[part 1 of 2: packages /AUTOSAR_Dcm/SwComponentTypes to /AUTOSAR_Dcm/PortInterfaces]
AUTOSAR XML (schema 4-2-2)
package /AUTOSAR_Dcm/SwComponentTypes
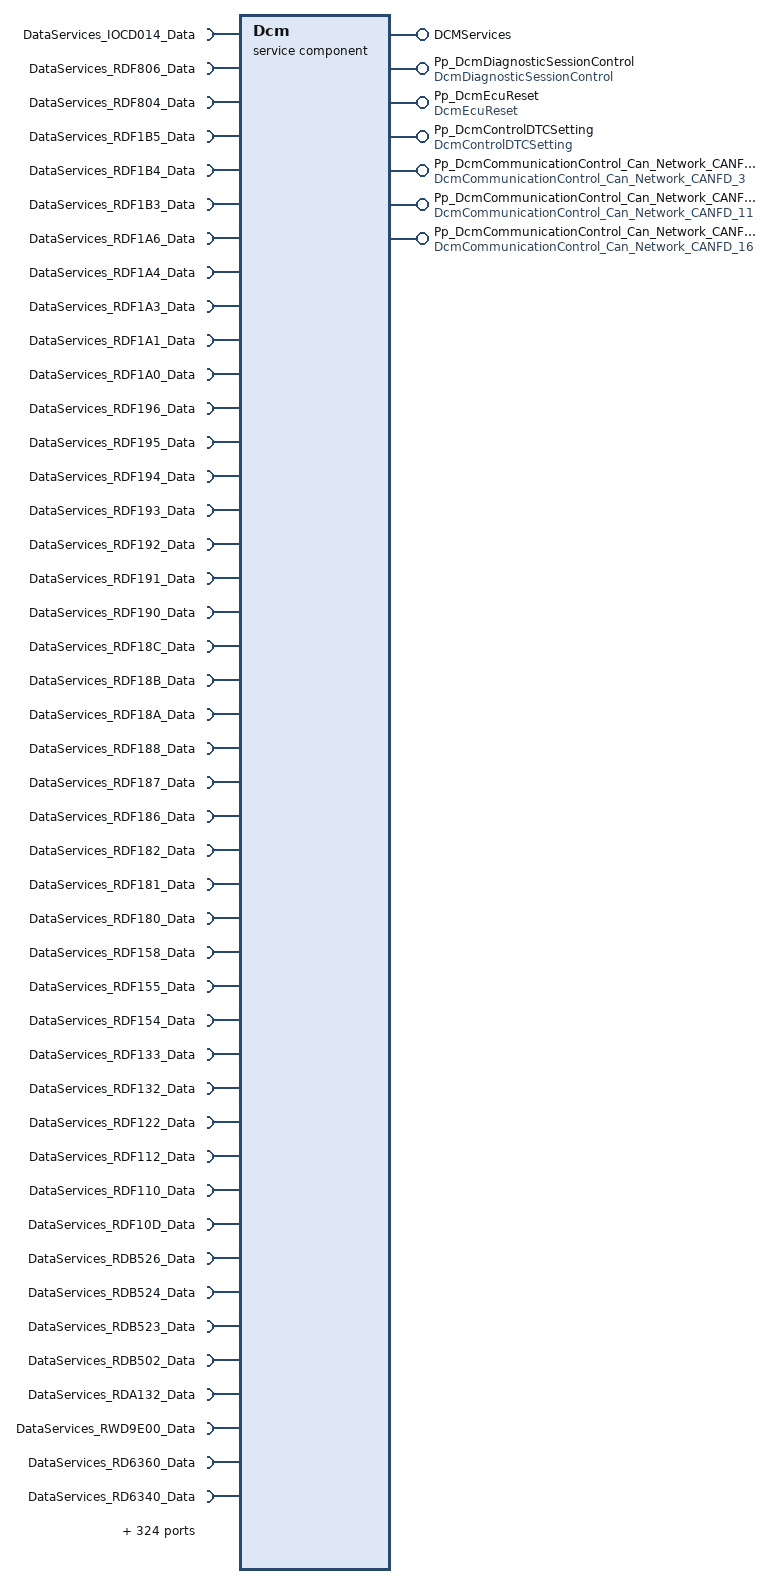
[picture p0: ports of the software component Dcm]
  service sw component type Dcm
    7 x provide port:
      DCMServices: provided-interface=DCMServices
        provided-com-specs:
          operation=GetActiveProtocol, queue-length=1
          operation=SetActiveDiagnostic, queue-length=1
          operation=GetSesCtrlType, queue-length=1
          operation=GetSecurityLevel, queue-length=1
          operation=ResetToDefaultSession, queue-length=1
      Pp_DcmDiagnosticSessionControl: mode-switch-sender-com-spec{mode-group=MDGP_DcmDiagnosticSessionControl, queue-length=1}, provided-interface=DcmDiagnosticSessionControl
      Pp_DcmEcuReset: mode-switch-sender-com-spec{mode-group=MDGP_DcmEcuReset, queue-length=1}, provided-interface=DcmEcuReset
      Pp_DcmControlDTCSetting: mode-switch-sender-com-spec{mode-group=MDGP_DcmControlDTCSetting, queue-length=1}, provided-interface=DcmControlDTCSetting
      Pp_DcmCommunicationControl_Can_Network_CANFD_3: mode-switch-sender-com-spec{mode-group=MDGP_DcmCommunicationControl_Can_Network_CANFD_3, queue-length=1}, provided-interface=DcmCommunicationControl_Can_Network_CANFD_3
      Pp_DcmCommunicationControl_Can_Network_CANFD_11: mode-switch-sender-com-spec{mode-group=MDGP_DcmCommunicationControl_Can_Network_CANFD_11, queue-length=1}, provided-interface=DcmCommunicationControl_Can_Network_CANFD_11
      Pp_DcmCommunicationControl_Can_Network_CANFD_16: mode-switch-sender-com-spec{mode-group=MDGP_DcmCommunicationControl_Can_Network_CANFD_16, queue-length=1}, provided-interface=DcmCommunicationControl_Can_Network_CANFD_16
    371 x require port:
      DataServices_IOCD014_Data: required-interface=DataServices_IOCD014_Data
      DataServices_RDF806_Data: required-interface=DataServices_RDF806_Data
      DataServices_RDF804_Data: required-interface=DataServices_RDF804_Data
      DataServices_RDF1B5_Data: required-interface=DataServices_RDF1B5_Data
      DataServices_RDF1B4_Data: required-interface=DataServices_RDF1B4_Data
      DataServices_RDF1B3_Data: required-interface=DataServices_RDF1B3_Data
      DataServices_RDF1A6_Data: required-interface=DataServices_RDF1A6_Data
      DataServices_RDF1A4_Data: required-interface=DataServices_RDF1A4_Data
      DataServices_RDF1A3_Data: required-interface=DataServices_RDF1A3_Data
      DataServices_RDF1A1_Data: required-interface=DataServices_RDF1A1_Data
      DataServices_RDF1A0_Data: required-interface=DataServices_RDF1A0_Data
      DataServices_RDF196_Data: required-interface=DataServices_RDF196_Data
      DataServices_RDF195_Data: required-interface=DataServices_RDF195_Data
      DataServices_RDF194_Data: required-interface=DataServices_RDF194_Data
      DataServices_RDF193_Data: required-interface=DataServices_RDF193_Data
      DataServices_RDF192_Data: required-interface=DataServices_RDF192_Data
      DataServices_RDF191_Data: required-interface=DataServices_RDF191_Data
      DataServices_RDF190_Data: required-interface=DataServices_RDF190_Data
      DataServices_RDF18C_Data: required-interface=DataServices_RDF18C_Data
      DataServices_RDF18B_Data: required-interface=DataServices_RDF18B_Data
      DataServices_RDF18A_Data: required-interface=DataServices_RDF18A_Data
      DataServices_RDF188_Data: required-interface=DataServices_RDF188_Data
      DataServices_RDF187_Data: required-interface=DataServices_RDF187_Data
      DataServices_RDF186_Data: required-interface=DataServices_RDF186_Data
      DataServices_RDF182_Data: required-interface=DataServices_RDF182_Data
      DataServices_RDF181_Data: required-interface=DataServices_RDF181_Data
      DataServices_RDF180_Data: required-interface=DataServices_RDF180_Data
      DataServices_RDF158_Data: required-interface=DataServices_RDF158_Data
      DataServices_RDF155_Data: required-interface=DataServices_RDF155_Data
      DataServices_RDF154_Data: required-interface=DataServices_RDF154_Data
      DataServices_RDF133_Data: required-interface=DataServices_RDF133_Data
      DataServices_RDF132_Data: required-interface=DataServices_RDF132_Data
      DataServices_RDF122_Data: required-interface=DataServices_RDF122_Data
      DataServices_RDF112_Data: required-interface=DataServices_RDF112_Data
      DataServices_RDF110_Data: required-interface=DataServices_RDF110_Data
      DataServices_RDF10D_Data: required-interface=DataServices_RDF10D_Data
      DataServices_RDB526_Data: required-interface=DataServices_RDB526_Data
      DataServices_RDB524_Data: required-interface=DataServices_RDB524_Data
      DataServices_RDB523_Data: required-interface=DataServices_RDB523_Data
      DataServices_RDB502_Data: required-interface=DataServices_RDB502_Data
      DataServices_RDA132_Data: required-interface=DataServices_RDA132_Data
      DataServices_RWD9E00_Data: required-interface=DataServices_RWD9E00_Data
      DataServices_RD6360_Data: required-interface=DataServices_RD6360_Data
      DataServices_RD6340_Data: required-interface=DataServices_RD6340_Data
      DataServices_RD6330_Data: required-interface=DataServices_RD6330_Data
      DataServices_RD6320_Data: required-interface=DataServices_RD6320_Data
      DataServices_RD4056_Data: required-interface=DataServices_RD4056_Data
      DataServices_RD4055_Data: required-interface=DataServices_RD4055_Data
      DataServices_RD4051_Data: required-interface=DataServices_RD4051_Data
      DataServices_RD4050_Data: required-interface=DataServices_RD4050_Data
      DataServices_RD4040_Data: required-interface=DataServices_RD4040_Data
      DataServices_RD403D_Data: required-interface=DataServices_RD403D_Data
      DataServices_RD4039_Data: required-interface=DataServices_RD4039_Data
      DataServices_RD4037_Data: required-interface=DataServices_RD4037_Data
      DataServices_RD4036_Data: required-interface=DataServices_RD4036_Data
      DataServices_RD4022_Data: required-interface=DataServices_RD4022_Data
      DataServices_RDB616_Data: required-interface=DataServices_RDB616_Data
      DataServices_RDB614_Data: required-interface=DataServices_RDB614_Data
      DataServices_RD401C_Data: required-interface=DataServices_RD401C_Data
      DataServices_RD4016_Data: required-interface=DataServices_RD4016_Data
      DataServices_RD4015_Data: required-interface=DataServices_RD4015_Data
      DataServices_RD4014_Data: required-interface=DataServices_RD4014_Data
      DataServices_RD4013_Data: required-interface=DataServices_RD4013_Data
      DataServices_RD4012_Data: required-interface=DataServices_RD4012_Data
      DataServices_RD4011_Data: required-interface=DataServices_RD4011_Data
      DataServices_RD4010_Data: required-interface=DataServices_RD4010_Data
      DataServices_RD400E_Data: required-interface=DataServices_RD400E_Data
      DataServices_RD4004_Data: required-interface=DataServices_RD4004_Data
      DataServices_RD4002_Data: required-interface=DataServices_RD4002_Data
      DataServices_RD4001_Data: required-interface=DataServices_RD4001_Data
      DataServices_RD4000_Data: required-interface=DataServices_RD4000_Data
      DataServices_RWD3202_Data: required-interface=DataServices_RWD3202_Data
      DataServices_RD3201_Data: required-interface=DataServices_RD3201_Data
      DataServices_RD3200_Data: required-interface=DataServices_RD3200_Data
      DataServices_RD3035_Data: required-interface=DataServices_RD3035_Data
      DataServices_RWD3029_Data: required-interface=DataServices_RWD3029_Data
      DataServices_RD3028_Data: required-interface=DataServices_RD3028_Data
      DataServices_RD3027_Data: required-interface=DataServices_RD3027_Data
      DataServices_RWD3025_Data: required-interface=DataServices_RWD3025_Data
      DataServices_RD3006_Data: required-interface=DataServices_RD3006_Data
      DataServices_RD3005_Data: required-interface=DataServices_RD3005_Data
      DataServices_RD3004_Data: required-interface=DataServices_RD3004_Data
      DataServices_RD3002_Data: required-interface=DataServices_RD3002_Data
      DataServices_RWD2945_Data: required-interface=DataServices_RWD2945_Data
      DataServices_RD2948_Data: required-interface=DataServices_RD2948_Data
      DataServices_RD2947_Data: required-interface=DataServices_RD2947_Data
      DataServices_RD293A_Data: required-interface=DataServices_RD293A_Data
      DataServices_RD2802_Data: required-interface=DataServices_RD2802_Data
      DataServices_RD2505_Data: required-interface=DataServices_RD2505_Data
      DataServices_RD2500_Data: required-interface=DataServices_RD2500_Data
      DataServices_RDB000_Data: required-interface=DataServices_RDB000_Data
      DataServices_RD2026_Data: required-interface=DataServices_RD2026_Data
      DataServices_RD201B_Data: required-interface=DataServices_RD201B_Data
      DataServices_RD201A_Data: required-interface=DataServices_RD201A_Data
      DataServices_RD2010_Data: required-interface=DataServices_RD2010_Data
      DataServices_RD200C_Data: required-interface=DataServices_RD200C_Data
      DataServices_RD200B_Data: required-interface=DataServices_RD200B_Data
      DataServices_RD200A_Data: required-interface=DataServices_RD200A_Data
      DataServices_RD2008_Data: required-interface=DataServices_RD2008_Data
      DataServices_RD2003_Data: required-interface=DataServices_RD2003_Data
      DataServices_RD2002_Data: required-interface=DataServices_RD2002_Data
      DataServices_RD2001_Data: required-interface=DataServices_RD2001_Data
      DataServices_RD1921_Data: required-interface=DataServices_RD1921_Data
      DataServices_RD100C_Data: required-interface=DataServices_RD100C_Data
      DataServices_RD1009_Data: required-interface=DataServices_RD1009_Data
      DataServices_RD1008_Data: required-interface=DataServices_RD1008_Data
      DataServices_RD1006_Data: required-interface=DataServices_RD1006_Data
      DataServices_RD1004_Data: required-interface=DataServices_RD1004_Data
      DataServices_RD1002_Data: required-interface=DataServices_RD1002_Data
      DataServices_RD1000_Data: required-interface=DataServices_RD1000_Data
      DataServices_RD0804_Data: required-interface=DataServices_RD0804_Data
      DataServices_RD0803_Data: required-interface=DataServices_RD0803_Data
      DataServices_RD0802_Data: required-interface=DataServices_RD0802_Data
      DataServices_RD0703_Data: required-interface=DataServices_RD0703_Data
      DataServices_RD0702_Data: required-interface=DataServices_RD0702_Data
      DataServices_RD0701_Data: required-interface=DataServices_RD0701_Data
      DataServices_RD0700_Data: required-interface=DataServices_RD0700_Data
      DataServices_RD0507_Data: required-interface=DataServices_RD0507_Data
      DataServices_RD0307_Data: required-interface=DataServices_RD0307_Data
      DataServices_RD0306_Data: required-interface=DataServices_RD0306_Data
      DataServices_RD0301_Data: required-interface=DataServices_RD0301_Data
      DataServices_RWD0107_Data: required-interface=DataServices_RWD0107_Data
      DataServices_RD0103_Data: required-interface=DataServices_RD0103_Data
      DataServices_RDB650_Data: required-interface=DataServices_RDB650_Data
      DataServices_RDB651_Data: required-interface=DataServices_RDB651_Data
      DataServices_RWDB652_Data: required-interface=DataServices_RWDB652_Data
      DataServices_RDB776_Data: required-interface=DataServices_RDB776_Data
      DataServices_RDF1B0_Data: required-interface=DataServices_RDF1B0_Data
      DataServices_RDB64A_Data: required-interface=DataServices_RDB64A_Data
      DataServices_RDB649_Data: required-interface=DataServices_RDB649_Data
      DataServices_RDB645_Data: required-interface=DataServices_RDB645_Data
      DataServices_RDB646_Data: required-interface=DataServices_RDB646_Data
      DataServices_RDB64D_Data: required-interface=DataServices_RDB64D_Data
      DataServices_RDB79F_Data: required-interface=DataServices_RDB79F_Data
      DataServices_RDB79E_Data: required-interface=DataServices_RDB79E_Data
      DataServices_RDB78E_Data: required-interface=DataServices_RDB78E_Data
      DataServices_RDB78D_Data: required-interface=DataServices_RDB78D_Data
      DataServices_RDB655_Data: required-interface=DataServices_RDB655_Data
      DataServices_RDB653_Data: required-interface=DataServices_RDB653_Data
      DataServices_RDB654_Data: required-interface=DataServices_RDB654_Data
      DataServices_RD191D_Data: required-interface=DataServices_RD191D_Data
      DataServices_RDB775_Data: required-interface=DataServices_RDB775_Data
      DataServices_RWDB61B_Data: required-interface=DataServices_RWDB61B_Data
      DataServices_RDB700_Data: required-interface=DataServices_RDB700_Data
      DataServices_RWDB701_Data: required-interface=DataServices_RWDB701_Data
      DataServices_RDF1B7_Data: required-interface=DataServices_RDF1B7_Data
      DataServices_RDB528_Data: required-interface=DataServices_RDB528_Data
      DataServices_IOCD018_Data: required-interface=DataServices_IOCD018_Data
      DataServices_RD2037_Data: required-interface=DataServices_RD2037_Data
      DataServices_RD2036_Data: required-interface=DataServices_RD2036_Data
      DataServices_RD2035_Data: required-interface=DataServices_RD2035_Data
      DataServices_RD2034_Data: required-interface=DataServices_RD2034_Data
      DataServices_RD2032_Data: required-interface=DataServices_RD2032_Data
      DataServices_RDF1BC_Data: required-interface=DataServices_RDF1BC_Data
      DataServices_RDF1BB_Data: required-interface=DataServices_RDF1BB_Data
      DataServices_RDF1BA_Data: required-interface=DataServices_RDF1BA_Data
      DataServices_RDF1B9_Data: required-interface=DataServices_RDF1B9_Data
      DataServices_RWDB78C_Data: required-interface=DataServices_RWDB78C_Data
      DataServices_RWD9EEB_Data: required-interface=DataServices_RWD9EEB_Data
      DataServices_RWD9EEC_Data: required-interface=DataServices_RWD9EEC_Data
      DataServices_RD2024_Data: required-interface=DataServices_RD2024_Data
      DataServices_RDF111_Data: required-interface=DataServices_RDF111_Data
      DataServices_RD292E_Data: required-interface=DataServices_RD292E_Data
      DataServices_RD2801_Data: required-interface=DataServices_RD2801_Data
      DataServices_RDB62B_Data: required-interface=DataServices_RDB62B_Data
      DataServices_RDB629_Data: required-interface=DataServices_RDB629_Data
      DataServices_RDB62A_Data: required-interface=DataServices_RDB62A_Data
      DataServices_RDB628_Data: required-interface=DataServices_RDB628_Data
      DataServices_RDB626_Data: required-interface=DataServices_RDB626_Data
      DataServices_RDB627_Data: required-interface=DataServices_RDB627_Data
      DataServices_RDB64B_Data: required-interface=DataServices_RDB64B_Data
      DataServices_RD2954_Data: required-interface=DataServices_RD2954_Data
      DataServices_RD201E_Data: required-interface=DataServices_RD201E_Data
      DataServices_RD3036_Data: required-interface=DataServices_RD3036_Data
      DataServices_RD100A_Data: required-interface=DataServices_RD100A_Data
      DataServices_RDB78B_Data: required-interface=DataServices_RDB78B_Data
      DataServices_RD9EED_Data: required-interface=DataServices_RD9EED_Data
      DataServices_RWD9E3B_Data: required-interface=DataServices_RWD9E3B_Data
      DataServices_RWD9E15_Data: required-interface=DataServices_RWD9E15_Data
      DataServices_RWD2800_Data: required-interface=DataServices_RWD2800_Data
      DataServices_RWD9E22_Data: required-interface=DataServices_RWD9E22_Data
      DataServices_RWD9E23_Data: required-interface=DataServices_RWD9E23_Data
      DataServices_RWD9E20_Data: required-interface=DataServices_RWD9E20_Data
      DataServices_RWD9E21_Data: required-interface=DataServices_RWD9E21_Data
      DataServices_RWDB607_Data: required-interface=DataServices_RWDB607_Data
      DataServices_RDB613_Data: required-interface=DataServices_RDB613_Data
      DataServices_RD400C_Data: required-interface=DataServices_RD400C_Data
      DataServices_RD400A_Data: required-interface=DataServices_RD400A_Data
      DataServices_RDB522_Data: required-interface=DataServices_RDB522_Data
      DataServices_RDB612_Data: required-interface=DataServices_RDB612_Data
      DataServices_RDB778_Data: required-interface=DataServices_RDB778_Data
      DataServices_RDB798_Data: required-interface=DataServices_RDB798_Data
      DataServices_RDB777_Data: required-interface=DataServices_RDB777_Data
      DataServices_RD295C_Data: required-interface=DataServices_RD295C_Data
      DataServices_RD295B_Data: required-interface=DataServices_RD295B_Data
      DataServices_RDF1C2_Data: required-interface=DataServices_RDF1C2_Data
      DataServices_RD2958_Data: required-interface=DataServices_RD2958_Data
      DataServices_RD2957_Data: required-interface=DataServices_RD2957_Data
      DataServices_RD295A_Data: required-interface=DataServices_RD295A_Data
      DataServices_RD2959_Data: required-interface=DataServices_RD2959_Data
      DataServices_RD4021_Data: required-interface=DataServices_RD4021_Data
      DataServices_RDF1B8_Data: required-interface=DataServices_RDF1B8_Data
      DataServices_RDB79A_Data: required-interface=DataServices_RDB79A_Data
      DataServices_RDB79B_Data: required-interface=DataServices_RDB79B_Data
      DataServices_RDB647_Data: required-interface=DataServices_RDB647_Data
      DataServices_RDB648_Data: required-interface=DataServices_RDB648_Data
      DataServices_RDB64E_Data: required-interface=DataServices_RDB64E_Data
      DataServices_RDF1A9_Data: required-interface=DataServices_RDF1A9_Data
      DataServices_RDF1A7_Data: required-interface=DataServices_RDF1A7_Data
      DataServices_RDF1A8_Data: required-interface=DataServices_RDF1A8_Data
      DataServices_RD2943_Data: required-interface=DataServices_RD2943_Data
      DataServices_RDB521_Data: required-interface=DataServices_RDB521_Data
      DataServices_RDB789_Data: required-interface=DataServices_RDB789_Data
      DataServices_RDB642_Data: required-interface=DataServices_RDB642_Data
      DataServices_RDB771_Data: required-interface=DataServices_RDB771_Data
      DataServices_RDF1AA_Data: required-interface=DataServices_RDF1AA_Data
      DataServices_RDB786_Data: required-interface=DataServices_RDB786_Data
      DataServices_RDB785_Data: required-interface=DataServices_RDB785_Data
      DataServices_RDB784_Data: required-interface=DataServices_RDB784_Data
      DataServices_RDB782_Data: required-interface=DataServices_RDB782_Data
      DataServices_RDB781_Data: required-interface=DataServices_RDB781_Data
      DataServices_RDB780_Data: required-interface=DataServices_RDB780_Data
      DataServices_RD401F_Data: required-interface=DataServices_RD401F_Data
      DataServices_RDB520_Data: required-interface=DataServices_RDB520_Data
      DataServices_RD4003_Data: required-interface=DataServices_RD4003_Data
      DataServices_RWD3833_Data: required-interface=DataServices_RWD3833_Data
      DataServices_RD2009_Data: required-interface=DataServices_RD2009_Data
      DataServices_RDF1BD_Data: required-interface=DataServices_RDF1BD_Data
      DataServices_RDF10B_Data: required-interface=DataServices_RDF10B_Data
      DataServices_RDF1B6_Data: required-interface=DataServices_RDF1B6_Data
      DataServices_RWD2969_Data: required-interface=DataServices_RWD2969_Data
      DataServices_RDB79D_Data: required-interface=DataServices_RDB79D_Data
      DataServices_RDB79C_Data: required-interface=DataServices_RDB79C_Data
      DataServices_RDB64C_Data: required-interface=DataServices_RDB64C_Data
      DataServices_RD100B_Data: required-interface=DataServices_RD100B_Data
      DataServices_RDB783_Data: required-interface=DataServices_RDB783_Data
      DataServices_RD295E_Data: required-interface=DataServices_RD295E_Data
      DataServices_RD295F_Data: required-interface=DataServices_RD295F_Data
      DataServices_RDB799_Data: required-interface=DataServices_RDB799_Data
      DataServices_RWDB604_Data: required-interface=DataServices_RWDB604_Data
      DataServices_RDB605_Data: required-interface=DataServices_RDB605_Data
      DataServices_RD2965_Data: required-interface=DataServices_RD2965_Data
      DataServices_RD2967_Data: required-interface=DataServices_RD2967_Data
      DataServices_RD1927_Data: required-interface=DataServices_RD1927_Data
      DataServices_RD295D_Data: required-interface=DataServices_RD295D_Data
      DataServices_RDB7BA_Data: required-interface=DataServices_RDB7BA_Data
      DataServices_RDF134_Data: required-interface=DataServices_RDF134_Data
      DataServices_RDF1C7_Data: required-interface=DataServices_RDF1C7_Data
      DataServices_RD102A_Data: required-interface=DataServices_RD102A_Data
      DataServices_RD2955_Data: required-interface=DataServices_RD2955_Data
      DataServices_RD2951_Data: required-interface=DataServices_RD2951_Data
      DataServices_RWD2966_Data: required-interface=DataServices_RWD2966_Data
      DataServices_RDF1C6_Data: required-interface=DataServices_RDF1C6_Data
      DataServices_RD2956_Data: required-interface=DataServices_RD2956_Data
      DataServices_RDB774_Data: required-interface=DataServices_RDB774_Data
      DataServices_RDB772_Data: required-interface=DataServices_RDB772_Data
      DataServices_RD201F_Data: required-interface=DataServices_RD201F_Data
      DataServices_RDB773_Data: required-interface=DataServices_RDB773_Data
      DataServices_RDB779_Data: required-interface=DataServices_RDB779_Data
      DataServices_RD2030_Data: required-interface=DataServices_RD2030_Data
      DataServices_RD2031_Data: required-interface=DataServices_RD2031_Data
      DataServices_RD0108_Data: required-interface=DataServices_RD0108_Data
      DataServices_RDB78A_Data: required-interface=DataServices_RDB78A_Data
      DataServices_RD1204_Data: required-interface=DataServices_RD1204_Data
      DataServices_RD1206_Data: required-interface=DataServices_RD1206_Data
      DataServices_RD19B{0..3}_Data: required-interface=DataServices_RD19B{0..3}_Data
      DataServices_RDB622_Data: required-interface=DataServices_RDB622_Data
      DataServices_RDB621_Data: required-interface=DataServices_RDB621_Data
      DataServices_RDA186_Data: required-interface=DataServices_RDA186_Data
      DataServices_RDB630_Data: required-interface=DataServices_RDB630_Data
      DataServices_RWDB62F_Data: required-interface=DataServices_RWDB62F_Data
      DataServices_RDB634_Data: required-interface=DataServices_RDB634_Data
      DataServices_RDB633_Data: required-interface=DataServices_RDB633_Data
      DataServices_RDB632_Data: required-interface=DataServices_RDB632_Data
      DataServices_RDB631_Data: required-interface=DataServices_RDB631_Data
      DataServices_WDF185_Data: required-interface=DataServices_WDF185_Data
      DataServices_WDF184_Data: required-interface=DataServices_WDF184_Data
      DataServices_WDF183_Data: required-interface=DataServices_WDF183_Data
      DataServices_WD2023_Data: required-interface=DataServices_WD2023_Data
      DataServices_IOCD046_Data: required-interface=DataServices_IOCD046_Data
      DataServices_IOCD045_Data: required-interface=DataServices_IOCD045_Data
      DataServices_IOCD042_Data: required-interface=DataServices_IOCD042_Data
      DataServices_IOCD033_Data: required-interface=DataServices_IOCD033_Data
      DataServices_IOCD032_Data: required-interface=DataServices_IOCD032_Data
      DataServices_IOCD031_Data: required-interface=DataServices_IOCD031_Data
      DataServices_IOCD030_Data: required-interface=DataServices_IOCD030_Data
      DataServices_IOCD028_Data: required-interface=DataServices_IOCD028_Data
      DataServices_IOCD027_Data: required-interface=DataServices_IOCD027_Data
      DataServices_IOCD026_Data: required-interface=DataServices_IOCD026_Data
      DataServices_IOCD025_Data: required-interface=DataServices_IOCD025_Data
      DataServices_IOCD023_Data: required-interface=DataServices_IOCD023_Data
      DataServices_IOCD022_Data: required-interface=DataServices_IOCD022_Data
      DataServices_IOCD020_Data: required-interface=DataServices_IOCD020_Data
      DataServices_IOCD01F_Data: required-interface=DataServices_IOCD01F_Data
      DataServices_IOCD01E_Data: required-interface=DataServices_IOCD01E_Data
      DataServices_IOCD01C_Data: required-interface=DataServices_IOCD01C_Data
      DataServices_IOCD019_Data: required-interface=DataServices_IOCD019_Data
      DataServices_IOCD017_Data: required-interface=DataServices_IOCD017_Data
      DataServices_IOCD016_Data: required-interface=DataServices_IOCD016_Data
      DataServices_IOCD013_Data: required-interface=DataServices_IOCD013_Data
      DataServices_IOCD012_Data: required-interface=DataServices_IOCD012_Data
      DataServices_IOCD00D_Data: required-interface=DataServices_IOCD00D_Data
      DataServices_IOCD006_Data: required-interface=DataServices_IOCD006_Data
      DataServices_IOCD004_Data: required-interface=DataServices_IOCD004_Data
      DataServices_IOCD002_Data: required-interface=DataServices_IOCD002_Data
      DataServices_IOCD001_Data: required-interface=DataServices_IOCD001_Data
      SecurityAccess_Authenticated_Diagnostic_Access_SecurityAccess: required-interface=SecurityAccess_Authenticated_Diagnostic_Access_SecurityAccess
      SecurityAccess_Authenticated_Diagnostic_Access_SecurityAccess_Even: required-interface=SecurityAccess_Authenticated_Diagnostic_Access_SecurityAccess_Even
      RoutineServices_RCFF01: required-interface=RoutineServices_RCFF01
      RoutineServices_RCFF00: required-interface=RoutineServices_RCFF00
      RoutineServices_RCF000: required-interface=RoutineServices_RCF000
      RoutineServices_RCD00A: required-interface=RoutineServices_RCD00A
      RoutineServices_RCD008: required-interface=RoutineServices_RCD008
      RoutineServices_RCD007: required-interface=RoutineServices_RCD007
      RoutineServices_RCD006: required-interface=RoutineServices_RCD006
      RoutineServices_RCD004: required-interface=RoutineServices_RCD004
      RoutineServices_RCD003: required-interface=RoutineServices_RCD003
      RoutineServices_RCD002: required-interface=RoutineServices_RCD002
      RoutineServices_RCD001: required-interface=RoutineServices_RCD001
      RoutineServices_RCD000: required-interface=RoutineServices_RCD000
      RoutineServices_RC2002: required-interface=RoutineServices_RC2002
      RoutineServices_RC2001: required-interface=RoutineServices_RC2001
      RoutineServices_RC2000: required-interface=RoutineServices_RC2000
      RoutineServices_RC1336: required-interface=RoutineServices_RC1336
      RoutineServices_RC1335: required-interface=RoutineServices_RC1335
      RoutineServices_RC1334: required-interface=RoutineServices_RC1334
      RoutineServices_RC1333: required-interface=RoutineServices_RC1333
      RoutineServices_RC1332: required-interface=RoutineServices_RC1332
      RoutineServices_RC1330: required-interface=RoutineServices_RC1330
      RoutineServices_RC1314: required-interface=RoutineServices_RC1314
      RoutineServices_RC1313: required-interface=RoutineServices_RC1313
      RoutineServices_RC1311: required-interface=RoutineServices_RC1311
      RoutineServices_RC130F: required-interface=RoutineServices_RC130F
      RoutineServices_RC130E: required-interface=RoutineServices_RC130E
      RoutineServices_RC130D: required-interface=RoutineServices_RC130D
      RoutineServices_RC130C: required-interface=RoutineServices_RC130C
      RoutineServices_RC130B: required-interface=RoutineServices_RC130B
      RoutineServices_RC1309: required-interface=RoutineServices_RC1309
      RoutineServices_RC1303: required-interface=RoutineServices_RC1303
      RoutineServices_RC1300: required-interface=RoutineServices_RC1300
      RoutineServices_RC02CD: required-interface=RoutineServices_RC02CD
      RoutineServices_RC02CC: required-interface=RoutineServices_RC02CC
      RoutineServices_RC02C8: required-interface=RoutineServices_RC02C8
      RoutineServices_RC02C7: required-interface=RoutineServices_RC02C7
      RoutineServices_RC02C0: required-interface=RoutineServices_RC02C0
      RoutineServices_RC02B2: required-interface=RoutineServices_RC02B2
      R_DataServices_SID01PID04_Current_data: required-interface=DataServices_SID01PID04_Current_data
      R_DataServices_SID01PID05_Current_data: required-interface=DataServices_SID01PID05_Current_data
      R_DataServices_SID01PID0C_Current_data: required-interface=DataServices_SID01PID0C_Current_data
      R_DataServices_SID01PID0D_Current_data: required-interface=DataServices_SID01PID0D_Current_data
      R_DataServices_SID01PID33_Current_data: required-interface=DataServices_SID01PID33_Current_data
      R_DataServices_SID01PID42_Current_data: required-interface=DataServices_SID01PID42_Current_data
      R_DataServices_SID01PID46_Current_data: required-interface=DataServices_SID01PID46_Current_data
      R_DataServices_SID01PID49_Current_data: required-interface=DataServices_SID01PID49_Current_data
      R_DataServices_SID01PID5B_Current_data: required-interface=DataServices_SID01PID5B_Current_data
      R_DataServices_SID01PID01_Current_data: required-interface=DataServices_SID01PID01_Current_data
      R_DataServices_SID01PID21_Current_data: required-interface=DataServices_SID01PID21_Current_data
      R_DataServices_SID01PID30_Current_data: required-interface=DataServices_SID01PID30_Current_data
      R_DataServices_SID01PID31_Current_data: required-interface=DataServices_SID01PID31_Current_data
      R_DataServices_SID01PID41_Current_data: required-interface=DataServices_SID01PID41_Current_data
      R_DataServices_SID01PID9A_Current_data: required-interface=DataServices_SID01PID9A_Current_data
      InfotypeServices_PID_0x09_0x1C_HybrdVehGrdDat_Data: required-interface=InfotypeServices_PID_0x09_0x1C_HybrdVehGrdDat_Data
      InfotypeServices_PID_0x09_0x1B_HybrdVehFuelDat_Data: required-interface=InfotypeServices_PID_0x09_0x1B_HybrdVehFuelDat_Data
      InfotypeServices_PID_0x09_0x1A_HybrdVehDistDat_Data: required-interface=InfotypeServices_PID_0x09_0x1A_HybrdVehDistDat_Data
      InfotypeServices_PID_0x09_0x16_VehOpeDatEngRunIdlTim_Data: required-interface=InfotypeServices_PID_0x09_0x16_VehOpeDatEngRunIdlTim_Data
      InfotypeServices_PID_0x09_0x0A_ECUName_Data: required-interface=InfotypeServices_PID_0x09_0x0A_ECUName_Data
      InfotypeServices_PID_0x09_0x06_CVN_Data: required-interface=InfotypeServices_PID_0x09_0x06_CVN_Data
      InfotypeServices_PID_0x09_0x04_CalID_Data: required-interface=InfotypeServices_PID_0x09_0x04_CalID_Data
    behavior IntBeh_Dcm: data-type-mapping=[DTS_DcmDiagnosticSessionControl, DTS_DcmEcuReset, DTS_DcmControlDTCSetting, DTS_DcmCommunicationControl_Can_Network_CANFD_3, DTS_DcmCommunicationControl_Can_Network_CANFD_11, DTS_DcmCommunicationControl_Can_Network_CANFD_16], included-data-type-set=data-type=[Dcm_SecLevelType, Dcm_SesCtrlType, Dcm_ProtocolType, Dcm_NegativeResponseCodeType, Dcm_ConfirmationStatusType, Dcm_OpStatusType, Dcm_DidSupportedType]
      5 x operation invoked event:
        OpInvEvent_DCMServices_GAP: start-on-event=Dcm_GetActiveProtocol, operation=DCMServices.GetActiveProtocol
        OpInvEvent_DCMServices_SAD: start-on-event=Dcm_SetActiveDiagnostic, operation=DCMServices.SetActiveDiagnostic
        OpInvEvent_DCMServices_GSCT: start-on-event=Dcm_GetSesCtrlType, operation=DCMServices.GetSesCtrlType
        OpInvEvent_DCMServices_GSL: start-on-event=Dcm_GetSecurityLevel, operation=DCMServices.GetSecurityLevel
        OpInvEvent_DCMServices_RD: start-on-event=Dcm_ResetToDefaultSession, operation=DCMServices.ResetToDefaultSession
      port-api-options:
        enable-take-address=true, indirect-api=false, port=DataServices_IOCD014_Data
        enable-take-address=true, indirect-api=false, port=DataServices_RDF806_Data
        enable-take-address=true, indirect-api=false, port=DataServices_RDF804_Data
        enable-take-address=true, indirect-api=false, port=DataServices_RDF1B5_Data
        enable-take-address=true, indirect-api=false, port=DataServices_RDF1B4_Data
        enable-take-address=true, indirect-api=false, port=DataServices_RDF1B3_Data
        enable-take-address=true, indirect-api=false, port=DataServices_RDF1A6_Data
        enable-take-address=true, indirect-api=false, port=DataServices_RDF1A4_Data
        enable-take-address=true, indirect-api=false, port=DataServices_RDF1A3_Data
        enable-take-address=true, indirect-api=false, port=DataServices_RDF1A1_Data
        enable-take-address=true, indirect-api=false, port=DataServices_RDF1A0_Data
        enable-take-address=true, indirect-api=false, port=DataServices_RDF196_Data
        enable-take-address=true, indirect-api=false, port=DataServices_RDF195_Data
        enable-take-address=true, indirect-api=false, port=DataServices_RDF194_Data
        enable-take-address=true, indirect-api=false, port=DataServices_RDF193_Data
        enable-take-address=true, indirect-api=false, port=DataServices_RDF192_Data
        enable-take-address=true, indirect-api=false, port=DataServices_RDF191_Data
        enable-take-address=true, indirect-api=false, port=DataServices_RDF190_Data
        enable-take-address=true, indirect-api=false, port=DataServices_RDF18C_Data
        enable-take-address=true, indirect-api=false, port=DataServices_RDF18B_Data
        enable-take-address=true, indirect-api=false, port=DataServices_RDF18A_Data
        enable-take-address=true, indirect-api=false, port=DataServices_RDF188_Data
        enable-take-address=true, indirect-api=false, port=DataServices_RDF187_Data
        enable-take-address=true, indirect-api=false, port=DataServices_RDF186_Data
        enable-take-address=true, indirect-api=false, port=DataServices_RDF182_Data
        enable-take-address=true, indirect-api=false, port=DataServices_RDF181_Data
        enable-take-address=true, indirect-api=false, port=DataServices_RDF180_Data
        enable-take-address=true, indirect-api=false, port=DataServices_RDF158_Data
        enable-take-address=true, indirect-api=false, port=DataServices_RDF155_Data
        enable-take-address=true, indirect-api=false, port=DataServices_RDF154_Data
        enable-take-address=true, indirect-api=false, port=DataServices_RDF133_Data
        enable-take-address=true, indirect-api=false, port=DataServices_RDF132_Data
        enable-take-address=true, indirect-api=false, port=DataServices_RDF122_Data
        enable-take-address=true, indirect-api=false, port=DataServices_RDF112_Data
        enable-take-address=true, indirect-api=false, port=DataServices_RDF110_Data
        enable-take-address=true, indirect-api=false, port=DataServices_RDF10D_Data
        enable-take-address=true, indirect-api=false, port=DataServices_RDB526_Data
        enable-take-address=true, indirect-api=false, port=DataServices_RDB524_Data
        enable-take-address=true, indirect-api=false, port=DataServices_RDB523_Data
        enable-take-address=true, indirect-api=false, port=DataServices_RDB502_Data
        enable-take-address=true, indirect-api=false, port=DataServices_RDA132_Data
        enable-take-address=true, indirect-api=false, port=DataServices_RWD9E00_Data
        enable-take-address=true, indirect-api=false, port=DataServices_RD6360_Data
        enable-take-address=true, indirect-api=false, port=DataServices_RD6340_Data
        enable-take-address=true, indirect-api=false, port=DataServices_RD6330_Data
        enable-take-address=true, indirect-api=false, port=DataServices_RD6320_Data
        enable-take-address=true, indirect-api=false, port=DataServices_RD4056_Data
        enable-take-address=true, indirect-api=false, port=DataServices_RD4055_Data
        enable-take-address=true, indirect-api=false, port=DataServices_RD4051_Data
        enable-take-address=true, indirect-api=false, port=DataServices_RD4050_Data
        enable-take-address=true, indirect-api=false, port=DataServices_RD4040_Data
        enable-take-address=true, indirect-api=false, port=DataServices_RD403D_Data
        enable-take-address=true, indirect-api=false, port=DataServices_RD4039_Data
        enable-take-address=true, indirect-api=false, port=DataServices_RD4037_Data
        enable-take-address=true, indirect-api=false, port=DataServices_RD4036_Data
        enable-take-address=true, indirect-api=false, port=DataServices_RD4022_Data
        enable-take-address=true, indirect-api=false, port=DataServices_RDB616_Data
        enable-take-address=true, indirect-api=false, port=DataServices_RDB614_Data
        enable-take-address=true, indirect-api=false, port=DataServices_RD401C_Data
        enable-take-address=true, indirect-api=false, port=DataServices_RD4016_Data
        enable-take-address=true, indirect-api=false, port=DataServices_RD4015_Data
        enable-take-address=true, indirect-api=false, port=DataServices_RD4014_Data
        enable-take-address=true, indirect-api=false, port=DataServices_RD4013_Data
        enable-take-address=true, indirect-api=false, port=DataServices_RD4012_Data
        enable-take-address=true, indirect-api=false, port=DataServices_RD4011_Data
        enable-take-address=true, indirect-api=false, port=DataServices_RD4010_Data
        enable-take-address=true, indirect-api=false, port=DataServices_RD400E_Data
        enable-take-address=true, indirect-api=false, port=DataServices_RD4004_Data
        enable-take-address=true, indirect-api=false, port=DataServices_RD4002_Data
        enable-take-address=true, indirect-api=false, port=DataServices_RD4001_Data
        enable-take-address=true, indirect-api=false, port=DataServices_RD4000_Data
        enable-take-address=true, indirect-api=false, port=DataServices_RWD3202_Data
        enable-take-address=true, indirect-api=false, port=DataServices_RD3201_Data
        enable-take-address=true, indirect-api=false, port=DataServices_RD3200_Data
        enable-take-address=true, indirect-api=false, port=DataServices_RD3035_Data
        enable-take-address=true, indirect-api=false, port=DataServices_RWD3029_Data
        enable-take-address=true, indirect-api=false, port=DataServices_RD3028_Data
        enable-take-address=true, indirect-api=false, port=DataServices_RD3027_Data
        enable-take-address=true, indirect-api=false, port=DataServices_RWD3025_Data
        enable-take-address=true, indirect-api=false, port=DataServices_RD3006_Data
        enable-take-address=true, indirect-api=false, port=DataServices_RD3005_Data
        enable-take-address=true, indirect-api=false, port=DataServices_RD3004_Data
        enable-take-address=true, indirect-api=false, port=DataServices_RD3002_Data
        enable-take-address=true, indirect-api=false, port=DataServices_RWD2945_Data
        enable-take-address=true, indirect-api=false, port=DataServices_RD2948_Data
        enable-take-address=true, indirect-api=false, port=DataServices_RD2947_Data
        enable-take-address=true, indirect-api=false, port=DataServices_RD293A_Data
        enable-take-address=true, indirect-api=false, port=DataServices_RD2802_Data
        enable-take-address=true, indirect-api=false, port=DataServices_RD2505_Data
        enable-take-address=true, indirect-api=false, port=DataServices_RD2500_Data
        enable-take-address=true, indirect-api=false, port=DataServices_RDB000_Data
        enable-take-address=true, indirect-api=false, port=DataServices_RD2026_Data
        enable-take-address=true, indirect-api=false, port=DataServices_RD201B_Data
        enable-take-address=true, indirect-api=false, port=DataServices_RD201A_Data
        enable-take-address=true, indirect-api=false, port=DataServices_RD2010_Data
        enable-take-address=true, indirect-api=false, port=DataServices_RD200C_Data
        enable-take-address=true, indirect-api=false, port=DataServices_RD200B_Data
        enable-take-address=true, indirect-api=false, port=DataServices_RD200A_Data
        enable-take-address=true, indirect-api=false, port=DataServices_RD2008_Data
        enable-take-address=true, indirect-api=false, port=DataServices_RD2003_Data
        enable-take-address=true, indirect-api=false, port=DataServices_RD2002_Data
        enable-take-address=true, indirect-api=false, port=DataServices_RD2001_Data
        enable-take-address=true, indirect-api=false, port=DataServices_RD1921_Data
        enable-take-address=true, indirect-api=false, port=DataServices_RD100C_Data
        enable-take-address=true, indirect-api=false, port=DataServices_RD1009_Data
        enable-take-address=true, indirect-api=false, port=DataServices_RD1008_Data
        enable-take-address=true, indirect-api=false, port=DataServices_RD1006_Data
        enable-take-address=true, indirect-api=false, port=DataServices_RD1004_Data
        enable-take-address=true, indirect-api=false, port=DataServices_RD1002_Data
        enable-take-address=true, indirect-api=false, port=DataServices_RD1000_Data
        enable-take-address=true, indirect-api=false, port=DataServices_RD0804_Data
        enable-take-address=true, indirect-api=false, port=DataServices_RD0803_Data
        enable-take-address=true, indirect-api=false, port=DataServices_RD0802_Data
        enable-take-address=true, indirect-api=false, port=DataServices_RD0703_Data
        enable-take-address=true, indirect-api=false, port=DataServices_RD0702_Data
        enable-take-address=true, indirect-api=false, port=DataServices_RD0701_Data
        enable-take-address=true, indirect-api=false, port=DataServices_RD0700_Data
        enable-take-address=true, indirect-api=false, port=DataServices_RD0507_Data
        enable-take-address=true, indirect-api=false, port=DataServices_RD0307_Data
        enable-take-address=true, indirect-api=false, port=DataServices_RD0306_Data
        enable-take-address=true, indirect-api=false, port=DataServices_RD0301_Data
        enable-take-address=true, indirect-api=false, port=DataServices_RWD0107_Data
        enable-take-address=true, indirect-api=false, port=DataServices_RD0103_Data
        enable-take-address=true, indirect-api=false, port=DataServices_RDB650_Data
        enable-take-address=true, indirect-api=false, port=DataServices_RDB651_Data
        enable-take-address=true, indirect-api=false, port=DataServices_RWDB652_Data
        enable-take-address=true, indirect-api=false, port=DataServices_RDB776_Data
        enable-take-address=true, indirect-api=false, port=DataServices_RDF1B0_Data
        enable-take-address=true, indirect-api=false, port=DataServices_RDB64A_Data
        enable-take-address=true, indirect-api=false, port=DataServices_RDB649_Data
        enable-take-address=true, indirect-api=false, port=DataServices_RDB645_Data
        enable-take-address=true, indirect-api=false, port=DataServices_RDB646_Data
        enable-take-address=true, indirect-api=false, port=DataServices_RDB64D_Data
        enable-take-address=true, indirect-api=false, port=DataServices_RDB79F_Data
        enable-take-address=true, indirect-api=false, port=DataServices_RDB79E_Data
        enable-take-address=true, indirect-api=false, port=DataServices_RDB78E_Data
        enable-take-address=true, indirect-api=false, port=DataServices_RDB78D_Data
        enable-take-address=true, indirect-api=false, port=DataServices_RDB655_Data
        enable-take-address=true, indirect-api=false, port=DataServices_RDB653_Data
        enable-take-address=true, indirect-api=false, port=DataServices_RDB654_Data
        enable-take-address=true, indirect-api=false, port=DataServices_RD191D_Data
        enable-take-address=true, indirect-api=false, port=DataServices_RDB775_Data
        enable-take-address=true, indirect-api=false, port=DataServices_RWDB61B_Data
        enable-take-address=true, indirect-api=false, port=DataServices_RDB700_Data
        enable-take-address=true, indirect-api=false, port=DataServices_RWDB701_Data
        enable-take-address=true, indirect-api=false, port=DataServices_RDF1B7_Data
        enable-take-address=true, indirect-api=false, port=DataServices_RDB528_Data
        enable-take-address=true, indirect-api=false, port=DataServices_IOCD018_Data
        enable-take-address=true, indirect-api=false, port=DataServices_RD2037_Data
        enable-take-address=true, indirect-api=false, port=DataServices_RD2036_Data
        enable-take-address=true, indirect-api=false, port=DataServices_RD2035_Data
        enable-take-address=true, indirect-api=false, port=DataServices_RD2034_Data
        enable-take-address=true, indirect-api=false, port=DataServices_RD2032_Data
        enable-take-address=true, indirect-api=false, port=DataServices_RDF1BC_Data
        enable-take-address=true, indirect-api=false, port=DataServices_RDF1BB_Data
        enable-take-address=true, indirect-api=false, port=DataServices_RDF1BA_Data
        enable-take-address=true, indirect-api=false, port=DataServices_RDF1B9_Data
        enable-take-address=true, indirect-api=false, port=DataServices_RWDB78C_Data
        enable-take-address=true, indirect-api=false, port=DataServices_RWD9EEB_Data
        enable-take-address=true, indirect-api=false, port=DataServices_RWD9EEC_Data
        enable-take-address=true, indirect-api=false, port=DataServices_RD2024_Data
        enable-take-address=true, indirect-api=false, port=DataServices_RDF111_Data
        enable-take-address=true, indirect-api=false, port=DataServices_RD292E_Data
        enable-take-address=true, indirect-api=false, port=DataServices_RD2801_Data
        enable-take-address=true, indirect-api=false, port=DataServices_RDB62B_Data
        enable-take-address=true, indirect-api=false, port=DataServices_RDB629_Data
        enable-take-address=true, indirect-api=false, port=DataServices_RDB62A_Data
        enable-take-address=true, indirect-api=false, port=DataServices_RDB628_Data
        enable-take-address=true, indirect-api=false, port=DataServices_RDB626_Data
        enable-take-address=true, indirect-api=false, port=DataServices_RDB627_Data
        enable-take-address=true, indirect-api=false, port=DataServices_RDB64B_Data
        enable-take-address=true, indirect-api=false, port=DataServices_RD2954_Data
        enable-take-address=true, indirect-api=false, port=DataServices_RD201E_Data
        enable-take-address=true, indirect-api=false, port=DataServices_RD3036_Data
        enable-take-address=true, indirect-api=false, port=DataServices_RD100A_Data
        enable-take-address=true, indirect-api=false, port=DataServices_RDB78B_Data
        enable-take-address=true, indirect-api=false, port=DataServices_RD9EED_Data
        enable-take-address=true, indirect-api=false, port=DataServices_RWD9E3B_Data
        enable-take-address=true, indirect-api=false, port=DataServices_RWD9E15_Data
        enable-take-address=true, indirect-api=false, port=DataServices_RWD2800_Data
        enable-take-address=true, indirect-api=false, port=DataServices_RWD9E22_Data
        enable-take-address=true, indirect-api=false, port=DataServices_RWD9E23_Data
        enable-take-address=true, indirect-api=false, port=DataServices_RWD9E20_Data
        enable-take-address=true, indirect-api=false, port=DataServices_RWD9E21_Data
        enable-take-address=true, indirect-api=false, port=DataServices_RWDB607_Data
        enable-take-address=true, indirect-api=false, port=DataServices_RDB613_Data
        enable-take-address=true, indirect-api=false, port=DataServices_RD400C_Data
        enable-take-address=true, indirect-api=false, port=DataServices_RD400A_Data
        enable-take-address=true, indirect-api=false, port=DataServices_RDB522_Data
        enable-take-address=true, indirect-api=false, port=DataServices_RDB612_Data
        enable-take-address=true, indirect-api=false, port=DataServices_RDB778_Data
        enable-take-address=true, indirect-api=false, port=DataServices_RDB798_Data
        enable-take-address=true, indirect-api=false, port=DataServices_RDB777_Data
        enable-take-address=true, indirect-api=false, port=DataServices_RD295C_Data
        enable-take-address=true, indirect-api=false, port=DataServices_RD295B_Data
        enable-take-address=true, indirect-api=false, port=DataServices_RDF1C2_Data
        enable-take-address=true, indirect-api=false, port=DataServices_RD2958_Data
        enable-take-address=true, indirect-api=false, port=DataServices_RD2957_Data
        enable-take-address=true, indirect-api=false, port=DataServices_RD295A_Data
        enable-take-address=true, indirect-api=false, port=DataServices_RD2959_Data
        enable-take-address=true, indirect-api=false, port=DataServices_RD4021_Data
        enable-take-address=true, indirect-api=false, port=DataServices_RDF1B8_Data
        enable-take-address=true, indirect-api=false, port=DataServices_RDB79A_Data
        enable-take-address=true, indirect-api=false, port=DataServices_RDB79B_Data
        enable-take-address=true, indirect-api=false, port=DataServices_RDB647_Data
        enable-take-address=true, indirect-api=false, port=DataServices_RDB648_Data
        enable-take-address=true, indirect-api=false, port=DataServices_RDB64E_Data
        enable-take-address=true, indirect-api=false, port=DataServices_RDF1A9_Data
        enable-take-address=true, indirect-api=false, port=DataServices_RDF1A7_Data
        enable-take-address=true, indirect-api=false, port=DataServices_RDF1A8_Data
        enable-take-address=true, indirect-api=false, port=DataServices_RD2943_Data
        enable-take-address=true, indirect-api=false, port=DataServices_RDB521_Data
        enable-take-address=true, indirect-api=false, port=DataServices_RDB789_Data
        enable-take-address=true, indirect-api=false, port=DataServices_RDB642_Data
        enable-take-address=true, indirect-api=false, port=DataServices_RDB771_Data
        enable-take-address=true, indirect-api=false, port=DataServices_RDF1AA_Data
        enable-take-address=true, indirect-api=false, port=DataServices_RDB786_Data
        enable-take-address=true, indirect-api=false, port=DataServices_RDB785_Data
        enable-take-address=true, indirect-api=false, port=DataServices_RDB784_Data
        enable-take-address=true, indirect-api=false, port=DataServices_RDB782_Data
        enable-take-address=true, indirect-api=false, port=DataServices_RDB781_Data
        enable-take-address=true, indirect-api=false, port=DataServices_RDB780_Data
        enable-take-address=true, indirect-api=false, port=DataServices_RD401F_Data
        enable-take-address=true, indirect-api=false, port=DataServices_RDB520_Data
        enable-take-address=true, indirect-api=false, port=DataServices_RD4003_Data
        enable-take-address=true, indirect-api=false, port=DataServices_RWD3833_Data
        enable-take-address=true, indirect-api=false, port=DataServices_RD2009_Data
        enable-take-address=true, indirect-api=false, port=DataServices_RDF1BD_Data
        enable-take-address=true, indirect-api=false, port=DataServices_RDF10B_Data
        enable-take-address=true, indirect-api=false, port=DataServices_RDF1B6_Data
        enable-take-address=true, indirect-api=false, port=DataServices_RWD2969_Data
        enable-take-address=true, indirect-api=false, port=DataServices_RDB79D_Data
        enable-take-address=true, indirect-api=false, port=DataServices_RDB79C_Data
        enable-take-address=true, indirect-api=false, port=DataServices_RDB64C_Data
        enable-take-address=true, indirect-api=false, port=DataServices_RD100B_Data
        enable-take-address=true, indirect-api=false, port=DataServices_RDB783_Data
        enable-take-address=true, indirect-api=false, port=DataServices_RD295E_Data
        enable-take-address=true, indirect-api=false, port=DataServices_RD295F_Data
        enable-take-address=true, indirect-api=false, port=DataServices_RDB799_Data
        enable-take-address=true, indirect-api=false, port=DataServices_RWDB604_Data
        enable-take-address=true, indirect-api=false, port=DataServices_RDB605_Data
        enable-take-address=true, indirect-api=false, port=DataServices_RD2965_Data
        enable-take-address=true, indirect-api=false, port=DataServices_RD2967_Data
        enable-take-address=true, indirect-api=false, port=DataServices_RD1927_Data
        enable-take-address=true, indirect-api=false, port=DataServices_RD295D_Data
        enable-take-address=true, indirect-api=false, port=DataServices_RDB7BA_Data
        enable-take-address=true, indirect-api=false, port=DataServices_RDF134_Data
        enable-take-address=true, indirect-api=false, port=DataServices_RDF1C7_Data
        enable-take-address=true, indirect-api=false, port=DataServices_RD102A_Data
        enable-take-address=true, indirect-api=false, port=DataServices_RD2955_Data
        enable-take-address=true, indirect-api=false, port=DataServices_RD2951_Data
        enable-take-address=true, indirect-api=false, port=DataServices_RWD2966_Data
        enable-take-address=true, indirect-api=false, port=DataServices_RDF1C6_Data
        enable-take-address=true, indirect-api=false, port=DataServices_RD2956_Data
        enable-take-address=true, indirect-api=false, port=DataServices_RDB774_Data
        enable-take-address=true, indirect-api=false, port=DataServices_RDB772_Data
        enable-take-address=true, indirect-api=false, port=DataServices_RD201F_Data
        enable-take-address=true, indirect-api=false, port=DataServices_RDB773_Data
        enable-take-address=true, indirect-api=false, port=DataServices_RDB779_Data
        enable-take-address=true, indirect-api=false, port=DataServices_RD2030_Data
        enable-take-address=true, indirect-api=false, port=DataServices_RD2031_Data
        enable-take-address=true, indirect-api=false, port=DataServices_RD0108_Data
        enable-take-address=true, indirect-api=false, port=DataServices_RDB78A_Data
        enable-take-address=true, indirect-api=false, port=DataServices_RD1204_Data
        enable-take-address=true, indirect-api=false, port=DataServices_RD1206_Data
        enable-take-address=true, indirect-api=false, port=DataServices_RD19B{0..3}_Data
        enable-take-address=true, indirect-api=false, port=DataServices_RDB622_Data
        enable-take-address=true, indirect-api=false, port=DataServices_RDB621_Data
        enable-take-address=true, indirect-api=false, port=DataServices_RDA186_Data
        enable-take-address=true, indirect-api=false, port=DataServices_RDB630_Data
        enable-take-address=true, indirect-api=false, port=DataServices_RWDB62F_Data
        enable-take-address=true, indirect-api=false, port=DataServices_RDB634_Data
        enable-take-address=true, indirect-api=false, port=DataServices_RDB633_Data
        enable-take-address=true, indirect-api=false, port=DataServices_RDB632_Data
        enable-take-address=true, indirect-api=false, port=DataServices_RDB631_Data
        enable-take-address=true, indirect-api=false, port=DataServices_WDF185_Data
        enable-take-address=true, indirect-api=false, port=DataServices_WDF184_Data
        enable-take-address=true, indirect-api=false, port=DataServices_WDF183_Data
        enable-take-address=true, indirect-api=false, port=DataServices_WD2023_Data
        enable-take-address=true, indirect-api=false, port=DataServices_IOCD046_Data
        enable-take-address=true, indirect-api=false, port=DataServices_IOCD045_Data
        enable-take-address=true, indirect-api=false, port=DataServices_IOCD042_Data
        enable-take-address=true, indirect-api=false, port=DataServices_IOCD033_Data
        enable-take-address=true, indirect-api=false, port=DataServices_IOCD032_Data
        enable-take-address=true, indirect-api=false, port=DataServices_IOCD031_Data
        enable-take-address=true, indirect-api=false, port=DataServices_IOCD030_Data
        enable-take-address=true, indirect-api=false, port=DataServices_IOCD028_Data
        enable-take-address=true, indirect-api=false, port=DataServices_IOCD027_Data
        enable-take-address=true, indirect-api=false, port=DataServices_IOCD026_Data
        enable-take-address=true, indirect-api=false, port=DataServices_IOCD025_Data
        enable-take-address=true, indirect-api=false, port=DataServices_IOCD023_Data
        enable-take-address=true, indirect-api=false, port=DataServices_IOCD022_Data
        enable-take-address=true, indirect-api=false, port=DataServices_IOCD020_Data
        enable-take-address=true, indirect-api=false, port=DataServices_IOCD01F_Data
        enable-take-address=true, indirect-api=false, port=DataServices_IOCD01E_Data
        enable-take-address=true, indirect-api=false, port=DataServices_IOCD01C_Data
        enable-take-address=true, indirect-api=false, port=DataServices_IOCD019_Data
        enable-take-address=true, indirect-api=false, port=DataServices_IOCD017_Data
        enable-take-address=true, indirect-api=false, port=DataServices_IOCD016_Data
        enable-take-address=true, indirect-api=false, port=DataServices_IOCD013_Data
        enable-take-address=true, indirect-api=false, port=DataServices_IOCD012_Data
        enable-take-address=true, indirect-api=false, port=DataServices_IOCD00D_Data
        enable-take-address=true, indirect-api=false, port=DataServices_IOCD006_Data
        enable-take-address=true, indirect-api=false, port=DataServices_IOCD004_Data
        enable-take-address=true, indirect-api=false, port=DataServices_IOCD002_Data
        enable-take-address=true, indirect-api=false, port=DataServices_IOCD001_Data
        enable-take-address=true, indirect-api=false, port=SecurityAccess_Authenticated_Diagnostic_Access_SecurityAccess
        enable-take-address=true, indirect-api=false, port=SecurityAccess_Authenticated_Diagnostic_Access_SecurityAccess_Even
        enable-take-address=true, indirect-api=false, port=RoutineServices_RCFF01
        enable-take-address=true, indirect-api=false, port=RoutineServices_RCFF00
        enable-take-address=true, indirect-api=false, port=RoutineServices_RCF000
        enable-take-address=true, indirect-api=false, port=RoutineServices_RCD00A
        enable-take-address=true, indirect-api=false, port=RoutineServices_RCD008
        enable-take-address=true, indirect-api=false, port=RoutineServices_RCD007
        enable-take-address=true, indirect-api=false, port=RoutineServices_RCD006
        enable-take-address=true, indirect-api=false, port=RoutineServices_RCD004
        enable-take-address=true, indirect-api=false, port=RoutineServices_RCD003
        enable-take-address=true, indirect-api=false, port=RoutineServices_RCD002
        enable-take-address=true, indirect-api=false, port=RoutineServices_RCD001
        enable-take-address=true, indirect-api=false, port=RoutineServices_RCD000
        enable-take-address=true, indirect-api=false, port=RoutineServices_RC2002
        enable-take-address=true, indirect-api=false, port=RoutineServices_RC2001
        enable-take-address=true, indirect-api=false, port=RoutineServices_RC2000
        enable-take-address=true, indirect-api=false, port=RoutineServices_RC1336
        enable-take-address=true, indirect-api=false, port=RoutineServices_RC1335
        enable-take-address=true, indirect-api=false, port=RoutineServices_RC1334
        enable-take-address=true, indirect-api=false, port=RoutineServices_RC1333
        enable-take-address=true, indirect-api=false, port=RoutineServices_RC1332
        enable-take-address=true, indirect-api=false, port=RoutineServices_RC1330
        enable-take-address=true, indirect-api=false, port=RoutineServices_RC1314
        enable-take-address=true, indirect-api=false, port=RoutineServices_RC1313
        enable-take-address=true, indirect-api=false, port=RoutineServices_RC1311
        enable-take-address=true, indirect-api=false, port=RoutineServices_RC130F
        enable-take-address=true, indirect-api=false, port=RoutineServices_RC130E
        enable-take-address=true, indirect-api=false, port=RoutineServices_RC130D
        enable-take-address=true, indirect-api=false, port=RoutineServices_RC130C
        enable-take-address=true, indirect-api=false, port=RoutineServices_RC130B
        enable-take-address=true, indirect-api=false, port=RoutineServices_RC1309
        enable-take-address=true, indirect-api=false, port=RoutineServices_RC1303
        enable-take-address=true, indirect-api=false, port=RoutineServices_RC1300
        enable-take-address=true, indirect-api=false, port=RoutineServices_RC02CD
        enable-take-address=true, indirect-api=false, port=RoutineServices_RC02CC
        enable-take-address=true, indirect-api=false, port=RoutineServices_RC02C8
        enable-take-address=true, indirect-api=false, port=RoutineServices_RC02C7
        enable-take-address=true, indirect-api=false, port=RoutineServices_RC02C0
        enable-take-address=true, indirect-api=false, port=RoutineServices_RC02B2
        enable-take-address=true, indirect-api=false, port=InfotypeServices_PID_0x09_0x1C_HybrdVehGrdDat_Data
        enable-take-address=true, indirect-api=false, port=InfotypeServices_PID_0x09_0x1B_HybrdVehFuelDat_Data
        enable-take-address=true, indirect-api=false, port=InfotypeServices_PID_0x09_0x1A_HybrdVehDistDat_Data
        enable-take-address=true, indirect-api=false, port=InfotypeServices_PID_0x09_0x16_VehOpeDatEngRunIdlTim_Data
        enable-take-address=true, indirect-api=false, port=InfotypeServices_PID_0x09_0x0A_ECUName_Data
        enable-take-address=true, indirect-api=false, port=InfotypeServices_PID_0x09_0x06_CVN_Data
        enable-take-address=true, indirect-api=false, port=InfotypeServices_PID_0x09_0x04_CalID_Data
      7 x runnable:
        Dcm_MainFunction
          data-receive-point-by-arguments:
            15 x access:
              SID01PID04_Current_data_Read: accessed-variable=R_DataServices_SID01PID04_Current_data.Data
              SID01PID05_Current_data_Read: accessed-variable=R_DataServices_SID01PID05_Current_data.Data
              SID01PID0C_Current_data_Read: accessed-variable=R_DataServices_SID01PID0C_Current_data.Data
              SID01PID0D_Current_data_Read: accessed-variable=R_DataServices_SID01PID0D_Current_data.Data
              SID01PID33_Current_data_Read: accessed-variable=R_DataServices_SID01PID33_Current_data.Data
              SID01PID42_Current_data_Read: accessed-variable=R_DataServices_SID01PID42_Current_data.Data
              SID01PID46_Current_data_Read: accessed-variable=R_DataServices_SID01PID46_Current_data.Data
              SID01PID49_Current_data_Read: accessed-variable=R_DataServices_SID01PID49_Current_data.Data
              SID01PID5B_Current_data_Read: accessed-variable=R_DataServices_SID01PID5B_Current_data.Data
              SID01PID01_Current_data_Read: accessed-variable=R_DataServices_SID01PID01_Current_data.Data
              SID01PID21_Current_data_Read: accessed-variable=R_DataServices_SID01PID21_Current_data.Data
              SID01PID30_Current_data_Read: accessed-variable=R_DataServices_SID01PID30_Current_data.Data
              SID01PID31_Current_data_Read: accessed-variable=R_DataServices_SID01PID31_Current_data.Data
              SID01PID41_Current_data_Read: accessed-variable=R_DataServices_SID01PID41_Current_data.Data
              SID01PID9A_Current_data_Read: accessed-variable=R_DataServices_SID01PID9A_Current_data.Data
          6 x mode switch point:
            ModeSwitchPoint_0: mode-group=Pp_DcmDiagnosticSessionControl.MDGP_DcmDiagnosticSessionControl
            ModeSwitchPoint_1: mode-group=Pp_DcmEcuReset.MDGP_DcmEcuReset
            ModeSwitchPoint_3: mode-group=Pp_DcmControlDTCSetting.MDGP_DcmControlDTCSetting
            ModeSwitchPoint_Can_Network_CANFD_3: mode-group=Pp_DcmCommunicationControl_Can_Network_CANFD_3.MDGP_DcmCommunicationControl_Can_Network_CANFD_3
            ModeSwitchPoint_Can_Network_CANFD_11: mode-group=Pp_DcmCommunicationControl_Can_Network_CANFD_11.MDGP_DcmCommunicationControl_Can_Network_CANFD_11
            ModeSwitchPoint_Can_Network_CANFD_16: mode-group=Pp_DcmCommunicationControl_Can_Network_CANFD_16.MDGP_DcmCommunicationControl_Can_Network_CANFD_16
          480 x sync call, all with timeout=0.0:
            DataServices_IOCD014_Data_RData: operation=DataServices_IOCD014_Data.ReadData
            DataServices_IOCD014_Data_RCE: operation=DataServices_IOCD014_Data.ReturnControlToECU
            DataServices_IOCD014_Data_RD: operation=DataServices_IOCD014_Data.ResetToDefault
            DataServices_IOCD014_Data_STA: operation=DataServices_IOCD014_Data.ShortTermAdjustment
            DataServices_RDF806_Data_RData: operation=DataServices_RDF806_Data.ReadData
            DataServices_RDF804_Data_RData: operation=DataServices_RDF804_Data.ReadData
            DataServices_RDF1B5_Data_RData: operation=DataServices_RDF1B5_Data.ReadData
            DataServices_RDF1B4_Data_RData: operation=DataServices_RDF1B4_Data.ReadData
            DataServices_RDF1B3_Data_RData: operation=DataServices_RDF1B3_Data.ReadData
            DataServices_RDF1A6_Data_RData: operation=DataServices_RDF1A6_Data.ReadData
            DataServices_RDF1A4_Data_RData: operation=DataServices_RDF1A4_Data.ReadData
            DataServices_RDF1A3_Data_RData: operation=DataServices_RDF1A3_Data.ReadData
            DataServices_RDF1A1_Data_RData: operation=DataServices_RDF1A1_Data.ReadData
            DataServices_RDF1A0_Data_RData: operation=DataServices_RDF1A0_Data.ReadData
            DataServices_RDF196_Data_RData: operation=DataServices_RDF196_Data.ReadData
            DataServices_RDF195_Data_RData: operation=DataServices_RDF195_Data.ReadData
            DataServices_RDF194_Data_RData: operation=DataServices_RDF194_Data.ReadData
            DataServices_RDF193_Data_RData: operation=DataServices_RDF193_Data.ReadData
            DataServices_RDF192_Data_RData: operation=DataServices_RDF192_Data.ReadData
            DataServices_RDF191_Data_RData: operation=DataServices_RDF191_Data.ReadData
            DataServices_RDF190_Data_RData: operation=DataServices_RDF190_Data.ReadData
            DataServices_RDF18C_Data_RData: operation=DataServices_RDF18C_Data.ReadData
            DataServices_RDF18B_Data_RData: operation=DataServices_RDF18B_Data.ReadData
            DataServices_RDF18A_Data_RData: operation=DataServices_RDF18A_Data.ReadData
            DataServices_RDF188_Data_RData: operation=DataServices_RDF188_Data.ReadData
            DataServices_RDF187_Data_RData: operation=DataServices_RDF187_Data.ReadData
            DataServices_RDF186_Data_RData: operation=DataServices_RDF186_Data.ReadData
            DataServices_RDF182_Data_RData: operation=DataServices_RDF182_Data.ReadData
            DataServices_RDF181_Data_RData: operation=DataServices_RDF181_Data.ReadData
            DataServices_RDF180_Data_RData: operation=DataServices_RDF180_Data.ReadData
            DataServices_RDF158_Data_RData: operation=DataServices_RDF158_Data.ReadData
            DataServices_RDF155_Data_RData: operation=DataServices_RDF155_Data.ReadData
            DataServices_RDF154_Data_RData: operation=DataServices_RDF154_Data.ReadData
            DataServices_RDF133_Data_RData: operation=DataServices_RDF133_Data.ReadData
            DataServices_RDF132_Data_RData: operation=DataServices_RDF132_Data.ReadData
            DataServices_RDF122_Data_RData: operation=DataServices_RDF122_Data.ReadData
            DataServices_RDF112_Data_RData: operation=DataServices_RDF112_Data.ReadData
            DataServices_RDF110_Data_RData: operation=DataServices_RDF110_Data.ReadData
            DataServices_RDF10D_Data_RData: operation=DataServices_RDF10D_Data.ReadData
            DataServices_RDB526_Data_RData: operation=DataServices_RDB526_Data.ReadData
            DataServices_RDB524_Data_RData: operation=DataServices_RDB524_Data.ReadData
            DataServices_RDB523_Data_RData: operation=DataServices_RDB523_Data.ReadData
            DataServices_RDB502_Data_RData: operation=DataServices_RDB502_Data.ReadData
            DataServices_RDA132_Data_RData: operation=DataServices_RDA132_Data.ReadData
            DataServices_RWD9E00_Data_RData: operation=DataServices_RWD9E00_Data.ReadData
            DataServices_RWD9E00_Data_WData: operation=DataServices_RWD9E00_Data.WriteData
            DataServices_RD6360_Data_RData: operation=DataServices_RD6360_Data.ReadData
            DataServices_RD6340_Data_RData: operation=DataServices_RD6340_Data.ReadData
            DataServices_RD6330_Data_RData: operation=DataServices_RD6330_Data.ReadData
            DataServices_RD6320_Data_RData: operation=DataServices_RD6320_Data.ReadData
            DataServices_RD4056_Data_RData: operation=DataServices_RD4056_Data.ReadData
            DataServices_RD4055_Data_RData: operation=DataServices_RD4055_Data.ReadData
            DataServices_RD4051_Data_RData: operation=DataServices_RD4051_Data.ReadData
            DataServices_RD4050_Data_RData: operation=DataServices_RD4050_Data.ReadData
            DataServices_RD4040_Data_RData: operation=DataServices_RD4040_Data.ReadData
            DataServices_RD403D_Data_RData: operation=DataServices_RD403D_Data.ReadData
            DataServices_RD4039_Data_RData: operation=DataServices_RD4039_Data.ReadData
            DataServices_RD4037_Data_RData: operation=DataServices_RD4037_Data.ReadData
            DataServices_RD4036_Data_RData: operation=DataServices_RD4036_Data.ReadData
            DataServices_RD4022_Data_RData: operation=DataServices_RD4022_Data.ReadData
            DataServices_RDB616_Data_RData: operation=DataServices_RDB616_Data.ReadData
            DataServices_RDB614_Data_RData: operation=DataServices_RDB614_Data.ReadData
            DataServices_RD401C_Data_RData: operation=DataServices_RD401C_Data.ReadData
            DataServices_RD4016_Data_RData: operation=DataServices_RD4016_Data.ReadData
            DataServices_RD4015_Data_RData: operation=DataServices_RD4015_Data.ReadData
            DataServices_RD4014_Data_RData: operation=DataServices_RD4014_Data.ReadData
            DataServices_RD4013_Data_RData: operation=DataServices_RD4013_Data.ReadData
            DataServices_RD4012_Data_RData: operation=DataServices_RD4012_Data.ReadData
            DataServices_RD4011_Data_RData: operation=DataServices_RD4011_Data.ReadData
            DataServices_RD4010_Data_RData: operation=DataServices_RD4010_Data.ReadData
            DataServices_RD400E_Data_RData: operation=DataServices_RD400E_Data.ReadData
            DataServices_RD4004_Data_RData: operation=DataServices_RD4004_Data.ReadData
            DataServices_RD4002_Data_RData: operation=DataServices_RD4002_Data.ReadData
            DataServices_RD4001_Data_RData: operation=DataServices_RD4001_Data.ReadData
            DataServices_RD4000_Data_RData: operation=DataServices_RD4000_Data.ReadData
            DataServices_RWD3202_Data_RData: operation=DataServices_RWD3202_Data.ReadData
            DataServices_RWD3202_Data_WData: operation=DataServices_RWD3202_Data.WriteData
            DataServices_RD3201_Data_RData: operation=DataServices_RD3201_Data.ReadData
            DataServices_RD3200_Data_RData: operation=DataServices_RD3200_Data.ReadData
            DataServices_RD3035_Data_RData: operation=DataServices_RD3035_Data.ReadData
            DataServices_RWD3029_Data_RData: operation=DataServices_RWD3029_Data.ReadData
            DataServices_RWD3029_Data_WData: operation=DataServices_RWD3029_Data.WriteData
            DataServices_RD3028_Data_RData: operation=DataServices_RD3028_Data.ReadData
            DataServices_RD3027_Data_RData: operation=DataServices_RD3027_Data.ReadData
            DataServices_RWD3025_Data_RData: operation=DataServices_RWD3025_Data.ReadData
            DataServices_RWD3025_Data_WData: operation=DataServices_RWD3025_Data.WriteData
            DataServices_RD3006_Data_RData: operation=DataServices_RD3006_Data.ReadData
            DataServices_RD3005_Data_RData: operation=DataServices_RD3005_Data.ReadData
            DataServices_RD3004_Data_RData: operation=DataServices_RD3004_Data.ReadData
            DataServices_RD3002_Data_RData: operation=DataServices_RD3002_Data.ReadData
            DataServices_RWD2945_Data_RData: operation=DataServices_RWD2945_Data.ReadData
            DataServices_RWD2945_Data_WData: operation=DataServices_RWD2945_Data.WriteData
            DataServices_RD2948_Data_RData: operation=DataServices_RD2948_Data.ReadData
            DataServices_RD2947_Data_RData: operation=DataServices_RD2947_Data.ReadData
            DataServices_RD293A_Data_RData: operation=DataServices_RD293A_Data.ReadData
            DataServices_RD2802_Data_RData: operation=DataServices_RD2802_Data.ReadData
            DataServices_RD2505_Data_RData: operation=DataServices_RD2505_Data.ReadData
            DataServices_RD2500_Data_RData: operation=DataServices_RD2500_Data.ReadData
            DataServices_RDB000_Data_RData: operation=DataServices_RDB000_Data.ReadData
            DataServices_RD2026_Data_RData: operation=DataServices_RD2026_Data.ReadData
            DataServices_RD201B_Data_RData: operation=DataServices_RD201B_Data.ReadData
            DataServices_RD201A_Data_RData: operation=DataServices_RD201A_Data.ReadData
            DataServices_RD2010_Data_RData: operation=DataServices_RD2010_Data.ReadData
            DataServices_RD200C_Data_RData: operation=DataServices_RD200C_Data.ReadData
            DataServices_RD200B_Data_RData: operation=DataServices_RD200B_Data.ReadData
            DataServices_RD200A_Data_RData: operation=DataServices_RD200A_Data.ReadData
            DataServices_RD2008_Data_RData: operation=DataServices_RD2008_Data.ReadData
            DataServices_RD2003_Data_RData: operation=DataServices_RD2003_Data.ReadData
            DataServices_RD2002_Data_RData: operation=DataServices_RD2002_Data.ReadData
            DataServices_RD2001_Data_RData: operation=DataServices_RD2001_Data.ReadData
            DataServices_RD1921_Data_RData: operation=DataServices_RD1921_Data.ReadData
            DataServices_RD100C_Data_RData: operation=DataServices_RD100C_Data.ReadData
            DataServices_RD1009_Data_RData: operation=DataServices_RD1009_Data.ReadData
            DataServices_RD1008_Data_RData: operation=DataServices_RD1008_Data.ReadData
            DataServices_RD1006_Data_RData: operation=DataServices_RD1006_Data.ReadData
            DataServices_RD1004_Data_RData: operation=DataServices_RD1004_Data.ReadData
            DataServices_RD1002_Data_RData: operation=DataServices_RD1002_Data.ReadData
            DataServices_RD1000_Data_RData: operation=DataServices_RD1000_Data.ReadData
            DataServices_RD0804_Data_RData: operation=DataServices_RD0804_Data.ReadData
            DataServices_RD0803_Data_RData: operation=DataServices_RD0803_Data.ReadData
            DataServices_RD0802_Data_RData: operation=DataServices_RD0802_Data.ReadData
            DataServices_RD0703_Data_RData: operation=DataServices_RD0703_Data.ReadData
            DataServices_RD0702_Data_RData: operation=DataServices_RD0702_Data.ReadData
            DataServices_RD0701_Data_RData: operation=DataServices_RD0701_Data.ReadData
            DataServices_RD0700_Data_RData: operation=DataServices_RD0700_Data.ReadData
            DataServices_RD0507_Data_RData: operation=DataServices_RD0507_Data.ReadData
            DataServices_RD0307_Data_RData: operation=DataServices_RD0307_Data.ReadData
            DataServices_RD0306_Data_RData: operation=DataServices_RD0306_Data.ReadData
            DataServices_RD0301_Data_RData: operation=DataServices_RD0301_Data.ReadData
            DataServices_RWD0107_Data_RData: operation=DataServices_RWD0107_Data.ReadData
            DataServices_RWD0107_Data_WData: operation=DataServices_RWD0107_Data.WriteData
            DataServices_RD0103_Data_RData: operation=DataServices_RD0103_Data.ReadData
            DataServices_RDB650_Data_RData: operation=DataServices_RDB650_Data.ReadData
            DataServices_RDB651_Data_RData: operation=DataServices_RDB651_Data.ReadData
            DataServices_RWDB652_Data_RData: operation=DataServices_RWDB652_Data.ReadData
            DataServices_RWDB652_Data_WData: operation=DataServices_RWDB652_Data.WriteData
            DataServices_RDB776_Data_RData: operation=DataServices_RDB776_Data.ReadData
            DataServices_RDF1B0_Data_RData: operation=DataServices_RDF1B0_Data.ReadData
            DataServices_RDB64A_Data_RData: operation=DataServices_RDB64A_Data.ReadData
            DataServices_RDB649_Data_RData: operation=DataServices_RDB649_Data.ReadData
            DataServices_RDB645_Data_RData: operation=DataServices_RDB645_Data.ReadData
            DataServices_RDB646_Data_RData: operation=DataServices_RDB646_Data.ReadData
            DataServices_RDB64D_Data_RData: operation=DataServices_RDB64D_Data.ReadData
            DataServices_RDB79F_Data_RData: operation=DataServices_RDB79F_Data.ReadData
            DataServices_RDB79E_Data_RData: operation=DataServices_RDB79E_Data.ReadData
            DataServices_RDB78E_Data_RData: operation=DataServices_RDB78E_Data.ReadData
            DataServices_RDB78D_Data_RData: operation=DataServices_RDB78D_Data.ReadData
            DataServices_RDB655_Data_RData: operation=DataServices_RDB655_Data.ReadData
            DataServices_RDB653_Data_RData: operation=DataServices_RDB653_Data.ReadData
            DataServices_RDB654_Data_RData: operation=DataServices_RDB654_Data.ReadData
            DataServices_RD191D_Data_RData: operation=DataServices_RD191D_Data.ReadData
            DataServices_RDB775_Data_RData: operation=DataServices_RDB775_Data.ReadData
            DataServices_RWDB61B_Data_RData: operation=DataServices_RWDB61B_Data.ReadData
            DataServices_RWDB61B_Data_WData: operation=DataServices_RWDB61B_Data.WriteData
            DataServices_RDB700_Data_RData: operation=DataServices_RDB700_Data.ReadData
            DataServices_RWDB701_Data_RData: operation=DataServices_RWDB701_Data.ReadData
            DataServices_RWDB701_Data_WData: operation=DataServices_RWDB701_Data.WriteData
            DataServices_RDF1B7_Data_RData: operation=DataServices_RDF1B7_Data.ReadData
            DataServices_RDB528_Data_RData: operation=DataServices_RDB528_Data.ReadData
            DataServices_IOCD018_Data_RData: operation=DataServices_IOCD018_Data.ReadData
            DataServices_IOCD018_Data_RCE: operation=DataServices_IOCD018_Data.ReturnControlToECU
            DataServices_IOCD018_Data_STA: operation=DataServices_IOCD018_Data.ShortTermAdjustment
            DataServices_RD2037_Data_RData: operation=DataServices_RD2037_Data.ReadData
            DataServices_RD2036_Data_RData: operation=DataServices_RD2036_Data.ReadData
            DataServices_RD2035_Data_RData: operation=DataServices_RD2035_Data.ReadData
            DataServices_RD2034_Data_RData: operation=DataServices_RD2034_Data.ReadData
            DataServices_RD2032_Data_RData: operation=DataServices_RD2032_Data.ReadData
            DataServices_RDF1BC_Data_RData: operation=DataServices_RDF1BC_Data.ReadData
            DataServices_RDF1BB_Data_RData: operation=DataServices_RDF1BB_Data.ReadData
            DataServices_RDF1BA_Data_RData: operation=DataServices_RDF1BA_Data.ReadData
            DataServices_RDF1B9_Data_RData: operation=DataServices_RDF1B9_Data.ReadData
            DataServices_RWDB78C_Data_RData: operation=DataServices_RWDB78C_Data.ReadData
            DataServices_RWDB78C_Data_WData: operation=DataServices_RWDB78C_Data.WriteData
            DataServices_RWD9EEB_Data_RData: operation=DataServices_RWD9EEB_Data.ReadData
            DataServices_RWD9EEB_Data_WData: operation=DataServices_RWD9EEB_Data.WriteData
            DataServices_RWD9EEC_Data_RData: operation=DataServices_RWD9EEC_Data.ReadData
            DataServices_RWD9EEC_Data_WData: operation=DataServices_RWD9EEC_Data.WriteData
            DataServices_RD2024_Data_RData: operation=DataServices_RD2024_Data.ReadData
            DataServices_RDF111_Data_RData: operation=DataServices_RDF111_Data.ReadData
            DataServices_RD292E_Data_RData: operation=DataServices_RD292E_Data.ReadData
            DataServices_RD2801_Data_RData: operation=DataServices_RD2801_Data.ReadData
            DataServices_RDB62B_Data_RData: operation=DataServices_RDB62B_Data.ReadData
            DataServices_RDB629_Data_RData: operation=DataServices_RDB629_Data.ReadData
            DataServices_RDB62A_Data_RData: operation=DataServices_RDB62A_Data.ReadData
            DataServices_RDB628_Data_RData: operation=DataServices_RDB628_Data.ReadData
            DataServices_RDB626_Data_RData: operation=DataServices_RDB626_Data.ReadData
            DataServices_RDB627_Data_RData: operation=DataServices_RDB627_Data.ReadData
            DataServices_RDB64B_Data_RData: operation=DataServices_RDB64B_Data.ReadData
            DataServices_RD2954_Data_RData: operation=DataServices_RD2954_Data.ReadData
            DataServices_RD201E_Data_RData: operation=DataServices_RD201E_Data.ReadData
            DataServices_RD3036_Data_RData: operation=DataServices_RD3036_Data.ReadData
            DataServices_RD100A_Data_RData: operation=DataServices_RD100A_Data.ReadData
            DataServices_RDB78B_Data_RData: operation=DataServices_RDB78B_Data.ReadData
            DataServices_RD9EED_Data_RData: operation=DataServices_RD9EED_Data.ReadData
            DataServices_RWD9E3B_Data_RData: operation=DataServices_RWD9E3B_Data.ReadData
            DataServices_RWD9E3B_Data_WData: operation=DataServices_RWD9E3B_Data.WriteData
            DataServices_RWD9E15_Data_RData: operation=DataServices_RWD9E15_Data.ReadData
            DataServices_RWD9E15_Data_WData: operation=DataServices_RWD9E15_Data.WriteData
            DataServices_RWD2800_Data_RData: operation=DataServices_RWD2800_Data.ReadData
            DataServices_RWD2800_Data_WData: operation=DataServices_RWD2800_Data.WriteData
            DataServices_RWD9E22_Data_RData: operation=DataServices_RWD9E22_Data.ReadData
            DataServices_RWD9E22_Data_WData: operation=DataServices_RWD9E22_Data.WriteData
            DataServices_RWD9E23_Data_RData: operation=DataServices_RWD9E23_Data.ReadData
            DataServices_RWD9E23_Data_WData: operation=DataServices_RWD9E23_Data.WriteData
            DataServices_RWD9E20_Data_RData: operation=DataServices_RWD9E20_Data.ReadData
            DataServices_RWD9E20_Data_WData: operation=DataServices_RWD9E20_Data.WriteData
            DataServices_RWD9E21_Data_RData: operation=DataServices_RWD9E21_Data.ReadData
            DataServices_RWD9E21_Data_WData: operation=DataServices_RWD9E21_Data.WriteData
            DataServices_RWDB607_Data_RData: operation=DataServices_RWDB607_Data.ReadData
            DataServices_RWDB607_Data_WData: operation=DataServices_RWDB607_Data.WriteData
            DataServices_RDB613_Data_RData: operation=DataServices_RDB613_Data.ReadData
            DataServices_RD400C_Data_RData: operation=DataServices_RD400C_Data.ReadData
            DataServices_RD400A_Data_RData: operation=DataServices_RD400A_Data.ReadData
            DataServices_RDB522_Data_RData: operation=DataServices_RDB522_Data.ReadData
            DataServices_RDB612_Data_RData: operation=DataServices_RDB612_Data.ReadData
            DataServices_RDB778_Data_RData: operation=DataServices_RDB778_Data.ReadData
            DataServices_RDB798_Data_RData: operation=DataServices_RDB798_Data.ReadData
            DataServices_RDB777_Data_RData: operation=DataServices_RDB777_Data.ReadData
            DataServices_RD295C_Data_RData: operation=DataServices_RD295C_Data.ReadData
            DataServices_RD295B_Data_RData: operation=DataServices_RD295B_Data.ReadData
            DataServices_RDF1C2_Data_RData: operation=DataServices_RDF1C2_Data.ReadData
            DataServices_RD2958_Data_RData: operation=DataServices_RD2958_Data.ReadData
            DataServices_RD2957_Data_RData: operation=DataServices_RD2957_Data.ReadData
            DataServices_RD295A_Data_RData: operation=DataServices_RD295A_Data.ReadData
            DataServices_RD2959_Data_RData: operation=DataServices_RD2959_Data.ReadData
            DataServices_RD4021_Data_RData: operation=DataServices_RD4021_Data.ReadData
            DataServices_RDF1B8_Data_RData: operation=DataServices_RDF1B8_Data.ReadData
            DataServices_RDB79A_Data_RData: operation=DataServices_RDB79A_Data.ReadData
            DataServices_RDB79B_Data_RData: operation=DataServices_RDB79B_Data.ReadData
            DataServices_RDB647_Data_RData: operation=DataServices_RDB647_Data.ReadData
            DataServices_RDB648_Data_RData: operation=DataServices_RDB648_Data.ReadData
            DataServices_RDB64E_Data_RData: operation=DataServices_RDB64E_Data.ReadData
            DataServices_RDF1A9_Data_RData: operation=DataServices_RDF1A9_Data.ReadData
            DataServices_RDF1A7_Data_RData: operation=DataServices_RDF1A7_Data.ReadData
            DataServices_RDF1A8_Data_RData: operation=DataServices_RDF1A8_Data.ReadData
            DataServices_RD2943_Data_RData: operation=DataServices_RD2943_Data.ReadData
            DataServices_RDB521_Data_RData: operation=DataServices_RDB521_Data.ReadData
            DataServices_RDB789_Data_RData: operation=DataServices_RDB789_Data.ReadData
            DataServices_RDB642_Data_RData: operation=DataServices_RDB642_Data.ReadData
            DataServices_RDB771_Data_RData: operation=DataServices_RDB771_Data.ReadData
            DataServices_RDF1AA_Data_RData: operation=DataServices_RDF1AA_Data.ReadData
            DataServices_RDB786_Data_RData: operation=DataServices_RDB786_Data.ReadData
            DataServices_RDB785_Data_RData: operation=DataServices_RDB785_Data.ReadData
            DataServices_RDB784_Data_RData: operation=DataServices_RDB784_Data.ReadData
            DataServices_RDB782_Data_RData: operation=DataServices_RDB782_Data.ReadData
            DataServices_RDB781_Data_RData: operation=DataServices_RDB781_Data.ReadData
            DataServices_RDB780_Data_RData: operation=DataServices_RDB780_Data.ReadData
            DataServices_RD401F_Data_RData: operation=DataServices_RD401F_Data.ReadData
            DataServices_RDB520_Data_RData: operation=DataServices_RDB520_Data.ReadData
            DataServices_RD4003_Data_RData: operation=DataServices_RD4003_Data.ReadData
            DataServices_RWD3833_Data_RData: operation=DataServices_RWD3833_Data.ReadData
            DataServices_RWD3833_Data_WData: operation=DataServices_RWD3833_Data.WriteData
            DataServices_RD2009_Data_RData: operation=DataServices_RD2009_Data.ReadData
            DataServices_RDF1BD_Data_RData: operation=DataServices_RDF1BD_Data.ReadData
            DataServices_RDF10B_Data_RData: operation=DataServices_RDF10B_Data.ReadData
            DataServices_RDF1B6_Data_RData: operation=DataServices_RDF1B6_Data.ReadData
            DataServices_RWD2969_Data_RData: operation=DataServices_RWD2969_Data.ReadData
            DataServices_RWD2969_Data_WData: operation=DataServices_RWD2969_Data.WriteData
            DataServices_RDB79D_Data_RData: operation=DataServices_RDB79D_Data.ReadData
            DataServices_RDB79C_Data_RData: operation=DataServices_RDB79C_Data.ReadData
            DataServices_RDB64C_Data_RData: operation=DataServices_RDB64C_Data.ReadData
            DataServices_RD100B_Data_RData: operation=DataServices_RD100B_Data.ReadData
            DataServices_RDB783_Data_RData: operation=DataServices_RDB783_Data.ReadData
            DataServices_RD295E_Data_RData: operation=DataServices_RD295E_Data.ReadData
            DataServices_RD295F_Data_RData: operation=DataServices_RD295F_Data.ReadData
            DataServices_RDB799_Data_RData: operation=DataServices_RDB799_Data.ReadData
            DataServices_RWDB604_Data_RData: operation=DataServices_RWDB604_Data.ReadData
            DataServices_RWDB604_Data_WData: operation=DataServices_RWDB604_Data.WriteData
            DataServices_RDB605_Data_RData: operation=DataServices_RDB605_Data.ReadData
            DataServices_RD2965_Data_RData: operation=DataServices_RD2965_Data.ReadData
            DataServices_RD2967_Data_RData: operation=DataServices_RD2967_Data.ReadData
            DataServices_RD1927_Data_RData: operation=DataServices_RD1927_Data.ReadData
            DataServices_RD295D_Data_RData: operation=DataServices_RD295D_Data.ReadData
            DataServices_RDB7BA_Data_RData: operation=DataServices_RDB7BA_Data.ReadData
            DataServices_RDF134_Data_RData: operation=DataServices_RDF134_Data.ReadData
            DataServices_RDF1C7_Data_RData: operation=DataServices_RDF1C7_Data.ReadData
            DataServices_RD102A_Data_RData: operation=DataServices_RD102A_Data.ReadData
            DataServices_RD2955_Data_RData: operation=DataServices_RD2955_Data.ReadData
            DataServices_RD2951_Data_RData: operation=DataServices_RD2951_Data.ReadData
            DataServices_RWD2966_Data_RData: operation=DataServices_RWD2966_Data.ReadData
            DataServices_RWD2966_Data_WData: operation=DataServices_RWD2966_Data.WriteData
            DataServices_RDF1C6_Data_RData: operation=DataServices_RDF1C6_Data.ReadData
            DataServices_RD2956_Data_RData: operation=DataServices_RD2956_Data.ReadData
            DataServices_RDB774_Data_RData: operation=DataServices_RDB774_Data.ReadData
            DataServices_RDB772_Data_RData: operation=DataServices_RDB772_Data.ReadData
            DataServices_RD201F_Data_RData: operation=DataServices_RD201F_Data.ReadData
            DataServices_RDB773_Data_RData: operation=DataServices_RDB773_Data.ReadData
            DataServices_RDB779_Data_RData: operation=DataServices_RDB779_Data.ReadData
            DataServices_RD2030_Data_RData: operation=DataServices_RD2030_Data.ReadData
            DataServices_RD2031_Data_RData: operation=DataServices_RD2031_Data.ReadData
            DataServices_RD0108_Data_RData: operation=DataServices_RD0108_Data.ReadData
            DataServices_RDB78A_Data_RData: operation=DataServices_RDB78A_Data.ReadData
            DataServices_RD1204_Data_RData: operation=DataServices_RD1204_Data.ReadData
            DataServices_RD1206_Data_RData: operation=DataServices_RD1206_Data.ReadData
            DataServices_RD19B{0..3}_Data_RData: operation=DataServices_RD19B{0..3}_Data.ReadData
            DataServices_RDB622_Data_RData: operation=DataServices_RDB622_Data.ReadData
            DataServices_RDB621_Data_RData: operation=DataServices_RDB621_Data.ReadData
            DataServices_RDA186_Data_RData: operation=DataServices_RDA186_Data.ReadData
            DataServices_RDB630_Data_RData: operation=DataServices_RDB630_Data.ReadData
            DataServices_RWDB62F_Data_RData: operation=DataServices_RWDB62F_Data.ReadData
            DataServices_RWDB62F_Data_WData: operation=DataServices_RWDB62F_Data.WriteData
            DataServices_RDB634_Data_RData: operation=DataServices_RDB634_Data.ReadData
            DataServices_RDB633_Data_RData: operation=DataServices_RDB633_Data.ReadData
            DataServices_RDB632_Data_RData: operation=DataServices_RDB632_Data.ReadData
            DataServices_RDB631_Data_RData: operation=DataServices_RDB631_Data.ReadData
            DataServices_WDF185_Data_WData: operation=DataServices_WDF185_Data.WriteData
            DataServices_WDF184_Data_WData: operation=DataServices_WDF184_Data.WriteData
            DataServices_WDF183_Data_WData: operation=DataServices_WDF183_Data.WriteData
            DataServices_WD2023_Data_WData: operation=DataServices_WD2023_Data.WriteData
            DataServices_IOCD046_Data_RData: operation=DataServices_IOCD046_Data.ReadData
            DataServices_IOCD046_Data_RCE: operation=DataServices_IOCD046_Data.ReturnControlToECU
            DataServices_IOCD046_Data_STA: operation=DataServices_IOCD046_Data.ShortTermAdjustment
            DataServices_IOCD045_Data_RData: operation=DataServices_IOCD045_Data.ReadData
            DataServices_IOCD045_Data_RCE: operation=DataServices_IOCD045_Data.ReturnControlToECU
            DataServices_IOCD045_Data_STA: operation=DataServices_IOCD045_Data.ShortTermAdjustment
            DataServices_IOCD042_Data_RData: operation=DataServices_IOCD042_Data.ReadData
            DataServices_IOCD042_Data_RCE: operation=DataServices_IOCD042_Data.ReturnControlToECU
            DataServices_IOCD042_Data_STA: operation=DataServices_IOCD042_Data.ShortTermAdjustment
            DataServices_IOCD033_Data_RData: operation=DataServices_IOCD033_Data.ReadData
            DataServices_IOCD033_Data_RCE: operation=DataServices_IOCD033_Data.ReturnControlToECU
            DataServices_IOCD033_Data_RD: operation=DataServices_IOCD033_Data.ResetToDefault
            DataServices_IOCD033_Data_STA: operation=DataServices_IOCD033_Data.ShortTermAdjustment
            DataServices_IOCD032_Data_RData: operation=DataServices_IOCD032_Data.ReadData
            DataServices_IOCD032_Data_RCE: operation=DataServices_IOCD032_Data.ReturnControlToECU
            DataServices_IOCD032_Data_RD: operation=DataServices_IOCD032_Data.ResetToDefault
            DataServices_IOCD032_Data_STA: operation=DataServices_IOCD032_Data.ShortTermAdjustment
            DataServices_IOCD031_Data_RData: operation=DataServices_IOCD031_Data.ReadData
            DataServices_IOCD031_Data_RCE: operation=DataServices_IOCD031_Data.ReturnControlToECU
            DataServices_IOCD031_Data_STA: operation=DataServices_IOCD031_Data.ShortTermAdjustment
            DataServices_IOCD030_Data_RData: operation=DataServices_IOCD030_Data.ReadData
            DataServices_IOCD030_Data_RCE: operation=DataServices_IOCD030_Data.ReturnControlToECU
            DataServices_IOCD030_Data_STA: operation=DataServices_IOCD030_Data.ShortTermAdjustment
            DataServices_IOCD028_Data_RData: operation=DataServices_IOCD028_Data.ReadData
            DataServices_IOCD028_Data_RCE: operation=DataServices_IOCD028_Data.ReturnControlToECU
            DataServices_IOCD028_Data_STA: operation=DataServices_IOCD028_Data.ShortTermAdjustment
            DataServices_IOCD028_Data_FCS: operation=DataServices_IOCD028_Data.FreezeCurrentState
            DataServices_IOCD027_Data_RData: operation=DataServices_IOCD027_Data.ReadData
            DataServices_IOCD027_Data_RCE: operation=DataServices_IOCD027_Data.ReturnControlToECU
            DataServices_IOCD027_Data_STA: operation=DataServices_IOCD027_Data.ShortTermAdjustment
            DataServices_IOCD026_Data_RData: operation=DataServices_IOCD026_Data.ReadData
            DataServices_IOCD026_Data_RCE: operation=DataServices_IOCD026_Data.ReturnControlToECU
            DataServices_IOCD026_Data_STA: operation=DataServices_IOCD026_Data.ShortTermAdjustment
            DataServices_IOCD025_Data_RData: operation=DataServices_IOCD025_Data.ReadData
            DataServices_IOCD025_Data_RCE: operation=DataServices_IOCD025_Data.ReturnControlToECU
            DataServices_IOCD025_Data_STA: operation=DataServices_IOCD025_Data.ShortTermAdjustment
            DataServices_IOCD023_Data_RData: operation=DataServices_IOCD023_Data.ReadData
            DataServices_IOCD023_Data_RCE: operation=DataServices_IOCD023_Data.ReturnControlToECU
            DataServices_IOCD023_Data_STA: operation=DataServices_IOCD023_Data.ShortTermAdjustment
            DataServices_IOCD022_Data_RData: operation=DataServices_IOCD022_Data.ReadData
            DataServices_IOCD022_Data_RCE: operation=DataServices_IOCD022_Data.ReturnControlToECU
            DataServices_IOCD022_Data_STA: operation=DataServices_IOCD022_Data.ShortTermAdjustment
            DataServices_IOCD020_Data_RData: operation=DataServices_IOCD020_Data.ReadData
            DataServices_IOCD020_Data_RCE: operation=DataServices_IOCD020_Data.ReturnControlToECU
            DataServices_IOCD020_Data_STA: operation=DataServices_IOCD020_Data.ShortTermAdjustment
            DataServices_IOCD01F_Data_RData: operation=DataServices_IOCD01F_Data.ReadData
            DataServices_IOCD01F_Data_RCE: operation=DataServices_IOCD01F_Data.ReturnControlToECU
            DataServices_IOCD01F_Data_RD: operation=DataServices_IOCD01F_Data.ResetToDefault
            DataServices_IOCD01F_Data_STA: operation=DataServices_IOCD01F_Data.ShortTermAdjustment
            DataServices_IOCD01E_Data_RData: operation=DataServices_IOCD01E_Data.ReadData
            DataServices_IOCD01E_Data_RCE: operation=DataServices_IOCD01E_Data.ReturnControlToECU
            DataServices_IOCD01E_Data_STA: operation=DataServices_IOCD01E_Data.ShortTermAdjustment
            DataServices_IOCD01C_Data_RData: operation=DataServices_IOCD01C_Data.ReadData
            DataServices_IOCD01C_Data_RCE: operation=DataServices_IOCD01C_Data.ReturnControlToECU
            DataServices_IOCD01C_Data_STA: operation=DataServices_IOCD01C_Data.ShortTermAdjustment
            DataServices_IOCD019_Data_RData: operation=DataServices_IOCD019_Data.ReadData
            DataServices_IOCD019_Data_RCE: operation=DataServices_IOCD019_Data.ReturnControlToECU
            DataServices_IOCD019_Data_RD: operation=DataServices_IOCD019_Data.ResetToDefault
            DataServices_IOCD019_Data_STA: operation=DataServices_IOCD019_Data.ShortTermAdjustment
            DataServices_IOCD017_Data_RData: operation=DataServices_IOCD017_Data.ReadData
            DataServices_IOCD017_Data_RCE: operation=DataServices_IOCD017_Data.ReturnControlToECU
            DataServices_IOCD017_Data_RD: operation=DataServices_IOCD017_Data.ResetToDefault
            DataServices_IOCD017_Data_STA: operation=DataServices_IOCD017_Data.ShortTermAdjustment
            DataServices_IOCD016_Data_RData: operation=DataServices_IOCD016_Data.ReadData
            DataServices_IOCD016_Data_RCE: operation=DataServices_IOCD016_Data.ReturnControlToECU
            DataServices_IOCD016_Data_STA: operation=DataServices_IOCD016_Data.ShortTermAdjustment
            DataServices_IOCD013_Data_RData: operation=DataServices_IOCD013_Data.ReadData
            DataServices_IOCD013_Data_RCE: operation=DataServices_IOCD013_Data.ReturnControlToECU
            DataServices_IOCD013_Data_RD: operation=DataServices_IOCD013_Data.ResetToDefault
            DataServices_IOCD013_Data_STA: operation=DataServices_IOCD013_Data.ShortTermAdjustment
            DataServices_IOCD012_Data_RData: operation=DataServices_IOCD012_Data.ReadData
            DataServices_IOCD012_Data_RCE: operation=DataServices_IOCD012_Data.ReturnControlToECU
            DataServices_IOCD012_Data_STA: operation=DataServices_IOCD012_Data.ShortTermAdjustment
            DataServices_IOCD00D_Data_RData: operation=DataServices_IOCD00D_Data.ReadData
            DataServices_IOCD00D_Data_RCE: operation=DataServices_IOCD00D_Data.ReturnControlToECU
            DataServices_IOCD00D_Data_RD: operation=DataServices_IOCD00D_Data.ResetToDefault
            DataServices_IOCD00D_Data_STA: operation=DataServices_IOCD00D_Data.ShortTermAdjustment
            DataServices_IOCD006_Data_RData: operation=DataServices_IOCD006_Data.ReadData
            DataServices_IOCD006_Data_RCE: operation=DataServices_IOCD006_Data.ReturnControlToECU
            DataServices_IOCD006_Data_RD: operation=DataServices_IOCD006_Data.ResetToDefault
            DataServices_IOCD006_Data_STA: operation=DataServices_IOCD006_Data.ShortTermAdjustment
            DataServices_IOCD004_Data_RData: operation=DataServices_IOCD004_Data.ReadData
            DataServices_IOCD004_Data_RCE: operation=DataServices_IOCD004_Data.ReturnControlToECU
            DataServices_IOCD004_Data_STA: operation=DataServices_IOCD004_Data.ShortTermAdjustment
            DataServices_IOCD002_Data_RData: operation=DataServices_IOCD002_Data.ReadData
            DataServices_IOCD002_Data_RCE: operation=DataServices_IOCD002_Data.ReturnControlToECU
            DataServices_IOCD002_Data_STA: operation=DataServices_IOCD002_Data.ShortTermAdjustment
            DataServices_IOCD001_Data_RData: operation=DataServices_IOCD001_Data.ReadData
            DataServices_IOCD001_Data_RCE: operation=DataServices_IOCD001_Data.ReturnControlToECU
            DataServices_IOCD001_Data_STA: operation=DataServices_IOCD001_Data.ShortTermAdjustment
            SSC_SeCa_Authenticated_Diagnostic_Access_SecurityAccess_GS: operation=SecurityAccess_Authenticated_Diagnostic_Access_SecurityAccess.GetSeed
            SSC_SeCa_Authenticated_Diagnostic_Access_SecurityAccess_CK: operation=SecurityAccess_Authenticated_Diagnostic_Access_SecurityAccess.CompareKey
            SSC_SeCa_Authenticated_Diagnostic_Access_SecurityAccess_Even_GS: operation=SecurityAccess_Authenticated_Diagnostic_Access_SecurityAccess_Even.GetSeed
            SSC_SeCa_Authenticated_Diagnostic_Access_SecurityAccess_Even_CK: operation=SecurityAccess_Authenticated_Diagnostic_Access_SecurityAccess_Even.CompareKey
            SSC_Rout_RCFF01_Start: operation=RoutineServices_RCFF01.Start
            SSC_Rout_RCFF00_Start: operation=RoutineServices_RCFF00.Start
            SSC_Rout_RCF000_Start: operation=RoutineServices_RCF000.Start
            SSC_Rout_RCD00A_Start: operation=RoutineServices_RCD00A.Start
            SSC_Rout_RCD008_Start: operation=RoutineServices_RCD008.Start
            SSC_Rout_RCD007_Start: operation=RoutineServices_RCD007.Start
            SSC_Rout_RCD006_Start: operation=RoutineServices_RCD006.Start
            SSC_Rout_RCD004_Start: operation=RoutineServices_RCD004.Start
            SSC_Rout_RCD003_Start: operation=RoutineServices_RCD003.Start
            SSC_Rout_RCD002_Start: operation=RoutineServices_RCD002.Start
            SSC_Rout_RCD001_Start: operation=RoutineServices_RCD001.Start
            SSC_Rout_RCD000_Start: operation=RoutineServices_RCD000.Start
            SSC_Rout_RC2002_Start: operation=RoutineServices_RC2002.Start
            SSC_Rout_RC2001_Start: operation=RoutineServices_RC2001.Start
            SSC_Rout_RC2000_Start: operation=RoutineServices_RC2000.Start
            SSC_Rout_RC1336_Start: operation=RoutineServices_RC1336.Start
            SSC_Rout_RC1335_Start: operation=RoutineServices_RC1335.Start
            SSC_Rout_RC1334_Start: operation=RoutineServices_RC1334.Start
            SSC_Rout_RC1333_Start: operation=RoutineServices_RC1333.Start
            SSC_Rout_RC1332_Start: operation=RoutineServices_RC1332.Start
            SSC_Rout_RC1330_Start: operation=RoutineServices_RC1330.Start
            SSC_Rout_RC1314_Start: operation=RoutineServices_RC1314.Start
            SSC_Rout_RC1313_Start: operation=RoutineServices_RC1313.Start
            SSC_Rout_RC1311_Start: operation=RoutineServices_RC1311.Start
            SSC_Rout_RC130F_Start: operation=RoutineServices_RC130F.Start
            SSC_Rout_RC130E_Start: operation=RoutineServices_RC130E.Start
            SSC_Rout_RC130D_Start: operation=RoutineServices_RC130D.Start
            SSC_Rout_RC130C_Start: operation=RoutineServices_RC130C.Start
            SSC_Rout_RC130B_Start: operation=RoutineServices_RC130B.Start
            SSC_Rout_RC1309_Start: operation=RoutineServices_RC1309.Start
            SSC_Rout_RC1303_Start: operation=RoutineServices_RC1303.Start
            SSC_Rout_RC1300_Start: operation=RoutineServices_RC1300.Start
            SSC_Rout_RC02CD_Start: operation=RoutineServices_RC02CD.Start
            SSC_Rout_RC02CC_Start: operation=RoutineServices_RC02CC.Start
            SSC_Rout_RC02C8_Start: operation=RoutineServices_RC02C8.Start
            SSC_Rout_RC02C7_Start: operation=RoutineServices_RC02C7.Start
            SSC_Rout_RC02C0_Start: operation=RoutineServices_RC02C0.Start
            SSC_Rout_RC02B2_Start: operation=RoutineServices_RC02B2.Start
            SSC_Rout_RCD001_Stop: operation=RoutineServices_RCD001.Stop
            SSC_Rout_RC1335_Stop: operation=RoutineServices_RC1335.Stop
            SSC_Rout_RC1334_Stop: operation=RoutineServices_RC1334.Stop
            SSC_Rout_RC1333_Stop: operation=RoutineServices_RC1333.Stop
            SSC_Rout_RC1332_Stop: operation=RoutineServices_RC1332.Stop
            SSC_Rout_RC1330_Stop: operation=RoutineServices_RC1330.Stop
            SSC_Rout_RC1314_Stop: operation=RoutineServices_RC1314.Stop
            SSC_Rout_RC1313_Stop: operation=RoutineServices_RC1313.Stop
            SSC_Rout_RC130D_Stop: operation=RoutineServices_RC130D.Stop
            SSC_Rout_RC130C_Stop: operation=RoutineServices_RC130C.Stop
            SSC_Rout_RC1303_Stop: operation=RoutineServices_RC1303.Stop
            SSC_Rout_RCD008_ReqRes: operation=RoutineServices_RCD008.RequestResults
            SSC_Rout_RCD007_ReqRes: operation=RoutineServices_RCD007.RequestResults
            SSC_Rout_RCD006_ReqRes: operation=RoutineServices_RCD006.RequestResults
            SSC_Rout_RC2002_ReqRes: operation=RoutineServices_RC2002.RequestResults
            SSC_Rout_RC1336_ReqRes: operation=RoutineServices_RC1336.RequestResults
            SSC_Rout_RC1335_ReqRes: operation=RoutineServices_RC1335.RequestResults
            SSC_Rout_RC1334_ReqRes: operation=RoutineServices_RC1334.RequestResults
            SSC_Rout_RC1333_ReqRes: operation=RoutineServices_RC1333.RequestResults
            SSC_Rout_RC1332_ReqRes: operation=RoutineServices_RC1332.RequestResults
            SSC_Rout_RC1330_ReqRes: operation=RoutineServices_RC1330.RequestResults
            SSC_Rout_RC1314_ReqRes: operation=RoutineServices_RC1314.RequestResults
            SSC_Rout_RC1313_ReqRes: operation=RoutineServices_RC1313.RequestResults
            SSC_Rout_RC130F_ReqRes: operation=RoutineServices_RC130F.RequestResults
            SSC_Rout_RC130E_ReqRes: operation=RoutineServices_RC130E.RequestResults
            SSC_Rout_RC130D_ReqRes: operation=RoutineServices_RC130D.RequestResults
            SSC_Rout_RC130C_ReqRes: operation=RoutineServices_RC130C.RequestResults
            SSC_Rout_RC1309_ReqRes: operation=RoutineServices_RC1309.RequestResults
            SSC_Rout_RC1303_ReqRes: operation=RoutineServices_RC1303.RequestResults
            SSC_PID_0x09_0x1C_HybrdVehGrdDat_Data_GInfoType: operation=InfotypeServices_PID_0x09_0x1C_HybrdVehGrdDat_Data.GetInfotypeValueData
            SSC_PID_0x09_0x1B_HybrdVehFuelDat_Data_GInfoType: operation=InfotypeServices_PID_0x09_0x1B_HybrdVehFuelDat_Data.GetInfotypeValueData
            SSC_PID_0x09_0x1A_HybrdVehDistDat_Data_GInfoType: operation=InfotypeServices_PID_0x09_0x1A_HybrdVehDistDat_Data.GetInfotypeValueData
            SSC_PID_0x09_0x16_VehOpeDatEngRunIdlTim_Data_GInfoType: operation=InfotypeServices_PID_0x09_0x16_VehOpeDatEngRunIdlTim_Data.GetInfotypeValueData
            SSC_PID_0x09_0x0A_ECUName_Data_GInfoType: operation=InfotypeServices_PID_0x09_0x0A_ECUName_Data.GetInfotypeValueData
            SSC_PID_0x09_0x06_CVN_Data_GInfoType: operation=InfotypeServices_PID_0x09_0x06_CVN_Data.GetInfotypeValueData
            SSC_PID_0x09_0x04_CalID_Data_GInfoType: operation=InfotypeServices_PID_0x09_0x04_CalID_Data.GetInfotypeValueData
        Dcm_GetActiveProtocol: arguments=[symbol=ActiveProtocol, symbol=ConnectionId, symbol=TesterSourceAddress], can-be-invoked-concurrently=true
        Dcm_SetActiveDiagnostic: can-be-invoked-concurrently=true
        Dcm_GetSesCtrlType: can-be-invoked-concurrently=true
        Dcm_GetSecurityLevel: can-be-invoked-concurrently=true
        Dcm_ResetToDefaultSession: can-be-invoked-concurrently=true
        Dcm_SetDeauthenticatedRole: arguments=[symbol=ConnectionId, symbol=deauthenticatedRole], can-be-invoked-concurrently=true, symbol=Dcm_SetDeauthenticatedRoleRTE
package /AUTOSAR_Dcm/SwcImplementations
  swc implementation Impl_Dcm: programming-language=C, sw-version=47.3.0.0, swc-bsw-mapping=SwcBswMappings, vendor-id=6, behavior=IntBeh_Dcm
    code-descriptors:
      code CodeDescr_Dcm: artifact-descriptors=autosar-engineering-object={short-label=Code_0, category=SWSRC}
    resource consumption Dcm_ResourceConsumption
      memory section Dcm_CODE: prefix=Dcm, sw-addrmethod=CODE, symbol=CODE
      section name prefix Dcm
package /AUTOSAR_Dcm/ImplementationDataTypes
  514 x impl type:
    Dcm_SesCtrlType: compu {1=DCM_DEFAULT_SESSION, 2=DCM_PROGRAMMING_SESSION, 3=DCM_EXTENDED_DIAGNOSTIC_SESSION, 4=DCM_SAFETY_SYSTEM_DIAGNOSTIC_SESSION}, implementation-data-type=uint8
    Dcm_NegativeResponseCodeType: compu {0=DCM_POS_RESP, 17=DCM_E_SERVICENOTSUPPORTED, 18=DCM_E_SUBFUNCTIONNOTSUPPORTED, 19=DCM_E_INCORRECTMESSAGELENGTHORINVALIDFORMAT, 20=DCM_E_RESPONSETOOLONG, 53=DCM_E_INVALIDKEY, 54=DCM_E_EXCEEDNUMBEROFATTEMPTS, 55=DCM_E_REQUIREDTIMEDELAYNOTEXPIRED, 112=DCM_E_UPLOADDOWNLOADNOTACCEPTED, 113=DCM_E_TRANSFERDATASUSPENDED, 115=DCM_E_WRONGBLOCKSEQUENCECOUNTER, 120=DCM_E_REQUESTCORRECTLYRECEIVEDRESPONSEPENDING, 127=DCM_E_SERVICENOTSUPPORTEDINACTIVESESSION, 140=DCM_E_TRANSMISSIONRANGENOTINNEUTRAL, 34=DCM_E_CONDITIONSNOTCORRECT, 16=DCM_E_GENERALREJECT, 33=DCM_E_BUSYREPEATREQUEST, 36=DCM_E_REQUESTSEQUENCEERROR, 37=DCM_E_NORESPONSEFROMSUBNETCOMPONENT, 38=DCM_E_FAILUREPREVENTSEXECUTIONOFREQUESTEDACTION, 49=DCM_E_REQUESTOUTOFRANGE, 51=DCM_E_SECURITYACCESSDENIED, 114=DCM_E_GENERALPROGRAMMINGFAILURE, 126=DCM_E_SUBFUNCTIONNOTSUPPORTEDINACTIVESESSION, 129=DCM_E_RPMTOOHIGH, 130=DCM_E_RPMTOOLOW, 131=DCM_E_ENGINEISRUNNING, 132=DCM_E_ENGINEISNOTRUNNING, 133=DCM_E_ENGINERUNTIMETOOLOW, 134=DCM_E_TEMPERATURETOOHIGH, 135=DCM_E_TEMPERATURETOOLOW, 136=DCM_E_VEHICLESPEEDTOOHIGH, 137=DCM_E_VEHICLESPEEDTOOLOW, 138=DCM_E_THROTTLE_PEDALTOOHIGH, 139=DCM_E_THROTTLE_PEDALTOOLOW, 141=DCM_E_TRANSMISSIONRANGENOTINGEAR, 146=DCM_E_VOLTAGETOOHIGH, 143=DCM_E_BRAKESWITCH_NOTCLOSED, 144=DCM_E_SHIFTERLEVERNOTINPARK, 145=DCM_E_TORQUECONVERTERCLUTCHLOCKED, 147=DCM_E_VOLTAGETOOLOW, 148=DCM_E_RESOURCETEMPORARILYNOTAVAILABLE, 240..249=DCM_E_VMSCNC_0..DCM_E_VMSCNC_9, 250=DCM_E_VMSCNC_A, 251=DCM_E_VMSCNC_B, 252=DCM_E_VMSCNC_C, 253=DCM_E_VMSCNC_D, 254=DCM_E_VMSCNC_E}, implementation-data-type=uint8
    Dcm_InputOutputControlParameterType: compu {255=DCM_IDLE, 3=DCM_SHORT_TERM_ADJUSTMENT, 2=DCM_FREEZE_CURRENT_STATE, 1=DCM_RESET_TO_DEFAULT, 0=DCM_RETURN_CONTROL_TO_ECU}, implementation-data-type=uint8
    Dcm_IOOperationResponseType: compu {255=DCM_IDLE, 0=DCM_POSITIVE_RESPONSE, 16=DCM_GENERAL_REJECT, 33=DCM_BUSY_REPEAT_REQUEST, 34=DCM_CONDITIONS_NOT_CORRECT, 38=DCM_FAILURE_PREVENTS_EXECUTION, 49=DCM_REQUEST_OUT_OF_RANGE, 120=DCM_RESPONSE_PENDING}, implementation-data-type=uint8
    Dcm_IOControlResponseType: category=STRUCTURE
      element IOOperationResponse: implementation-data-type=Dcm_IOOperationResponseType
    Dcm_DataArrayTypeUint8_IOCD014_DataType: category=ARRAY
      element DataArray: array-size=1, array-size-semantics=FIXED-SIZE, implementation-data-type=uint8
    Dcm_DataArrayTypeUint8_RDF806_DataType: category=ARRAY
      element DataArray: array-size=20, array-size-semantics=FIXED-SIZE, implementation-data-type=uint8
    Dcm_DataArrayTypeUint8_RDF804_DataType: category=ARRAY
      element DataArray: array-size=80, array-size-semantics=FIXED-SIZE, implementation-data-type=uint8
    Dcm_DataArrayTypeUint8_RDF1B5_DataType: category=ARRAY
      element DataArray: array-size=57, array-size-semantics=FIXED-SIZE, implementation-data-type=uint8
    Dcm_DataArrayTypeUint8_RDF1B4_DataType: category=ARRAY
      element DataArray: array-size=29, array-size-semantics=FIXED-SIZE, implementation-data-type=uint8
    Dcm_DataArrayTypeUint8_RDF1B3_DataType: category=ARRAY
      element DataArray: array-size=15, array-size-semantics=FIXED-SIZE, implementation-data-type=uint8
    Dcm_DataArrayTypeUint8_RDF1A6_DataType: category=ARRAY
      element DataArray: array-size=3, array-size-semantics=FIXED-SIZE, implementation-data-type=uint8
    Dcm_DataArrayTypeUint8_RDF1A4_DataType: category=ARRAY
      element DataArray: array-size=2, array-size-semantics=FIXED-SIZE, implementation-data-type=uint8
    Dcm_DataArrayTypeUint8_RDF1A3_DataType: category=ARRAY
      element DataArray: array-size=8, array-size-semantics=FIXED-SIZE, implementation-data-type=uint8
    Dcm_DataArrayTypeUint8_RDF1A1_DataType: category=ARRAY
      element DataArray: array-size=11, array-size-semantics=FIXED-SIZE, implementation-data-type=uint8
    Dcm_DataArrayTypeUint8_RDF1A0_DataType: category=ARRAY
      element DataArray: array-size=90, array-size-semantics=FIXED-SIZE, implementation-data-type=uint8
    Dcm_DataArrayTypeUint8_RDF196_DataType: category=ARRAY
      element DataArray: array-size=6, array-size-semantics=FIXED-SIZE, implementation-data-type=uint8
    Dcm_DataArrayTypeUint8_RDF195_DataType: category=ARRAY
      element DataArray: array-size=2, array-size-semantics=FIXED-SIZE, implementation-data-type=uint8
    Dcm_DataArrayTypeUint8_RDF194_DataType: category=ARRAY
      element DataArray: array-size=11, array-size-semantics=FIXED-SIZE, implementation-data-type=uint8
    Dcm_DataArrayTypeUint8_RDF193_DataType: category=ARRAY
      element DataArray: array-size=1, array-size-semantics=FIXED-SIZE, implementation-data-type=uint8
    Dcm_DataArrayTypeUint8_RDF192_DataType: category=ARRAY
      element DataArray: array-size=11, array-size-semantics=FIXED-SIZE, implementation-data-type=uint8
    Dcm_DataArrayTypeUint8_RDF191_DataType: category=ARRAY
      element DataArray: array-size=11, array-size-semantics=FIXED-SIZE, implementation-data-type=uint8
    Dcm_DataArrayTypeUint8_RDF190_DataType: category=ARRAY
      element DataArray: array-size=17, array-size-semantics=FIXED-SIZE, implementation-data-type=uint8
    Dcm_DataArrayTypeUint8_RDF18C_DataType: category=ARRAY
      element DataArray: array-size=15, array-size-semantics=FIXED-SIZE, implementation-data-type=uint8
    Dcm_DataArrayTypeUint8_RDF18B_DataType: category=ARRAY
      element DataArray: array-size=10, array-size-semantics=FIXED-SIZE, implementation-data-type=uint8
    Dcm_DataArrayTypeUint8_RDF18A_DataType: category=ARRAY
      element DataArray: array-size=10, array-size-semantics=FIXED-SIZE, implementation-data-type=uint8
    Dcm_DataArrayTypeUint8_RDF188_DataType: category=ARRAY
      element DataArray: array-size=11, array-size-semantics=FIXED-SIZE, implementation-data-type=uint8
    Dcm_DataArrayTypeUint8_RDF187_DataType: category=ARRAY
      element DataArray: array-size=11, array-size-semantics=FIXED-SIZE, implementation-data-type=uint8
    Dcm_DataArrayTypeUint8_RDF186_DataType: category=ARRAY
      element DataArray: array-size=2, array-size-semantics=FIXED-SIZE, implementation-data-type=uint8
    Dcm_DataArrayTypeUint8_RDF182_DataType: category=ARRAY
      element DataArray: array-size=53, array-size-semantics=FIXED-SIZE, implementation-data-type=uint8
    Dcm_DataArrayTypeUint8_RDF181_DataType: category=ARRAY
      element DataArray: array-size=27, array-size-semantics=FIXED-SIZE, implementation-data-type=uint8
    Dcm_DataArrayTypeUint8_RDF180_DataType: category=ARRAY
      element DataArray: array-size=14, array-size-semantics=FIXED-SIZE, implementation-data-type=uint8
    Dcm_DataArrayTypeUint8_RDF158_DataType: category=ARRAY
      element DataArray: array-size=4, array-size-semantics=FIXED-SIZE, implementation-data-type=uint8
    Dcm_DataArrayTypeUint8_RDF155_DataType: category=ARRAY
      element DataArray: array-size=2, array-size-semantics=FIXED-SIZE, implementation-data-type=uint8
    Dcm_DataArrayTypeUint8_RDF154_DataType: category=ARRAY
      element DataArray: array-size=2, array-size-semantics=FIXED-SIZE, implementation-data-type=uint8
    Dcm_DataArrayTypeUint8_RDF133_DataType: category=ARRAY
      element DataArray: array-size=10, array-size-semantics=FIXED-SIZE, implementation-data-type=uint8
    Dcm_DataArrayTypeUint8_RDF132_DataType: category=ARRAY
      element DataArray: array-size=10, array-size-semantics=FIXED-SIZE, implementation-data-type=uint8
    Dcm_DataArrayTypeUint8_RDF122_DataType: category=ARRAY
      element DataArray: array-size=20, array-size-semantics=FIXED-SIZE, implementation-data-type=uint8
    Dcm_DataArrayTypeUint8_RDF112_DataType: category=ARRAY
      element DataArray: array-size=10, array-size-semantics=FIXED-SIZE, implementation-data-type=uint8
    Dcm_DataArrayTypeUint8_RDF110_DataType: category=ARRAY
      element DataArray: array-size=10, array-size-semantics=FIXED-SIZE, implementation-data-type=uint8
    Dcm_DataArrayTypeUint8_RDF10D_DataType: category=ARRAY
      element DataArray: array-size=4, array-size-semantics=FIXED-SIZE, implementation-data-type=uint8
    Dcm_DataArrayTypeUint8_RDB526_DataType: category=ARRAY
      element DataArray: array-size=3, array-size-semantics=FIXED-SIZE, implementation-data-type=uint8
    Dcm_DataArrayTypeUint8_RDB524_DataType: category=ARRAY
      element DataArray: array-size=4, array-size-semantics=FIXED-SIZE, implementation-data-type=uint8
    Dcm_DataArrayTypeUint8_RDB523_DataType: category=ARRAY
      element DataArray: array-size=4, array-size-semantics=FIXED-SIZE, implementation-data-type=uint8
    Dcm_DataArrayTypeUint8_RDB502_DataType: category=ARRAY
      element DataArray: array-size=17, array-size-semantics=FIXED-SIZE, implementation-data-type=uint8
    Dcm_DataArrayTypeUint8_RDA132_DataType: category=ARRAY
      element DataArray: array-size=11, array-size-semantics=FIXED-SIZE, implementation-data-type=uint8
    Dcm_DataArrayTypeUint8_RWD9E00_DataType: category=ARRAY
      element DataArray: array-size=1, array-size-semantics=FIXED-SIZE, implementation-data-type=uint8
    Dcm_DataArrayTypeUint8_RD6360_DataType: category=ARRAY
      element DataArray: array-size=1, array-size-semantics=FIXED-SIZE, implementation-data-type=uint8
    Dcm_DataArrayTypeUint8_RD6340_DataType: category=ARRAY
      element DataArray: array-size=10, array-size-semantics=FIXED-SIZE, implementation-data-type=uint8
    Dcm_DataArrayTypeUint8_RD6330_DataType: category=ARRAY
      element DataArray: array-size=1, array-size-semantics=FIXED-SIZE, implementation-data-type=uint8
    Dcm_DataArrayTypeUint8_RD6320_DataType: category=ARRAY
      element DataArray: array-size=1, array-size-semantics=FIXED-SIZE, implementation-data-type=uint8
    Dcm_DataArrayTypeUint8_RD4056_DataType: category=ARRAY
      element DataArray: array-size=4, array-size-semantics=FIXED-SIZE, implementation-data-type=uint8
    Dcm_DataArrayTypeUint8_RD4055_DataType: category=ARRAY
      element DataArray: array-size=7, array-size-semantics=FIXED-SIZE, implementation-data-type=uint8
    Dcm_DataArrayTypeUint8_RD4051_DataType: category=ARRAY
      element DataArray: array-size=4, array-size-semantics=FIXED-SIZE, implementation-data-type=uint8
    Dcm_DataArrayTypeUint8_RD4050_DataType: category=ARRAY
      element DataArray: array-size=10, array-size-semantics=FIXED-SIZE, implementation-data-type=uint8
    Dcm_DataArrayTypeUint8_RD4040_DataType: category=ARRAY
      element DataArray: array-size=1, array-size-semantics=FIXED-SIZE, implementation-data-type=uint8
    Dcm_DataArrayTypeUint8_RD403D_DataType: category=ARRAY
      element DataArray: array-size=8, array-size-semantics=FIXED-SIZE, implementation-data-type=uint8
    Dcm_DataArrayTypeUint8_RD4039_DataType: category=ARRAY
      element DataArray: array-size=9, array-size-semantics=FIXED-SIZE, implementation-data-type=uint8
    Dcm_DataArrayTypeUint8_RD4037_DataType: category=ARRAY
      element DataArray: array-size=8, array-size-semantics=FIXED-SIZE, implementation-data-type=uint8
    Dcm_DataArrayTypeUint8_RD4036_DataType: category=ARRAY
      element DataArray: array-size=8, array-size-semantics=FIXED-SIZE, implementation-data-type=uint8
    Dcm_DataArrayTypeUint8_RD4022_DataType: category=ARRAY
      element DataArray: array-size=1, array-size-semantics=FIXED-SIZE, implementation-data-type=uint8
    Dcm_DataArrayTypeUint8_RDB616_DataType: category=ARRAY
      element DataArray: array-size=4, array-size-semantics=FIXED-SIZE, implementation-data-type=uint8
    Dcm_DataArrayTypeUint8_RDB614_DataType: category=ARRAY
      element DataArray: array-size=4, array-size-semantics=FIXED-SIZE, implementation-data-type=uint8
    Dcm_DataArrayTypeUint8_RD401C_DataType: category=ARRAY
      element DataArray: array-size=4, array-size-semantics=FIXED-SIZE, implementation-data-type=uint8
    Dcm_DataArrayTypeUint8_RD4016_DataType: category=ARRAY
      element DataArray: array-size=1, array-size-semantics=FIXED-SIZE, implementation-data-type=uint8
    Dcm_DataArrayTypeUint8_RD4015_DataType: category=ARRAY
      element DataArray: array-size=2, array-size-semantics=FIXED-SIZE, implementation-data-type=uint8
    Dcm_DataArrayTypeUint8_RD4014_DataType: category=ARRAY
      element DataArray: array-size=1, array-size-semantics=FIXED-SIZE, implementation-data-type=uint8
    Dcm_DataArrayTypeUint8_RD4013_DataType: category=ARRAY
      element DataArray: array-size=1, array-size-semantics=FIXED-SIZE, implementation-data-type=uint8
    Dcm_DataArrayTypeUint8_RD4012_DataType: category=ARRAY
      element DataArray: array-size=1, array-size-semantics=FIXED-SIZE, implementation-data-type=uint8
    Dcm_DataArrayTypeUint8_RD4011_DataType: category=ARRAY
      element DataArray: array-size=1, array-size-semantics=FIXED-SIZE, implementation-data-type=uint8
    Dcm_DataArrayTypeUint8_RD4010_DataType: category=ARRAY
      element DataArray: array-size=2, array-size-semantics=FIXED-SIZE, implementation-data-type=uint8
    Dcm_DataArrayTypeUint8_RD400E_DataType: category=ARRAY
      element DataArray: array-size=1, array-size-semantics=FIXED-SIZE, implementation-data-type=uint8
    Dcm_DataArrayTypeUint8_RD4004_DataType: category=ARRAY
      element DataArray: array-size=1, array-size-semantics=FIXED-SIZE, implementation-data-type=uint8
    Dcm_DataArrayTypeUint8_RD4002_DataType: category=ARRAY
      element DataArray: array-size=1, array-size-semantics=FIXED-SIZE, implementation-data-type=uint8
    Dcm_DataArrayTypeUint8_RD4001_DataType: category=ARRAY
      element DataArray: array-size=1, array-size-semantics=FIXED-SIZE, implementation-data-type=uint8
    Dcm_DataArrayTypeUint8_RD4000_DataType: category=ARRAY
      element DataArray: array-size=1, array-size-semantics=FIXED-SIZE, implementation-data-type=uint8
    Dcm_DataArrayTypeUint8_RWD3202_DataType: category=ARRAY
      element DataArray: array-size=1, array-size-semantics=FIXED-SIZE, implementation-data-type=uint8
    Dcm_DataArrayTypeUint8_RD3201_DataType: category=ARRAY
      element DataArray: array-size=1, array-size-semantics=FIXED-SIZE, implementation-data-type=uint8
    Dcm_DataArrayTypeUint8_RD3200_DataType: category=ARRAY
      element DataArray: array-size=2, array-size-semantics=FIXED-SIZE, implementation-data-type=uint8
    Dcm_DataArrayTypeUint8_RD3035_DataType: category=ARRAY
      element DataArray: array-size=3, array-size-semantics=FIXED-SIZE, implementation-data-type=uint8
    Dcm_DataArrayTypeUint8_RWD3029_DataType: category=ARRAY
      element DataArray: array-size=1, array-size-semantics=FIXED-SIZE, implementation-data-type=uint8
    Dcm_DataArrayTypeUint8_RD3028_DataType: category=ARRAY
      element DataArray: array-size=3, array-size-semantics=FIXED-SIZE, implementation-data-type=uint8
    Dcm_DataArrayTypeUint8_RD3027_DataType: category=ARRAY
      element DataArray: array-size=3, array-size-semantics=FIXED-SIZE, implementation-data-type=uint8
    Dcm_DataArrayTypeUint8_RWD3025_DataType: category=ARRAY
      element DataArray: array-size=2, array-size-semantics=FIXED-SIZE, implementation-data-type=uint8
    Dcm_DataArrayTypeUint8_RD3006_DataType: category=ARRAY
      element DataArray: array-size=1, array-size-semantics=FIXED-SIZE, implementation-data-type=uint8
    Dcm_DataArrayTypeUint8_RD3005_DataType: category=ARRAY
      element DataArray: array-size=1, array-size-semantics=FIXED-SIZE, implementation-data-type=uint8
    Dcm_DataArrayTypeUint8_RD3004_DataType: category=ARRAY
      element DataArray: array-size=6, array-size-semantics=FIXED-SIZE, implementation-data-type=uint8
    Dcm_DataArrayTypeUint8_RD3002_DataType: category=ARRAY
      element DataArray: array-size=11, array-size-semantics=FIXED-SIZE, implementation-data-type=uint8
    Dcm_DataArrayTypeUint8_RWD2945_DataType: category=ARRAY
      element DataArray: array-size=200, array-size-semantics=FIXED-SIZE, implementation-data-type=uint8
    Dcm_DataArrayTypeUint8_RD2948_DataType: category=ARRAY
      element DataArray: array-size=24, array-size-semantics=FIXED-SIZE, implementation-data-type=uint8
    Dcm_DataArrayTypeUint8_RD2947_DataType: category=ARRAY
      element DataArray: array-size=24, array-size-semantics=FIXED-SIZE, implementation-data-type=uint8
    Dcm_DataArrayTypeUint8_RD293A_DataType: category=ARRAY
      element DataArray: array-size=24, array-size-semantics=FIXED-SIZE, implementation-data-type=uint8
    Dcm_DataArrayTypeUint8_RD2802_DataType: category=ARRAY
      element DataArray: array-size=1, array-size-semantics=FIXED-SIZE, implementation-data-type=uint8
    Dcm_DataArrayTypeUint8_RD2505_DataType: category=ARRAY
      element DataArray: array-size=1, array-size-semantics=FIXED-SIZE, implementation-data-type=uint8
    Dcm_DataArrayTypeUint8_RD2500_DataType: category=ARRAY
      element DataArray: array-size=2, array-size-semantics=FIXED-SIZE, implementation-data-type=uint8
    Dcm_DataArrayTypeUint8_RDB000_DataType: category=ARRAY
      element DataArray: array-size=4, array-size-semantics=FIXED-SIZE, implementation-data-type=uint8
    Dcm_DataArrayTypeUint8_RD2026_DataType: category=ARRAY
      element DataArray: array-size=20, array-size-semantics=FIXED-SIZE, implementation-data-type=uint8
    Dcm_DataArrayTypeUint8_RD201B_DataType: category=ARRAY
      element DataArray: array-size=16, array-size-semantics=FIXED-SIZE, implementation-data-type=uint8
    Dcm_DataArrayTypeUint8_RD201A_DataType: category=ARRAY
      element DataArray: array-size=8, array-size-semantics=FIXED-SIZE, implementation-data-type=uint8
    Dcm_DataArrayTypeUint8_RD2010_DataType: category=ARRAY
      element DataArray: array-size=2, array-size-semantics=FIXED-SIZE, implementation-data-type=uint8
    Dcm_DataArrayTypeUint8_RD200C_DataType: category=ARRAY
      element DataArray: array-size=2, array-size-semantics=FIXED-SIZE, implementation-data-type=uint8
    Dcm_DataArrayTypeUint8_RD200B_DataType: category=ARRAY
      element DataArray: array-size=3, array-size-semantics=FIXED-SIZE, implementation-data-type=uint8
    Dcm_DataArrayTypeUint8_RD200A_DataType: category=ARRAY
      element DataArray: array-size=2, array-size-semantics=FIXED-SIZE, implementation-data-type=uint8
    Dcm_DataArrayTypeUint8_RD2008_DataType: category=ARRAY
      element DataArray: array-size=3, array-size-semantics=FIXED-SIZE, implementation-data-type=uint8
    Dcm_DataArrayTypeUint8_RD2003_DataType: category=ARRAY
      element DataArray: array-size=4, array-size-semantics=FIXED-SIZE, implementation-data-type=uint8
    Dcm_DataArrayTypeUint8_RD2002_DataType: category=ARRAY
      element DataArray: array-size=2, array-size-semantics=FIXED-SIZE, implementation-data-type=uint8
    Dcm_DataArrayTypeUint8_RD2001_DataType: category=ARRAY
      element DataArray: array-size=2, array-size-semantics=FIXED-SIZE, implementation-data-type=uint8
    Dcm_DataArrayTypeUint8_RD1921_DataType: category=ARRAY
      element DataArray: array-size=9, array-size-semantics=FIXED-SIZE, implementation-data-type=uint8
    Dcm_DataArrayTypeUint8_RD100C_DataType: category=ARRAY
      element DataArray: array-size=5, array-size-semantics=FIXED-SIZE, implementation-data-type=uint8
    Dcm_DataArrayTypeUint8_RD1009_DataType: category=ARRAY
      element DataArray: array-size=2, array-size-semantics=FIXED-SIZE, implementation-data-type=uint8
    Dcm_DataArrayTypeUint8_RD1008_DataType: category=ARRAY
      element DataArray: array-size=3, array-size-semantics=FIXED-SIZE, implementation-data-type=uint8
    Dcm_DataArrayTypeUint8_RD1006_DataType: category=ARRAY
      element DataArray: array-size=1, array-size-semantics=FIXED-SIZE, implementation-data-type=uint8
    Dcm_DataArrayTypeUint8_RD1004_DataType: category=ARRAY
      element DataArray: array-size=1, array-size-semantics=FIXED-SIZE, implementation-data-type=uint8
    Dcm_DataArrayTypeUint8_RD1002_DataType: category=ARRAY
      element DataArray: array-size=2, array-size-semantics=FIXED-SIZE, implementation-data-type=uint8
    Dcm_DataArrayTypeUint8_RD1000_DataType: category=ARRAY
      element DataArray: array-size=2, array-size-semantics=FIXED-SIZE, implementation-data-type=uint8
    Dcm_DataArrayTypeUint8_RD0804_DataType: category=ARRAY
      element DataArray: array-size=2, array-size-semantics=FIXED-SIZE, implementation-data-type=uint8
    Dcm_DataArrayTypeUint8_RD0803_DataType: category=ARRAY
      element DataArray: array-size=4, array-size-semantics=FIXED-SIZE, implementation-data-type=uint8
    Dcm_DataArrayTypeUint8_RD0802_DataType: category=ARRAY
      element DataArray: array-size=2, array-size-semantics=FIXED-SIZE, implementation-data-type=uint8
    Dcm_DataArrayTypeUint8_RD0703_DataType: category=ARRAY
      element DataArray: array-size=1, array-size-semantics=FIXED-SIZE, implementation-data-type=uint8
    Dcm_DataArrayTypeUint8_RD0702_DataType: category=ARRAY
      element DataArray: array-size=8, array-size-semantics=FIXED-SIZE, implementation-data-type=uint8
    Dcm_DataArrayTypeUint8_RD0701_DataType: category=ARRAY
      element DataArray: array-size=2, array-size-semantics=FIXED-SIZE, implementation-data-type=uint8
    Dcm_DataArrayTypeUint8_RD0700_DataType: category=ARRAY
      element DataArray: array-size=2, array-size-semantics=FIXED-SIZE, implementation-data-type=uint8
    Dcm_DataArrayTypeUint8_RD0507_DataType: category=ARRAY
      element DataArray: array-size=1, array-size-semantics=FIXED-SIZE, implementation-data-type=uint8
    Dcm_DataArrayTypeUint8_RD0307_DataType: category=ARRAY
      element DataArray: array-size=2, array-size-semantics=FIXED-SIZE, implementation-data-type=uint8
    Dcm_DataArrayTypeUint8_RD0306_DataType: category=ARRAY
      element DataArray: array-size=2, array-size-semantics=FIXED-SIZE, implementation-data-type=uint8
    Dcm_DataArrayTypeUint8_RD0301_DataType: category=ARRAY
      element DataArray: array-size=12, array-size-semantics=FIXED-SIZE, implementation-data-type=uint8
    Dcm_DataArrayTypeUint8_RWD0107_DataType: category=ARRAY
      element DataArray: array-size=1, array-size-semantics=FIXED-SIZE, implementation-data-type=uint8
    Dcm_DataArrayTypeUint8_RD0103_DataType: category=ARRAY
      element DataArray: array-size=2, array-size-semantics=FIXED-SIZE, implementation-data-type=uint8
    Dcm_DataArrayTypeUint8_RDB650_DataType: category=ARRAY
      element DataArray: array-size=1, array-size-semantics=FIXED-SIZE, implementation-data-type=uint8
    Dcm_DataArrayTypeUint8_RDB651_DataType: category=ARRAY
      element DataArray: array-size=4, array-size-semantics=FIXED-SIZE, implementation-data-type=uint8
    Dcm_DataArrayTypeUint8_RWDB652_DataType: category=ARRAY
      element DataArray: array-size=1, array-size-semantics=FIXED-SIZE, implementation-data-type=uint8
    Dcm_DataArrayTypeUint8_RDB776_DataType: category=ARRAY
      element DataArray: array-size=1, array-size-semantics=FIXED-SIZE, implementation-data-type=uint8
    Dcm_DataArrayTypeUint8_RDF1B0_DataType: category=ARRAY
      element DataArray: array-size=17, array-size-semantics=FIXED-SIZE, implementation-data-type=uint8
    Dcm_DataArrayTypeUint8_RDB64A_DataType: category=ARRAY
      element DataArray: array-size=3, array-size-semantics=FIXED-SIZE, implementation-data-type=uint8
    Dcm_DataArrayTypeUint8_RDB649_DataType: category=ARRAY
      element DataArray: array-size=4, array-size-semantics=FIXED-SIZE, implementation-data-type=uint8
    Dcm_DataArrayTypeUint8_RDB645_DataType: category=ARRAY
      element DataArray: array-size=7, array-size-semantics=FIXED-SIZE, implementation-data-type=uint8
    Dcm_DataArrayTypeUint8_RDB646_DataType: category=ARRAY
      element DataArray: array-size=3, array-size-semantics=FIXED-SIZE, implementation-data-type=uint8
    Dcm_DataArrayTypeUint8_RDB64D_DataType: category=ARRAY
      element DataArray: array-size=12, array-size-semantics=FIXED-SIZE, implementation-data-type=uint8
    Dcm_DataArrayTypeUint8_RDB79F_DataType: category=ARRAY
      element DataArray: array-size=2, array-size-semantics=FIXED-SIZE, implementation-data-type=uint8
    Dcm_DataArrayTypeUint8_RDB79E_DataType: category=ARRAY
      element DataArray: array-size=2, array-size-semantics=FIXED-SIZE, implementation-data-type=uint8
    Dcm_DataArrayTypeUint8_RDB78E_DataType: category=ARRAY
      element DataArray: array-size=1539, array-size-semantics=FIXED-SIZE, implementation-data-type=uint8
    Dcm_DataArrayTypeUint8_RDB78D_DataType: category=ARRAY
      element DataArray: array-size=6, array-size-semantics=FIXED-SIZE, implementation-data-type=uint8
    Dcm_DataArrayTypeUint8_RDB655_DataType: category=ARRAY
      element DataArray: array-size=4, array-size-semantics=FIXED-SIZE, implementation-data-type=uint8
    Dcm_DataArrayTypeUint8_RDB653_DataType: category=ARRAY
      element DataArray: array-size=2, array-size-semantics=FIXED-SIZE, implementation-data-type=uint8
    Dcm_DataArrayTypeUint8_RDB654_DataType: category=ARRAY
      element DataArray: array-size=2, array-size-semantics=FIXED-SIZE, implementation-data-type=uint8
    Dcm_DataArrayTypeUint8_RD191D_DataType: category=ARRAY
      element DataArray: array-size=1, array-size-semantics=FIXED-SIZE, implementation-data-type=uint8
    Dcm_DataArrayTypeUint8_RDB775_DataType: category=ARRAY
      element DataArray: array-size=1, array-size-semantics=FIXED-SIZE, implementation-data-type=uint8
    Dcm_DataArrayTypeUint8_RWDB61B_DataType: category=ARRAY
      element DataArray: array-size=1, array-size-semantics=FIXED-SIZE, implementation-data-type=uint8
    Dcm_DataArrayTypeUint8_RDB700_DataType: category=ARRAY
      element DataArray: array-size=39, array-size-semantics=FIXED-SIZE, implementation-data-type=uint8
    Dcm_DataArrayTypeUint8_RWDB701_DataType: category=ARRAY
      element DataArray: array-size=39, array-size-semantics=FIXED-SIZE, implementation-data-type=uint8
    Dcm_DataArrayTypeUint8_RDF1B7_DataType: category=ARRAY
      element DataArray: array-size=256, array-size-semantics=FIXED-SIZE, implementation-data-type=uint8
    Dcm_DataArrayTypeUint8_RDB528_DataType: category=ARRAY
      element DataArray: array-size=6, array-size-semantics=FIXED-SIZE, implementation-data-type=uint8
    Dcm_DataArrayTypeUint8_IOCD018_DataType: category=ARRAY
      element DataArray: array-size=4, array-size-semantics=FIXED-SIZE, implementation-data-type=uint8
    Dcm_DataArrayTypeUint8_RD2037_DataType: category=ARRAY
      element DataArray: array-size=4092, array-size-semantics=FIXED-SIZE, implementation-data-type=uint8
    Dcm_DataArrayTypeUint8_RD2036_DataType: category=ARRAY
      element DataArray: array-size=4092, array-size-semantics=FIXED-SIZE, implementation-data-type=uint8
    Dcm_DataArrayTypeUint8_RD2035_DataType: category=ARRAY
      element DataArray: array-size=4092, array-size-semantics=FIXED-SIZE, implementation-data-type=uint8
    Dcm_DataArrayTypeUint8_RD2034_DataType: category=ARRAY
      element DataArray: array-size=4092, array-size-semantics=FIXED-SIZE, implementation-data-type=uint8
    Dcm_DataArrayTypeUint8_RD2032_DataType: category=ARRAY
      element DataArray: array-size=4092, array-size-semantics=FIXED-SIZE, implementation-data-type=uint8
    Dcm_DataArrayTypeUint8_RDF1BC_DataType: category=ARRAY
      element DataArray: array-size=33, array-size-semantics=FIXED-SIZE, implementation-data-type=uint8
    Dcm_DataArrayTypeUint8_RDF1BB_DataType: category=ARRAY
      element DataArray: array-size=33, array-size-semantics=FIXED-SIZE, implementation-data-type=uint8
    Dcm_DataArrayTypeUint8_RDF1BA_DataType: category=ARRAY
      element DataArray: array-size=33, array-size-semantics=FIXED-SIZE, implementation-data-type=uint8
    Dcm_DataArrayTypeUint8_RDF1B9_DataType: category=ARRAY
      element DataArray: array-size=33, array-size-semantics=FIXED-SIZE, implementation-data-type=uint8
    Dcm_DataArrayTypeUint8_RWDB78C_DataType: category=ARRAY
      element DataArray: array-size=1, array-size-semantics=FIXED-SIZE, implementation-data-type=uint8
    Dcm_DataArrayTypeUint8_RWD9EEB_DataType: category=ARRAY
      element DataArray: array-size=1, array-size-semantics=FIXED-SIZE, implementation-data-type=uint8
    Dcm_DataArrayTypeUint8_RWD9EEC_DataType: category=ARRAY
      element DataArray: array-size=1, array-size-semantics=FIXED-SIZE, implementation-data-type=uint8
    Dcm_DataArrayTypeUint8_RD2024_DataType: category=ARRAY
      element DataArray: array-size=24, array-size-semantics=FIXED-SIZE, implementation-data-type=uint8
    Dcm_DataArrayTypeUint8_RDF111_DataType: category=ARRAY
      element DataArray: array-size=1, array-size-semantics=FIXED-SIZE, implementation-data-type=uint8
    Dcm_DataArrayTypeUint8_RD292E_DataType: category=ARRAY
      element DataArray: array-size=1, array-size-semantics=FIXED-SIZE, implementation-data-type=uint8
    Dcm_DataArrayTypeUint8_RD2801_DataType: category=ARRAY
      element DataArray: array-size=1, array-size-semantics=FIXED-SIZE, implementation-data-type=uint8
    Dcm_DataArrayTypeUint8_RDB62B_DataType: category=ARRAY
      element DataArray: array-size=2, array-size-semantics=FIXED-SIZE, implementation-data-type=uint8
    Dcm_DataArrayTypeUint8_RDB629_DataType: category=ARRAY
      element DataArray: array-size=8, array-size-semantics=FIXED-SIZE, implementation-data-type=uint8
    Dcm_DataArrayTypeUint8_RDB62A_DataType: category=ARRAY
      element DataArray: array-size=1, array-size-semantics=FIXED-SIZE, implementation-data-type=uint8
    Dcm_DataArrayTypeUint8_RDB628_DataType: category=ARRAY
      element DataArray: array-size=2, array-size-semantics=FIXED-SIZE, implementation-data-type=uint8
    Dcm_DataArrayTypeUint8_RDB626_DataType: category=ARRAY
      element DataArray: array-size=8, array-size-semantics=FIXED-SIZE, implementation-data-type=uint8
    Dcm_DataArrayTypeUint8_RDB627_DataType: category=ARRAY
      element DataArray: array-size=1, array-size-semantics=FIXED-SIZE, implementation-data-type=uint8
    Dcm_DataArrayTypeUint8_RDB64B_DataType: category=ARRAY
      element DataArray: array-size=1, array-size-semantics=FIXED-SIZE, implementation-data-type=uint8
    Dcm_DataArrayTypeUint8_RD2954_DataType: category=ARRAY
      element DataArray: array-size=2, array-size-semantics=FIXED-SIZE, implementation-data-type=uint8
    Dcm_DataArrayTypeUint8_RD201E_DataType: category=ARRAY
      element DataArray: array-size=2, array-size-semantics=FIXED-SIZE, implementation-data-type=uint8
    Dcm_DataArrayTypeUint8_RD3036_DataType: category=ARRAY
      element DataArray: array-size=3, array-size-semantics=FIXED-SIZE, implementation-data-type=uint8
    Dcm_DataArrayTypeUint8_RD100A_DataType: category=ARRAY
      element DataArray: array-size=5, array-size-semantics=FIXED-SIZE, implementation-data-type=uint8
    Dcm_DataArrayTypeUint8_RDB78B_DataType: category=ARRAY
      element DataArray: array-size=1, array-size-semantics=FIXED-SIZE, implementation-data-type=uint8
    Dcm_DataArrayTypeUint8_RD9EED_DataType: category=ARRAY
      element DataArray: array-size=1, array-size-semantics=FIXED-SIZE, implementation-data-type=uint8
    Dcm_DataArrayTypeUint8_RWD9E3B_DataType: category=ARRAY
      element DataArray: array-size=2, array-size-semantics=FIXED-SIZE, implementation-data-type=uint8
    Dcm_DataArrayTypeUint8_RWD9E15_DataType: category=ARRAY
      element DataArray: array-size=2, array-size-semantics=FIXED-SIZE, implementation-data-type=uint8
    Dcm_DataArrayTypeUint8_RWD2800_DataType: category=ARRAY
      element DataArray: array-size=2, array-size-semantics=FIXED-SIZE, implementation-data-type=uint8
    Dcm_DataArrayTypeUint8_RWD9E22_DataType: category=ARRAY
      element DataArray: array-size=2, array-size-semantics=FIXED-SIZE, implementation-data-type=uint8
    Dcm_DataArrayTypeUint8_RWD9E23_DataType: category=ARRAY
      element DataArray: array-size=2, array-size-semantics=FIXED-SIZE, implementation-data-type=uint8
    Dcm_DataArrayTypeUint8_RWD9E20_DataType: category=ARRAY
      element DataArray: array-size=2, array-size-semantics=FIXED-SIZE, implementation-data-type=uint8
    Dcm_DataArrayTypeUint8_RWD9E21_DataType: category=ARRAY
      element DataArray: array-size=2, array-size-semantics=FIXED-SIZE, implementation-data-type=uint8
    Dcm_DataArrayTypeUint8_RWDB607_DataType: category=ARRAY
      element DataArray: array-size=1, array-size-semantics=FIXED-SIZE, implementation-data-type=uint8
    Dcm_DataArrayTypeUint8_RDB613_DataType: category=ARRAY
      element DataArray: array-size=2, array-size-semantics=FIXED-SIZE, implementation-data-type=uint8
    Dcm_DataArrayTypeUint8_RD400C_DataType: category=ARRAY
      element DataArray: array-size=1, array-size-semantics=FIXED-SIZE, implementation-data-type=uint8
    Dcm_DataArrayTypeUint8_RD400A_DataType: category=ARRAY
      element DataArray: array-size=1, array-size-semantics=FIXED-SIZE, implementation-data-type=uint8
    Dcm_DataArrayTypeUint8_RDB522_DataType: category=ARRAY
      element DataArray: array-size=1, array-size-semantics=FIXED-SIZE, implementation-data-type=uint8
    Dcm_DataArrayTypeUint8_RDB612_DataType: category=ARRAY
      element DataArray: array-size=6, array-size-semantics=FIXED-SIZE, implementation-data-type=uint8
    Dcm_DataArrayTypeUint8_RDB778_DataType: category=ARRAY
      element DataArray: array-size=1, array-size-semantics=FIXED-SIZE, implementation-data-type=uint8
    Dcm_DataArrayTypeUint8_RDB798_DataType: category=ARRAY
      element DataArray: array-size=52, array-size-semantics=FIXED-SIZE, implementation-data-type=uint8
    Dcm_DataArrayTypeUint8_RDB777_DataType: category=ARRAY
      element DataArray: array-size=1, array-size-semantics=FIXED-SIZE, implementation-data-type=uint8
    Dcm_DataArrayTypeUint8_RD295C_DataType: category=ARRAY
      element DataArray: array-size=16, array-size-semantics=FIXED-SIZE, implementation-data-type=uint8
    Dcm_DataArrayTypeUint8_RD295B_DataType: category=ARRAY
      element DataArray: array-size=176, array-size-semantics=FIXED-SIZE, implementation-data-type=uint8
    Dcm_DataArrayTypeUint8_RDF1C2_DataType: category=ARRAY
      element DataArray: array-size=3, array-size-semantics=FIXED-SIZE, implementation-data-type=uint8
    Dcm_DataArrayTypeUint8_RD2958_DataType: category=ARRAY
      element DataArray: array-size=128, array-size-semantics=FIXED-SIZE, implementation-data-type=uint8
    Dcm_DataArrayTypeUint8_RD2957_DataType: category=ARRAY
      element DataArray: array-size=1408, array-size-semantics=FIXED-SIZE, implementation-data-type=uint8
    Dcm_DataArrayTypeUint8_RD295A_DataType: category=ARRAY
      element DataArray: array-size=96, array-size-semantics=FIXED-SIZE, implementation-data-type=uint8
    Dcm_DataArrayTypeUint8_RD2959_DataType: category=ARRAY
      element DataArray: array-size=1056, array-size-semantics=FIXED-SIZE, implementation-data-type=uint8
    Dcm_DataArrayTypeUint8_RD4021_DataType: category=ARRAY
      element DataArray: array-size=1, array-size-semantics=FIXED-SIZE, implementation-data-type=uint8
    Dcm_DataArrayTypeUint8_RDF1B8_DataType: category=ARRAY
      element DataArray: array-size=256, array-size-semantics=FIXED-SIZE, implementation-data-type=uint8
    Dcm_DataArrayTypeUint8_RDB79A_DataType: category=ARRAY
      element DataArray: array-size=4, array-size-semantics=FIXED-SIZE, implementation-data-type=uint8
    Dcm_DataArrayTypeUint8_RDB79B_DataType: category=ARRAY
      element DataArray: array-size=2, array-size-semantics=FIXED-SIZE, implementation-data-type=uint8
    Dcm_DataArrayTypeUint8_RDB647_DataType: category=ARRAY
      element DataArray: array-size=7, array-size-semantics=FIXED-SIZE, implementation-data-type=uint8
    Dcm_DataArrayTypeUint8_RDB648_DataType: category=ARRAY
      element DataArray: array-size=3, array-size-semantics=FIXED-SIZE, implementation-data-type=uint8
    Dcm_DataArrayTypeUint8_RDB64E_DataType: category=ARRAY
      element DataArray: array-size=7, array-size-semantics=FIXED-SIZE, implementation-data-type=uint8
    Dcm_DataArrayTypeUint8_RDF1A9_DataType: category=ARRAY
      element DataArray: array-size=57, array-size-semantics=FIXED-SIZE, implementation-data-type=uint8
    Dcm_DataArrayTypeUint8_RDF1A7_DataType: category=ARRAY
      element DataArray: array-size=85, array-size-semantics=FIXED-SIZE, implementation-data-type=uint8
    Dcm_DataArrayTypeUint8_RDF1A8_DataType: category=ARRAY
      element DataArray: array-size=46, array-size-semantics=FIXED-SIZE, implementation-data-type=uint8
    Dcm_DataArrayTypeUint8_RD2943_DataType: category=ARRAY
      element DataArray: array-size=24, array-size-semantics=FIXED-SIZE, implementation-data-type=uint8
    Dcm_DataArrayTypeUint8_RDB521_DataType: category=ARRAY
      element DataArray: array-size=1, array-size-semantics=FIXED-SIZE, implementation-data-type=uint8
    Dcm_DataArrayTypeUint8_RDB789_DataType: category=ARRAY
      element DataArray: array-size=2, array-size-semantics=FIXED-SIZE, implementation-data-type=uint8
    Dcm_DataArrayTypeUint8_RDB642_DataType: category=ARRAY
      element DataArray: array-size=4, array-size-semantics=FIXED-SIZE, implementation-data-type=uint8
    Dcm_DataArrayTypeUint8_RDB771_DataType: category=ARRAY
      element DataArray: array-size=1, array-size-semantics=FIXED-SIZE, implementation-data-type=uint8
    Dcm_DataArrayTypeUint8_RDF1AA_DataType: category=ARRAY
      element DataArray: array-size=11, array-size-semantics=FIXED-SIZE, implementation-data-type=uint8
    Dcm_DataArrayTypeUint8_RDB786_DataType: category=ARRAY
      element DataArray: array-size=1, array-size-semantics=FIXED-SIZE, implementation-data-type=uint8
    Dcm_DataArrayTypeUint8_RDB785_DataType: category=ARRAY
      element DataArray: array-size=6, array-size-semantics=FIXED-SIZE, implementation-data-type=uint8
    Dcm_DataArrayTypeUint8_RDB784_DataType: category=ARRAY
      element DataArray: array-size=1, array-size-semantics=FIXED-SIZE, implementation-data-type=uint8
    Dcm_DataArrayTypeUint8_RDB782_DataType: category=ARRAY
      element DataArray: array-size=2, array-size-semantics=FIXED-SIZE, implementation-data-type=uint8
    Dcm_DataArrayTypeUint8_RDB781_DataType: category=ARRAY
      element DataArray: array-size=1, array-size-semantics=FIXED-SIZE, implementation-data-type=uint8
    Dcm_DataArrayTypeUint8_RDB780_DataType: category=ARRAY
      element DataArray: array-size=1, array-size-semantics=FIXED-SIZE, implementation-data-type=uint8
    Dcm_DataArrayTypeUint8_RD401F_DataType: category=ARRAY
      element DataArray: array-size=10, array-size-semantics=FIXED-SIZE, implementation-data-type=uint8
    Dcm_DataArrayTypeUint8_RDB520_DataType: category=ARRAY
      element DataArray: array-size=1, array-size-semantics=FIXED-SIZE, implementation-data-type=uint8
    Dcm_DataArrayTypeUint8_RD4003_DataType: category=ARRAY
      element DataArray: array-size=1, array-size-semantics=FIXED-SIZE, implementation-data-type=uint8
    Dcm_DataArrayTypeUint8_RWD3833_DataType: category=ARRAY
      element DataArray: array-size=36, array-size-semantics=FIXED-SIZE, implementation-data-type=uint8
    Dcm_DataArrayTypeUint8_RD2009_DataType: category=ARRAY
      element DataArray: array-size=2, array-size-semantics=FIXED-SIZE, implementation-data-type=uint8
    Dcm_DataArrayTypeUint8_RDF1BD_DataType: category=ARRAY
      element DataArray: array-size=1, array-size-semantics=FIXED-SIZE, implementation-data-type=uint8
    Dcm_DataArrayTypeUint8_RDF10B_DataType: category=ARRAY
      element DataArray: array-size=1, array-size-semantics=FIXED-SIZE, implementation-data-type=uint8
    Dcm_DataArrayTypeUint8_RDF1B6_DataType: category=ARRAY
      element DataArray: array-size=1536, array-size-semantics=FIXED-SIZE, implementation-data-type=uint8
    Dcm_DataArrayTypeUint8_RWD2969_DataType: category=ARRAY
      element DataArray: array-size=5000, array-size-semantics=FIXED-SIZE, implementation-data-type=uint8
    Dcm_DataArrayTypeUint8_RDB79D_DataType: category=ARRAY
      element DataArray: array-size=1, array-size-semantics=FIXED-SIZE, implementation-data-type=uint8
    Dcm_DataArrayTypeUint8_RDB79C_DataType: category=ARRAY
      element DataArray: array-size=2, array-size-semantics=FIXED-SIZE, implementation-data-type=uint8
    Dcm_DataArrayTypeUint8_RDB64C_DataType: category=ARRAY
      element DataArray: array-size=1, array-size-semantics=FIXED-SIZE, implementation-data-type=uint8
    Dcm_DataArrayTypeUint8_RD100B_DataType: category=ARRAY
      element DataArray: array-size=1, array-size-semantics=FIXED-SIZE, implementation-data-type=uint8
    Dcm_DataArrayTypeUint8_RDB783_DataType: category=ARRAY
      element DataArray: array-size=1, array-size-semantics=FIXED-SIZE, implementation-data-type=uint8
    Dcm_DataArrayTypeUint8_RD295E_DataType: category=ARRAY
      element DataArray: array-size=48, array-size-semantics=FIXED-SIZE, implementation-data-type=uint8
    Dcm_DataArrayTypeUint8_RD295F_DataType: category=ARRAY
      element DataArray: array-size=528, array-size-semantics=FIXED-SIZE, implementation-data-type=uint8
    Dcm_DataArrayTypeUint8_RDB799_DataType: category=ARRAY
      element DataArray: array-size=15, array-size-semantics=FIXED-SIZE, implementation-data-type=uint8
    Dcm_DataArrayTypeUint8_RWDB604_DataType: category=ARRAY
      element DataArray: array-size=1, array-size-semantics=FIXED-SIZE, implementation-data-type=uint8
    Dcm_DataArrayTypeUint8_RDB605_DataType: category=ARRAY
      element DataArray: array-size=5, array-size-semantics=FIXED-SIZE, implementation-data-type=uint8
    Dcm_DataArrayTypeUint8_RD2965_DataType: category=ARRAY
      element DataArray: array-size=1000, array-size-semantics=FIXED-SIZE, implementation-data-type=uint8
    Dcm_DataArrayTypeUint8_RD2967_DataType: category=ARRAY
      element DataArray: array-size=2, array-size-semantics=FIXED-SIZE, implementation-data-type=uint8
    Dcm_DataArrayTypeUint8_RD1927_DataType: category=ARRAY
      element DataArray: array-size=1, array-size-semantics=FIXED-SIZE, implementation-data-type=uint8
    Dcm_DataArrayTypeUint8_RD295D_DataType: category=ARRAY
      element DataArray: array-size=176, array-size-semantics=FIXED-SIZE, implementation-data-type=uint8
    Dcm_DataArrayTypeUint8_RDB7BA_DataType: category=ARRAY
      element DataArray: array-size=4, array-size-semantics=FIXED-SIZE, implementation-data-type=uint8
    Dcm_DataArrayTypeUint8_RDF134_DataType: category=ARRAY
      element DataArray: array-size=11, array-size-semantics=FIXED-SIZE, implementation-data-type=uint8
    Dcm_DataArrayTypeUint8_RDF1C7_DataType: category=ARRAY
      element DataArray: array-size=3, array-size-semantics=FIXED-SIZE, implementation-data-type=uint8
    Dcm_DataArrayTypeUint8_RD102A_DataType: category=ARRAY
      element DataArray: array-size=9, array-size-semantics=FIXED-SIZE, implementation-data-type=uint8
    Dcm_DataArrayTypeUint8_RD2955_DataType: category=ARRAY
      element DataArray: array-size=176, array-size-semantics=FIXED-SIZE, implementation-data-type=uint8
    Dcm_DataArrayTypeUint8_RD2951_DataType: category=ARRAY
      element DataArray: array-size=16, array-size-semantics=FIXED-SIZE, implementation-data-type=uint8
    Dcm_DataArrayTypeUint8_RWD2966_DataType: category=ARRAY
      element DataArray: array-size=1, array-size-semantics=FIXED-SIZE, implementation-data-type=uint8
    Dcm_DataArrayTypeUint8_RDF1C6_DataType: category=ARRAY
      element DataArray: array-size=960, array-size-semantics=FIXED-SIZE, implementation-data-type=uint8
    Dcm_DataArrayTypeUint8_RD2956_DataType: category=ARRAY
      element DataArray: array-size=96, array-size-semantics=FIXED-SIZE, implementation-data-type=uint8
    Dcm_DataArrayTypeUint8_RDB774_DataType: category=ARRAY
      element DataArray: array-size=1, array-size-semantics=FIXED-SIZE, implementation-data-type=uint8
    Dcm_DataArrayTypeUint8_RDB772_DataType: category=ARRAY
      element DataArray: array-size=8, array-size-semantics=FIXED-SIZE, implementation-data-type=uint8
    Dcm_DataArrayTypeUint8_RD201F_DataType: category=ARRAY
      element DataArray: array-size=2, array-size-semantics=FIXED-SIZE, implementation-data-type=uint8
    Dcm_DataArrayTypeUint8_RDB773_DataType: category=ARRAY
      element DataArray: array-size=1, array-size-semantics=FIXED-SIZE, implementation-data-type=uint8
    Dcm_DataArrayTypeUint8_RDB779_DataType: category=ARRAY
      element DataArray: array-size=2, array-size-semantics=FIXED-SIZE, implementation-data-type=uint8
    Dcm_DataArrayTypeUint8_RD2030_DataType: category=ARRAY
      element DataArray: array-size=960, array-size-semantics=FIXED-SIZE, implementation-data-type=uint8
    Dcm_DataArrayTypeUint8_RD2031_DataType: category=ARRAY
      element DataArray: array-size=960, array-size-semantics=FIXED-SIZE, implementation-data-type=uint8
    Dcm_DataArrayTypeUint8_RD0108_DataType: category=ARRAY
      element DataArray: array-size=4, array-size-semantics=FIXED-SIZE, implementation-data-type=uint8
    Dcm_DataArrayTypeUint8_RDB78A_DataType: category=ARRAY
      element DataArray: array-size=1, array-size-semantics=FIXED-SIZE, implementation-data-type=uint8
    Dcm_DataArrayTypeUint8_RD1204_DataType: category=ARRAY
      element DataArray: array-size=2, array-size-semantics=FIXED-SIZE, implementation-data-type=uint8
    Dcm_DataArrayTypeUint8_RD1206_DataType: category=ARRAY
      element DataArray: array-size=2, array-size-semantics=FIXED-SIZE, implementation-data-type=uint8
    Dcm_DataArrayTypeUint8_RD19B0_DataType: category=ARRAY
      element DataArray: array-size=1, array-size-semantics=FIXED-SIZE, implementation-data-type=uint8
    Dcm_DataArrayTypeUint8_RD19B1_DataType: category=ARRAY
      element DataArray: array-size=1, array-size-semantics=FIXED-SIZE, implementation-data-type=uint8
    Dcm_DataArrayTypeUint8_RD19B2_DataType: category=ARRAY
      element DataArray: array-size=1, array-size-semantics=FIXED-SIZE, implementation-data-type=uint8
    Dcm_DataArrayTypeUint8_RD19B3_DataType: category=ARRAY
      element DataArray: array-size=1, array-size-semantics=FIXED-SIZE, implementation-data-type=uint8
    Dcm_DataArrayTypeUint8_RDB622_DataType: category=ARRAY
      element DataArray: array-size=5, array-size-semantics=FIXED-SIZE, implementation-data-type=uint8
    Dcm_DataArrayTypeUint8_RDB621_DataType: category=ARRAY
      element DataArray: array-size=4, array-size-semantics=FIXED-SIZE, implementation-data-type=uint8
    Dcm_DataArrayTypeUint8_RDA186_DataType: category=ARRAY
      element DataArray: array-size=2, array-size-semantics=FIXED-SIZE, implementation-data-type=uint8
    Dcm_DataArrayTypeUint8_RDB630_DataType: category=ARRAY
      element DataArray: array-size=2, array-size-semantics=FIXED-SIZE, implementation-data-type=uint8
    Dcm_DataArrayTypeUint8_RWDB62F_DataType: category=ARRAY
      element DataArray: array-size=1, array-size-semantics=FIXED-SIZE, implementation-data-type=uint8
    Dcm_DataArrayTypeUint8_RDB634_DataType: category=ARRAY
      element DataArray: array-size=1, array-size-semantics=FIXED-SIZE, implementation-data-type=uint8
    Dcm_DataArrayTypeUint8_RDB633_DataType: category=ARRAY
      element DataArray: array-size=10, array-size-semantics=FIXED-SIZE, implementation-data-type=uint8
    Dcm_DataArrayTypeUint8_RDB632_DataType: category=ARRAY
      element DataArray: array-size=10, array-size-semantics=FIXED-SIZE, implementation-data-type=uint8
    Dcm_DataArrayTypeUint8_RDB631_DataType: category=ARRAY
      element DataArray: array-size=10, array-size-semantics=FIXED-SIZE, implementation-data-type=uint8
    Dcm_DataArrayTypeUint8_WDF185_DataType: category=ARRAY
      element DataArray: array-size=14, array-size-semantics=FIXED-SIZE, implementation-data-type=uint8
    Dcm_DataArrayTypeUint8_WDF184_DataType: category=ARRAY
      element DataArray: array-size=14, array-size-semantics=FIXED-SIZE, implementation-data-type=uint8
    Dcm_DataArrayTypeUint8_WDF183_DataType: category=ARRAY
      element DataArray: array-size=14, array-size-semantics=FIXED-SIZE, implementation-data-type=uint8
    Dcm_DataArrayTypeUint8_WD2023_DataType: category=ARRAY
      element DataArray: array-size=255, array-size-semantics=FIXED-SIZE, implementation-data-type=uint8
    Dcm_DataArrayTypeUint8_IOCD046_DataType: category=ARRAY
      element DataArray: array-size=1, array-size-semantics=FIXED-SIZE, implementation-data-type=uint8
    Dcm_DataArrayTypeUint8_IOCD045_DataType: category=ARRAY
      element DataArray: array-size=1, array-size-semantics=FIXED-SIZE, implementation-data-type=uint8
    Dcm_DataArrayTypeUint8_IOCD042_DataType: category=ARRAY
      element DataArray: array-size=1, array-size-semantics=FIXED-SIZE, implementation-data-type=uint8
    Dcm_DataArrayTypeUint8_IOCD033_DataType: category=ARRAY
      element DataArray: array-size=2, array-size-semantics=FIXED-SIZE, implementation-data-type=uint8
    Dcm_DataArrayTypeUint8_IOCD032_DataType: category=ARRAY
      element DataArray: array-size=2, array-size-semantics=FIXED-SIZE, implementation-data-type=uint8
    Dcm_DataArrayTypeUint8_IOCD031_DataType: category=ARRAY
      element DataArray: array-size=2, array-size-semantics=FIXED-SIZE, implementation-data-type=uint8
    Dcm_DataArrayTypeUint8_IOCD030_DataType: category=ARRAY
      element DataArray: array-size=1, array-size-semantics=FIXED-SIZE, implementation-data-type=uint8
    Dcm_DataArrayTypeUint8_IOCD028_DataType: category=ARRAY
      element DataArray: array-size=1, array-size-semantics=FIXED-SIZE, implementation-data-type=uint8
    Dcm_DataArrayTypeUint8_IOCD027_DataType: category=ARRAY
      element DataArray: array-size=1, array-size-semantics=FIXED-SIZE, implementation-data-type=uint8
    Dcm_DataArrayTypeUint8_IOCD026_DataType: category=ARRAY
      element DataArray: array-size=1, array-size-semantics=FIXED-SIZE, implementation-data-type=uint8
    Dcm_DataArrayTypeUint8_IOCD025_DataType: category=ARRAY
      element DataArray: array-size=1, array-size-semantics=FIXED-SIZE, implementation-data-type=uint8
    Dcm_DataArrayTypeUint8_IOCD023_DataType: category=ARRAY
      element DataArray: array-size=1, array-size-semantics=FIXED-SIZE, implementation-data-type=uint8
    Dcm_DataArrayTypeUint8_IOCD022_DataType: category=ARRAY
      element DataArray: array-size=1, array-size-semantics=FIXED-SIZE, implementation-data-type=uint8
    Dcm_DataArrayTypeUint8_IOCD020_DataType: category=ARRAY
      element DataArray: array-size=1, array-size-semantics=FIXED-SIZE, implementation-data-type=uint8
    Dcm_DataArrayTypeUint8_IOCD01F_DataType: category=ARRAY
      element DataArray: array-size=2, array-size-semantics=FIXED-SIZE, implementation-data-type=uint8
    Dcm_DataArrayTypeUint8_IOCD01E_DataType: category=ARRAY
      element DataArray: array-size=1, array-size-semantics=FIXED-SIZE, implementation-data-type=uint8
    Dcm_DataArrayTypeUint8_IOCD01C_DataType: category=ARRAY
      element DataArray: array-size=1, array-size-semantics=FIXED-SIZE, implementation-data-type=uint8
    Dcm_DataArrayTypeUint8_IOCD019_DataType: category=ARRAY
      element DataArray: array-size=1, array-size-semantics=FIXED-SIZE, implementation-data-type=uint8
    Dcm_DataArrayTypeUint8_IOCD017_DataType: category=ARRAY
      element DataArray: array-size=1, array-size-semantics=FIXED-SIZE, implementation-data-type=uint8
    Dcm_DataArrayTypeUint8_IOCD016_DataType: category=ARRAY
      element DataArray: array-size=1, array-size-semantics=FIXED-SIZE, implementation-data-type=uint8
    Dcm_DataArrayTypeUint8_IOCD013_DataType: category=ARRAY
      element DataArray: array-size=2, array-size-semantics=FIXED-SIZE, implementation-data-type=uint8
    Dcm_DataArrayTypeUint8_IOCD012_DataType: category=ARRAY
      element DataArray: array-size=1, array-size-semantics=FIXED-SIZE, implementation-data-type=uint8
    Dcm_DataArrayTypeUint8_IOCD00D_DataType: category=ARRAY
      element DataArray: array-size=1, array-size-semantics=FIXED-SIZE, implementation-data-type=uint8
    Dcm_DataArrayTypeUint8_IOCD006_DataType: category=ARRAY
      element DataArray: array-size=2, array-size-semantics=FIXED-SIZE, implementation-data-type=uint8
    Dcm_DataArrayTypeUint8_IOCD004_DataType: category=ARRAY
      element DataArray: array-size=1, array-size-semantics=FIXED-SIZE, implementation-data-type=uint8
    Dcm_DataArrayTypeUint8_IOCD002_DataType: category=ARRAY
      element DataArray: array-size=1, array-size-semantics=FIXED-SIZE, implementation-data-type=uint8
    Dcm_DataArrayTypeUint8_IOCD001_DataType: category=ARRAY
      element DataArray: array-size=1, array-size-semantics=FIXED-SIZE, implementation-data-type=uint8
    Dcm_ConfirmationStatusType: compu {0=DCM_RES_POS_OK, 1=DCM_RES_POS_NOT_OK, 2=DCM_RES_NEG_OK, 3=DCM_RES_NEG_NOT_OK}, implementation-data-type=uint8
    Dcm_ProtocolType: compu {0=DCM_OBD_ON_CAN, 1=DCM_OBD_ON_FLEXRAY, 2=DCM_OBD_ON_IP, 3=DCM_UDS_ON_CAN, 4=DCM_UDS_ON_FLEXRAY, 5=DCM_UDS_ON_IP, 6=DCM_ROE_ON_CAN, 7=DCM_ROE_ON_FLEXRAY, 8=DCM_ROE_ON_IP, 9=DCM_PERIODICTRANS_ON_CAN, 10=DCM_PERIODICTRANS_ON_FLEXRAY, 11=DCM_PERIODICTRANS_ON_IP, 12=DCM_NO_ACTIVE_PROTOCOL, 144=DCM_ACEA_ON_CAN, 145=DCM_ACEA_ON_FLEXRAY, 128=DCM_KWP_ON_KLINE, 129=DCM_KWP_ON_CAN, 160=DCM_CARB_ON_KLINE, 161=DCM_OBD_ON_KLINE, 240..254=DCM_SUPPLIER_1..DCM_SUPPLIER_15}, implementation-data-type=uint8
    Dcm_SecLevelType: compu {1=DCM_SEC_LEV_L1, 9=Authenticated_Diagnostic_Access_SecurityAccess}, implementation-data-type=uint8
    Dcm_SecurityAccessDataRecordArray_Authenticated_Diagnostic_Access_SecurityAccessType: category=ARRAY
      element DcmDspSecurityADR_Authenticated_Diagnostic_Access_SecurityAccess: array-size=1536, array-size-semantics=FIXED-SIZE, implementation-data-type=uint8
    Dcm_SeedArray_Authenticated_Diagnostic_Access_SecurityAccessType: category=ARRAY
      element DcmDspSecuritySeedSize_Authenticated_Diagnostic_Access_SecurityAccess: array-size=32, array-size-semantics=FIXED-SIZE, implementation-data-type=uint8
    Dcm_KeyArray_Authenticated_Diagnostic_Access_SecurityAccessType: category=ARRAY
      element DcmDspSecurityKeySize_9: array-size=288, array-size-semantics=FIXED-SIZE, implementation-data-type=uint8
    Dcm_SecurityAccessDataRecordArray_Authenticated_Diagnostic_Access_SecurityAccess_EvenType: category=ARRAY
      element DcmDspSecurityADR_Authenticated_Diagnostic_Access_SecurityAccess_Even: array-size=1536, array-size-semantics=FIXED-SIZE, implementation-data-type=uint8
    Dcm_SeedArray_Authenticated_Diagnostic_Access_SecurityAccess_EvenType: category=ARRAY
      element DcmDspSecuritySeedSize_Authenticated_Diagnostic_Access_SecurityAccess_Even: array-size=32, array-size-semantics=FIXED-SIZE, implementation-data-type=uint8
    Dcm_KeyArray_Authenticated_Diagnostic_Access_SecurityAccess_EvenType: category=ARRAY
      element DcmDspSecurityKeySize_1: array-size=288, array-size-semantics=FIXED-SIZE, implementation-data-type=uint8
    Dcm_StartDataOut_RCFF01_DcmDspStartRoutineOutSignal_0Type: implementation-data-type=Dcm_StartDataOut_RCFF01_DcmDspStartRoutineOutSignal_0PrimitivType
    Dcm_StartDataOut_RCFF01_DcmDspStartRoutineOutSignal_0PrimitivType: implementation-data-type=uint8
    Dcm_StartDataOut_RCF000_DcmDspStartRoutineOutSignal_0Type: implementation-data-type=Dcm_StartDataOut_RCF000_DcmDspStartRoutineOutSignal_0PrimitivType
    Dcm_StartDataOut_RCF000_DcmDspStartRoutineOutSignal_0PrimitivType: implementation-data-type=uint8
    Dcm_StartDataOut_RCD00A_DcmDspStartRoutineOutSignal_0Type: implementation-data-type=Dcm_StartDataOut_RCD00A_DcmDspStartRoutineOutSignal_0PrimitivType
    Dcm_StartDataOut_RCD00A_DcmDspStartRoutineOutSignal_0PrimitivType: implementation-data-type=uint8
    Dcm_StartDataOut_RCD008_DcmDspStartRoutineOutSignal_0Type: implementation-data-type=Dcm_StartDataOut_RCD008_DcmDspStartRoutineOutSignal_0PrimitivType
    Dcm_StartDataOut_RCD008_DcmDspStartRoutineOutSignal_0PrimitivType: implementation-data-type=uint8
    Dcm_RequestDataOut_RCD008_DcmDspRequestRoutineResultsOutSignal_0Type: implementation-data-type=Dcm_RequestDataOut_RCD008_DcmDspRequestRoutineResultsOutSignal_0PrimitivType
    Dcm_RequestDataOut_RCD008_DcmDspRequestRoutineResultsOutSignal_0PrimitivType: implementation-data-type=uint8
    Dcm_StartDataOut_RCD007_DcmDspStartRoutineOutSignal_0Type: implementation-data-type=Dcm_StartDataOut_RCD007_DcmDspStartRoutineOutSignal_0PrimitivType
    Dcm_StartDataOut_RCD007_DcmDspStartRoutineOutSignal_0PrimitivType: implementation-data-type=uint8
    Dcm_StartDataOut_RCD006_DcmDspStartRoutineOutSignal_0Type: implementation-data-type=Dcm_StartDataOut_RCD006_DcmDspStartRoutineOutSignal_0PrimitivType
    Dcm_StartDataOut_RCD006_DcmDspStartRoutineOutSignal_0PrimitivType: implementation-data-type=uint8
    Dcm_RequestDataOut_RCD006_DcmDspRequestRoutineResultsOutSignal_0Type: implementation-data-type=Dcm_RequestDataOut_RCD006_DcmDspRequestRoutineResultsOutSignal_0PrimitivType
    Dcm_RequestDataOut_RCD006_DcmDspRequestRoutineResultsOutSignal_0PrimitivType: implementation-data-type=uint8
    Dcm_StartDataIn_RCD004_DcmDspStartRoutineInSignal_0Type: implementation-data-type=Dcm_StartDataIn_RCD004_DcmDspStartRoutineInSignal_0PrimitivType
    Dcm_StartDataIn_RCD004_DcmDspStartRoutineInSignal_0PrimitivType: implementation-data-type=uint8
    Dcm_StartDataOut_RCD004_DcmDspStartRoutineOutSignal_0Type: implementation-data-type=Dcm_StartDataOut_RCD004_DcmDspStartRoutineOutSignal_0ArrayType
    Dcm_StartDataOut_RCD004_DcmDspStartRoutineOutSignal_0ArrayType: category=ARRAY
      element DcmDspStartRoutineOutSignal_0_DataArray: array-size=20, array-size-semantics=FIXED-SIZE, implementation-data-type=uint8
    Dcm_StartDataIn_RCD003_DcmDspStartRoutineInSignal_0Type: implementation-data-type=Dcm_StartDataIn_RCD003_DcmDspStartRoutineInSignal_0PrimitivType
    Dcm_StartDataIn_RCD003_DcmDspStartRoutineInSignal_0PrimitivType: implementation-data-type=uint8
    Dcm_StartDataOut_RCD003_DcmDspStartRoutineOutSignal_0Type: implementation-data-type=Dcm_StartDataOut_RCD003_DcmDspStartRoutineOutSignal_0ArrayType
    Dcm_StartDataOut_RCD003_DcmDspStartRoutineOutSignal_0ArrayType: category=ARRAY
      element DcmDspStartRoutineOutSignal_0_DataArray: array-size=20, array-size-semantics=FIXED-SIZE, implementation-data-type=uint8
    Dcm_StartFlexibleOutArrayData_RCD002_DcmDspStartRoutineOutSignal_1Type: category=ARRAY
      element DcmDspStartRoutineOutSignal_1_DataArray: array-size=255, array-size-semantics=VARIABLE-SIZE, implementation-data-type=uint8
    Dcm_StartDataOut_RCD002_DcmDspStartRoutineOutSignal_0Type: implementation-data-type=Dcm_StartDataOut_RCD002_DcmDspStartRoutineOutSignal_0PrimitivType
    Dcm_StartDataOut_RCD002_DcmDspStartRoutineOutSignal_0PrimitivType: implementation-data-type=uint8
    Dcm_StartDataIn_RCD000_DcmDspStartRoutineInSignal_0Type: implementation-data-type=Dcm_StartDataIn_RCD000_DcmDspStartRoutineInSignal_0PrimitivType
    Dcm_StartDataIn_RCD000_DcmDspStartRoutineInSignal_0PrimitivType: implementation-data-type=uint8
    Dcm_StartDataOut_RCD000_DcmDspStartRoutineOutSignal_0Type: implementation-data-type=Dcm_StartDataOut_RCD000_DcmDspStartRoutineOutSignal_0ArrayType
    Dcm_StartDataOut_RCD000_DcmDspStartRoutineOutSignal_0ArrayType: category=ARRAY
      element DcmDspStartRoutineOutSignal_0_DataArray: array-size=20, array-size-semantics=FIXED-SIZE, implementation-data-type=uint8
    Dcm_RequestDataOut_RC2002_DcmDspRequestRoutineResultsOutSignal_{0..2}Type: implementation-data-type=Dcm_RequestDataOut_RC2002_DcmDspRequestRoutineResultsOutSignal_{0..2}PrimitivType
    Dcm_RequestDataOut_RC2002_DcmDspRequestRoutineResultsOutSignal_{0..2}PrimitivType: implementation-data-type=uint8
    Dcm_RequestDataOut_RC1336_DcmDspRequestRoutineResultsOutSignal_0Type: implementation-data-type=Dcm_RequestDataOut_RC1336_DcmDspRequestRoutineResultsOutSignal_0PrimitivType
    Dcm_RequestDataOut_RC1336_DcmDspRequestRoutineResultsOutSignal_0PrimitivType: implementation-data-type=uint8
    Dcm_StartDataIn_RC1335_DcmDspStartRoutineInSignal_{0..2}Type: implementation-data-type=Dcm_StartDataIn_RC1335_DcmDspStartRoutineInSignal_{0..2}PrimitivType
    Dcm_StartDataIn_RC1335_DcmDspStartRoutineInSignal_{0..2}PrimitivType: implementation-data-type=uint8
    Dcm_StartDataIn_RC1334_DcmDspStartRoutineInSignal_{0..2}Type: implementation-data-type=Dcm_StartDataIn_RC1334_DcmDspStartRoutineInSignal_{0..2}PrimitivType
    Dcm_StartDataIn_RC1334_DcmDspStartRoutineInSignal_{0..2}PrimitivType: implementation-data-type=uint8
    Dcm_StartDataOut_RC1333_DcmDspStartRoutineOutSignal_0Type: implementation-data-type=Dcm_StartDataOut_RC1333_DcmDspStartRoutineOutSignal_0PrimitivType
    Dcm_StartDataOut_RC1333_DcmDspStartRoutineOutSignal_0PrimitivType: implementation-data-type=uint8
    Dcm_RequestDataOut_RC1333_DcmDspRequestRoutineResultsOutSignal_0Type: implementation-data-type=Dcm_RequestDataOut_RC1333_DcmDspRequestRoutineResultsOutSignal_0PrimitivType
    Dcm_RequestDataOut_RC1333_DcmDspRequestRoutineResultsOutSignal_0PrimitivType: implementation-data-type=uint8
    Dcm_StartDataOut_RC1332_DcmDspStartRoutineOutSignal_0Type: implementation-data-type=Dcm_StartDataOut_RC1332_DcmDspStartRoutineOutSignal_0PrimitivType
    Dcm_StartDataOut_RC1332_DcmDspStartRoutineOutSignal_0PrimitivType: implementation-data-type=uint8
    Dcm_RequestDataOut_RC1332_DcmDspRequestRoutineResultsOutSignal_0Type: implementation-data-type=Dcm_RequestDataOut_RC1332_DcmDspRequestRoutineResultsOutSignal_0PrimitivType
    Dcm_RequestDataOut_RC1332_DcmDspRequestRoutineResultsOutSignal_0PrimitivType: implementation-data-type=uint8
    Dcm_RequestDataOut_RC1330_DcmDspRequestRoutineResultsOutSignal_0Type: implementation-data-type=Dcm_RequestDataOut_RC1330_DcmDspRequestRoutineResultsOutSignal_0PrimitivType
    Dcm_RequestDataOut_RC1330_DcmDspRequestRoutineResultsOutSignal_0PrimitivType: implementation-data-type=uint8
    Dcm_RequestDataOut_RC1314_DcmDspRequestRoutineResultsOutSignal_0Type: implementation-data-type=Dcm_RequestDataOut_RC1314_DcmDspRequestRoutineResultsOutSignal_0PrimitivType
    Dcm_RequestDataOut_RC1314_DcmDspRequestRoutineResultsOutSignal_0PrimitivType: implementation-data-type=uint8
    Dcm_RequestDataOut_RC1313_DcmDspRequestRoutineResultsOutSignal_0Type: implementation-data-type=Dcm_RequestDataOut_RC1313_DcmDspRequestRoutineResultsOutSignal_0PrimitivType
    Dcm_RequestDataOut_RC1313_DcmDspRequestRoutineResultsOutSignal_0PrimitivType: implementation-data-type=uint8
    Dcm_StartDataIn_RC1311_DcmDspStartRoutineInSignal_0Type: implementation-data-type=Dcm_StartDataIn_RC1311_DcmDspStartRoutineInSignal_0PrimitivType
    Dcm_StartDataIn_RC1311_DcmDspStartRoutineInSignal_0PrimitivType: implementation-data-type=uint8
    Dcm_StartDataOut_RC130F_DcmDspStartRoutineOutSignal_0Type: implementation-data-type=Dcm_StartDataOut_RC130F_DcmDspStartRoutineOutSignal_0PrimitivType
    Dcm_StartDataOut_RC130F_DcmDspStartRoutineOutSignal_0PrimitivType: implementation-data-type=uint8
    Dcm_RequestDataOut_RC130F_DcmDspRequestRoutineResultsOutSignal_0Type: implementation-data-type=Dcm_RequestDataOut_RC130F_DcmDspRequestRoutineResultsOutSignal_0PrimitivType
    Dcm_RequestDataOut_RC130F_DcmDspRequestRoutineResultsOutSignal_0PrimitivType: implementation-data-type=uint8
    Dcm_StartDataOut_RC130E_DcmDspStartRoutineOutSignal_0Type: implementation-data-type=Dcm_StartDataOut_RC130E_DcmDspStartRoutineOutSignal_0PrimitivType
    Dcm_StartDataOut_RC130E_DcmDspStartRoutineOutSignal_0PrimitivType: implementation-data-type=uint8
    Dcm_RequestDataOut_RC130E_DcmDspRequestRoutineResultsOutSignal_0Type: implementation-data-type=Dcm_RequestDataOut_RC130E_DcmDspRequestRoutineResultsOutSignal_0PrimitivType
    Dcm_RequestDataOut_RC130E_DcmDspRequestRoutineResultsOutSignal_0PrimitivType: implementation-data-type=uint8
    Dcm_StartDataOut_RC130D_DcmDspStartRoutineOutSignal_0Type: implementation-data-type=Dcm_StartDataOut_RC130D_DcmDspStartRoutineOutSignal_0PrimitivType
    Dcm_StartDataOut_RC130D_DcmDspStartRoutineOutSignal_0PrimitivType: implementation-data-type=uint8
    Dcm_RequestDataOut_RC130D_DcmDspRequestRoutineResultsOutSignal_0Type: implementation-data-type=Dcm_RequestDataOut_RC130D_DcmDspRequestRoutineResultsOutSignal_0PrimitivType
    Dcm_RequestDataOut_RC130D_DcmDspRequestRoutineResultsOutSignal_0PrimitivType: implementation-data-type=uint8
    Dcm_RequestDataOut_RC130C_DcmDspRequestRoutineResultsOutSignal_0Type: implementation-data-type=Dcm_RequestDataOut_RC130C_DcmDspRequestRoutineResultsOutSignal_0PrimitivType
    Dcm_RequestDataOut_RC130C_DcmDspRequestRoutineResultsOutSignal_0PrimitivType: implementation-data-type=uint8
    Dcm_StartDataOut_RC1309_DcmDspStartRoutineOutSignal_0Type: implementation-data-type=Dcm_StartDataOut_RC1309_DcmDspStartRoutineOutSignal_0PrimitivType
    Dcm_StartDataOut_RC1309_DcmDspStartRoutineOutSignal_0PrimitivType: implementation-data-type=uint8
    Dcm_RequestDataOut_RC1309_DcmDspRequestRoutineResultsOutSignal_0Type: implementation-data-type=Dcm_RequestDataOut_RC1309_DcmDspRequestRoutineResultsOutSignal_0PrimitivType
    Dcm_RequestDataOut_RC1309_DcmDspRequestRoutineResultsOutSignal_0PrimitivType: implementation-data-type=uint8
    Dcm_StartDataOut_RC1303_DcmDspStartRoutineOutSignal_0Type: implementation-data-type=Dcm_StartDataOut_RC1303_DcmDspStartRoutineOutSignal_0PrimitivType
    Dcm_StartDataOut_RC1303_DcmDspStartRoutineOutSignal_0PrimitivType: implementation-data-type=uint8
    Dcm_StartDataOut_RC1300_DcmDspStartRoutineOutSignal_0Type: implementation-data-type=Dcm_StartDataOut_RC1300_DcmDspStartRoutineOutSignal_0PrimitivType
    Dcm_StartDataOut_RC1300_DcmDspStartRoutineOutSignal_0PrimitivType: implementation-data-type=uint8
    Dcm_StartDataIn_RC02CD_DcmDspStartRoutineInSignal_0Type: implementation-data-type=Dcm_StartDataIn_RC02CD_DcmDspStartRoutineInSignal_0PrimitivType
    Dcm_StartDataIn_RC02CD_DcmDspStartRoutineInSignal_0PrimitivType: implementation-data-type=uint8
    Dcm_StartDataOut_RC02CD_DcmDspStartRoutineOutSignal_{0..5}Type: implementation-data-type=Dcm_StartDataOut_RC02CD_DcmDspStartRoutineOutSignal_{0..5}PrimitivType
    Dcm_StartDataOut_RC02CD_DcmDspStartRoutineOutSignal_{0..5}PrimitivType: implementation-data-type=uint8
    Dcm_StartDataIn_RC02CC_DcmDspStartRoutineInSignal_0Type: implementation-data-type=Dcm_StartDataIn_RC02CC_DcmDspStartRoutineInSignal_0PrimitivType
    Dcm_StartDataIn_RC02CC_DcmDspStartRoutineInSignal_0PrimitivType: implementation-data-type=uint8
    Dcm_StartDataOut_RC02CC_DcmDspStartRoutineOutSignal_{0..5}Type: implementation-data-type=Dcm_StartDataOut_RC02CC_DcmDspStartRoutineOutSignal_{0..5}PrimitivType
    Dcm_StartDataOut_RC02CC_DcmDspStartRoutineOutSignal_{0..5}PrimitivType: implementation-data-type=uint8
    Dcm_StartDataIn_RC02C8_DcmDspStartRoutineInSignal_0Type: implementation-data-type=Dcm_StartDataIn_RC02C8_DcmDspStartRoutineInSignal_0PrimitivType
    Dcm_StartDataIn_RC02C8_DcmDspStartRoutineInSignal_0PrimitivType: implementation-data-type=uint8
    Dcm_StartDataOut_RC02C8_DcmDspStartRoutineOutSignal_{0..3}Type: implementation-data-type=Dcm_StartDataOut_RC02C8_DcmDspStartRoutineOutSignal_{0..3}PrimitivType
    Dcm_StartDataOut_RC02C8_DcmDspStartRoutineOutSignal_{0..3}PrimitivType: implementation-data-type=uint8
    Dcm_StartDataIn_RC02C7_DcmDspStartRoutineInSignal_0Type: implementation-data-type=Dcm_StartDataIn_RC02C7_DcmDspStartRoutineInSignal_0PrimitivType
    Dcm_StartDataIn_RC02C7_DcmDspStartRoutineInSignal_0PrimitivType: implementation-data-type=uint8
    Dcm_StartDataOut_RC02C7_DcmDspStartRoutineOutSignal_{0..3}Type: implementation-data-type=Dcm_StartDataOut_RC02C7_DcmDspStartRoutineOutSignal_{0..3}PrimitivType
    Dcm_StartDataOut_RC02C7_DcmDspStartRoutineOutSignal_{0..3}PrimitivType: implementation-data-type=uint8
    Dcm_StartDataIn_RC02C0_DcmDspStartRoutineInSignal_0Type: implementation-data-type=Dcm_StartDataIn_RC02C0_DcmDspStartRoutineInSignal_0PrimitivType
    Dcm_StartDataIn_RC02C0_DcmDspStartRoutineInSignal_0PrimitivType: implementation-data-type=uint8
    Dcm_StartDataOut_RC02C0_DcmDspStartRoutineOutSignal_0Type: implementation-data-type=Dcm_StartDataOut_RC02C0_DcmDspStartRoutineOutSignal_0PrimitivType
    Dcm_StartDataOut_RC02C0_DcmDspStartRoutineOutSignal_1Type: implementation-data-type=Dcm_StartDataOut_RC02C0_DcmDspStartRoutineOutSignal_1ArrayType
    Dcm_StartDataOut_RC02C0_DcmDspStartRoutineOutSignal_{2..4}Type: implementation-data-type=Dcm_StartDataOut_RC02C0_DcmDspStartRoutineOutSignal_{2..4}PrimitivType
    Dcm_StartDataOut_RC02C0_DcmDspStartRoutineOutSignal_1ArrayType: category=ARRAY
      element DcmDspStartRoutineOutSignal_1_DataArray: array-size=2, array-size-semantics=FIXED-SIZE, implementation-data-type=uint8
    Dcm_StartDataOut_RC02C0_DcmDspStartRoutineOutSignal_0PrimitivType: implementation-data-type=uint8
    Dcm_StartDataOut_RC02C0_DcmDspStartRoutineOutSignal_{2..4}PrimitivType: implementation-data-type=uint8
    Dcm_StartDataIn_RC02B2_DcmDspStartRoutineInSignal_0Type: implementation-data-type=Dcm_StartDataIn_RC02B2_DcmDspStartRoutineInSignal_0PrimitivType
    Dcm_StartDataIn_RC02B2_DcmDspStartRoutineInSignal_1Type: implementation-data-type=Dcm_StartDataIn_RC02B2_DcmDspStartRoutineInSignal_1PrimitivType
    Dcm_StartDataIn_RC02B2_DcmDspStartRoutineInSignal_0PrimitivType: implementation-data-type=uint8
    Dcm_StartDataIn_RC02B2_DcmDspStartRoutineInSignal_1PrimitivType: implementation-data-type=uint8
    Dcm_StartDataOut_RC02B2_DcmDspStartRoutineOutSignal_{0..6}Type: implementation-data-type=Dcm_StartDataOut_RC02B2_DcmDspStartRoutineOutSignal_{0..6}PrimitivType
    Dcm_StartDataOut_RC02B2_DcmDspStartRoutineOutSignal_{0..6}PrimitivType: implementation-data-type=uint8
    Dcm_DataArrayTypeUint8_SID01PID04_Current_dataType: implementation-data-type=uint8
    Dcm_DataArrayTypeUint8_SID01PID05_Current_dataType: implementation-data-type=uint8
    Dcm_DataArrayTypeUint16_SID01PID0C_Current_dataType: implementation-data-type=uint16
    Dcm_DataArrayTypeUint8_SID01PID0D_Current_dataType: implementation-data-type=uint8
    Dcm_DataArrayTypeUint8_SID01PID33_Current_dataType: implementation-data-type=uint8
    Dcm_DataArrayTypeUint16_SID01PID42_Current_dataType: implementation-data-type=uint16
    Dcm_DataArrayTypeUint8_SID01PID46_Current_dataType: implementation-data-type=uint8
    Dcm_DataArrayTypeUint8_SID01PID49_Current_dataType: implementation-data-type=uint8
    Dcm_DataArrayTypeUint8_SID01PID5B_Current_dataType: implementation-data-type=uint8
    Dcm_DataArrayTypeUint32_SID01PID01_Current_dataType: implementation-data-type=uint32
    Dcm_DataArrayTypeUint16_SID01PID21_Current_dataType: implementation-data-type=uint16
    Dcm_DataArrayTypeUint8_SID01PID30_Current_dataType: implementation-data-type=uint8
    Dcm_DataArrayTypeUint16_SID01PID31_Current_dataType: implementation-data-type=uint16
    Dcm_DataArrayTypeUint8_SID01PID41_Current_dataType: category=ARRAY
      element ReadDataArray: array-size=8, array-size-semantics=FIXED-SIZE, implementation-data-type=uint8
    Dcm_DataArrayTypeUint8_SID01PID9A_Current_dataType: category=ARRAY
      element ReadDataArray: array-size=6, array-size-semantics=FIXED-SIZE, implementation-data-type=uint8
    Dcm_OpStatusType: compu {0=DCM_INITIAL, 1=DCM_PENDING, 2=DCM_CANCEL, 3=DCM_FORCE_RCRRP_OK}, implementation-data-type=uint8
    Dcm_DidSupportedType: compu {0=DCM_DID_SUPPORTED, 1=DCM_DID_NOT_SUPPORTED}, implementation-data-type=uint8
    Dcm_InfoTypeServicesArray_PID_0x09_0x1C_HybrdVehGrdDat_DataType: category=ARRAY
      element Dcm_InfoTypeServicesArray_PID_0x09_0x1C_HybrdVehGrdDat_DataType: array-size=24, array-size-semantics=FIXED-SIZE, implementation-data-type=uint8
    Dcm_InfoTypeServicesArray_PID_0x09_0x1B_HybrdVehFuelDat_DataType: category=ARRAY
      element Dcm_InfoTypeServicesArray_PID_0x09_0x1B_HybrdVehFuelDat_DataType: array-size=16, array-size-semantics=FIXED-SIZE, implementation-data-type=uint8
    Dcm_InfoTypeServicesArray_PID_0x09_0x1A_HybrdVehDistDat_DataType: category=ARRAY
      element Dcm_InfoTypeServicesArray_PID_0x09_0x1A_HybrdVehDistDat_DataType: array-size=24, array-size-semantics=FIXED-SIZE, implementation-data-type=uint8
    Dcm_InfoTypeServicesArray_PID_0x09_0x16_VehOpeDatEngRunIdlTim_DataType: category=ARRAY
      element Dcm_InfoTypeServicesArray_PID_0x09_0x16_VehOpeDatEngRunIdlTim_DataType: array-size=33, array-size-semantics=FIXED-SIZE, implementation-data-type=uint8
    Dcm_InfoTypeServicesArray_PID_0x09_0x0A_ECUName_DataType: category=ARRAY
      element Dcm_InfoTypeServicesArray_PID_0x09_0x0A_ECUName_DataType: array-size=21, array-size-semantics=FIXED-SIZE, implementation-data-type=uint8
    Dcm_InfoTypeServicesArray_PID_0x09_0x06_CVN_DataType: category=ARRAY
      element Dcm_InfoTypeServicesArray_PID_0x09_0x06_CVN_DataType: array-size=21, array-size-semantics=FIXED-SIZE, implementation-data-type=uint8
    Dcm_InfoTypeServicesArray_PID_0x09_0x04_CalID_DataType: category=ARRAY
      element Dcm_InfoTypeServicesArray_PID_0x09_0x04_CalID_DataType: array-size=81, array-size-semantics=FIXED-SIZE, implementation-data-type=uint8
package /AUTOSAR_Dcm/DataTypeMappingSets
  6 x data type mapping set:
    DTS_DcmDiagnosticSessionControl: mode-request-type-map{implementation-data-type=uint8, mode-group=DcmDiagnosticSessionControl}
    DTS_DcmEcuReset: mode-request-type-map{implementation-data-type=uint8, mode-group=DcmEcuReset}
    DTS_DcmControlDTCSetting: mode-request-type-map{implementation-data-type=uint8, mode-group=DcmControlDTCSetting}
    DTS_DcmCommunicationControl_Can_Network_CANFD_3: mode-request-type-map{implementation-data-type=uint8, mode-group=DcmCommunicationControl_Can_Network_CANFD_3}
    DTS_DcmCommunicationControl_Can_Network_CANFD_11: mode-request-type-map{implementation-data-type=uint8, mode-group=DcmCommunicationControl_Can_Network_CANFD_11}
    DTS_DcmCommunicationControl_Can_Network_CANFD_16: mode-request-type-map{implementation-data-type=uint8, mode-group=DcmCommunicationControl_Can_Network_CANFD_16}
package /AUTOSAR_Dcm/SwcBswMappings
  swc bsw mapping SwcBswMappings: bsw-behavior=BswInternalBehavior, swc-bsw-runnable-mapping{bsw-entity=BSWSE_DcmMainFunction, swc-runnable=Dcm_MainFunction}, swc-behavior=IntBeh_Dcm
    synchronized-mode-groups:
      bsw-mode-group=DcmDiagnosticSessionControl, swc-mode-group=Pp_DcmDiagnosticSessionControl.MDGP_DcmDiagnosticSessionControl
      bsw-mode-group=DcmEcuReset, swc-mode-group=Pp_DcmEcuReset.MDGP_DcmEcuReset
      bsw-mode-group=DcmControlDTCSetting, swc-mode-group=Pp_DcmControlDTCSetting.MDGP_DcmControlDTCSetting
      bsw-mode-group=DcmCommunicationControl_Can_Network_CANFD_3, swc-mode-group=Pp_DcmCommunicationControl_Can_Network_CANFD_3.MDGP_DcmCommunicationControl_Can_Network_CANFD_3
      bsw-mode-group=DcmCommunicationControl_Can_Network_CANFD_11, swc-mode-group=Pp_DcmCommunicationControl_Can_Network_CANFD_11.MDGP_DcmCommunicationControl_Can_Network_CANFD_11
      bsw-mode-group=DcmCommunicationControl_Can_Network_CANFD_16, swc-mode-group=Pp_DcmCommunicationControl_Can_Network_CANFD_16.MDGP_DcmCommunicationControl_Can_Network_CANFD_16
package /AUTOSAR_Dcm/PortInterfaces
  15 x sender receiver interface:
    DataServices_SID01PID04_Current_data
      data Data: type=Dcm_DataArrayTypeUint8_SID01PID04_Current_dataType
    DataServices_SID01PID05_Current_data
      data Data: type=Dcm_DataArrayTypeUint8_SID01PID05_Current_dataType
    DataServices_SID01PID0C_Current_data
      data Data: type=Dcm_DataArrayTypeUint16_SID01PID0C_Current_dataType
    DataServices_SID01PID0D_Current_data
      data Data: type=Dcm_DataArrayTypeUint8_SID01PID0D_Current_dataType
    DataServices_SID01PID33_Current_data
      data Data: type=Dcm_DataArrayTypeUint8_SID01PID33_Current_dataType
    DataServices_SID01PID42_Current_data
      data Data: type=Dcm_DataArrayTypeUint16_SID01PID42_Current_dataType
    DataServices_SID01PID46_Current_data
      data Data: type=Dcm_DataArrayTypeUint8_SID01PID46_Current_dataType
    DataServices_SID01PID49_Current_data
      data Data: type=Dcm_DataArrayTypeUint8_SID01PID49_Current_dataType
    DataServices_SID01PID5B_Current_data
      data Data: type=Dcm_DataArrayTypeUint8_SID01PID5B_Current_dataType
    DataServices_SID01PID01_Current_data
      data Data: type=Dcm_DataArrayTypeUint32_SID01PID01_Current_dataType
    DataServices_SID01PID21_Current_data
      data Data: type=Dcm_DataArrayTypeUint16_SID01PID21_Current_dataType
    DataServices_SID01PID30_Current_data
      data Data: type=Dcm_DataArrayTypeUint8_SID01PID30_Current_dataType
    DataServices_SID01PID31_Current_data
      data Data: type=Dcm_DataArrayTypeUint16_SID01PID31_Current_dataType
    DataServices_SID01PID41_Current_data
      data Data: type=Dcm_DataArrayTypeUint8_SID01PID41_Current_dataType
    DataServices_SID01PID9A_Current_data
      data Data: type=Dcm_DataArrayTypeUint8_SID01PID9A_Current_dataType
  357 x client server interface, all with is-service=true:
    DataServices_IOCD014_Data
      4 x operation:
        ReadData: possible-error=[DataServices_IOCD014_Data/E_OK, DataServices_IOCD014_Data/E_NOT_OK, DataServices_IOCD014_Data/DCM_E_PENDING]
          arg OpStatus: type=Dcm_OpStatusType, direction=IN
          arg Data: type=Dcm_DataArrayTypeUint8_IOCD014_DataType, direction=OUT
        ReturnControlToECU: possible-error=[DataServices_IOCD014_Data/E_OK, DataServices_IOCD014_Data/E_NOT_OK]
          arg ErrorCode: type=Dcm_NegativeResponseCodeType, direction=OUT
        ResetToDefault: possible-error=[DataServices_IOCD014_Data/E_OK, DataServices_IOCD014_Data/E_NOT_OK, DataServices_IOCD014_Data/DCM_E_PENDING]
          arg OpStatus: type=Dcm_OpStatusType, direction=IN
          arg ErrorCode: type=Dcm_NegativeResponseCodeType, direction=OUT
        ShortTermAdjustment: possible-error=[DataServices_IOCD014_Data/E_OK, DataServices_IOCD014_Data/E_NOT_OK, DataServices_IOCD014_Data/DCM_E_PENDING]
          arg ControlStateInfo: type=Dcm_DataArrayTypeUint8_IOCD014_DataType, direction=IN
          arg OpStatus: type=Dcm_OpStatusType, direction=IN
          arg ErrorCode: type=Dcm_NegativeResponseCodeType, direction=OUT
      error E_OK: error-code=0
      error E_NOT_OK: error-code=1
      error DCM_E_PENDING: error-code=10
    DataServices_RDF806_Data
      operation ReadData: possible-error=[DataServices_RDF806_Data/E_OK, DataServices_RDF806_Data/E_NOT_OK, DataServices_RDF806_Data/DCM_E_PENDING]
        arg OpStatus: type=Dcm_OpStatusType, direction=IN
        arg Data: type=Dcm_DataArrayTypeUint8_RDF806_DataType, direction=OUT
      error E_OK: error-code=0
      error E_NOT_OK: error-code=1
      error DCM_E_PENDING: error-code=10
    DataServices_RDF804_Data
      operation ReadData: possible-error=[DataServices_RDF804_Data/E_OK, DataServices_RDF804_Data/E_NOT_OK, DataServices_RDF804_Data/DCM_E_PENDING]
        arg OpStatus: type=Dcm_OpStatusType, direction=IN
        arg Data: type=Dcm_DataArrayTypeUint8_RDF804_DataType, direction=OUT
      error E_OK: error-code=0
      error E_NOT_OK: error-code=1
      error DCM_E_PENDING: error-code=10
    DataServices_RDF1B5_Data
      operation ReadData: possible-error=[DataServices_RDF1B5_Data/E_OK, DataServices_RDF1B5_Data/E_NOT_OK, DataServices_RDF1B5_Data/DCM_E_PENDING]
        arg OpStatus: type=Dcm_OpStatusType, direction=IN
        arg Data: type=Dcm_DataArrayTypeUint8_RDF1B5_DataType, direction=OUT
      error E_OK: error-code=0
      error E_NOT_OK: error-code=1
      error DCM_E_PENDING: error-code=10
    DataServices_RDF1B4_Data
      operation ReadData: possible-error=[DataServices_RDF1B4_Data/E_OK, DataServices_RDF1B4_Data/E_NOT_OK, DataServices_RDF1B4_Data/DCM_E_PENDING]
        arg OpStatus: type=Dcm_OpStatusType, direction=IN
        arg Data: type=Dcm_DataArrayTypeUint8_RDF1B4_DataType, direction=OUT
      error E_OK: error-code=0
      error E_NOT_OK: error-code=1
      error DCM_E_PENDING: error-code=10
    DataServices_RDF1B3_Data
      operation ReadData: possible-error=[DataServices_RDF1B3_Data/E_OK, DataServices_RDF1B3_Data/E_NOT_OK, DataServices_RDF1B3_Data/DCM_E_PENDING]
        arg OpStatus: type=Dcm_OpStatusType, direction=IN
        arg Data: type=Dcm_DataArrayTypeUint8_RDF1B3_DataType, direction=OUT
      error E_OK: error-code=0
      error E_NOT_OK: error-code=1
      error DCM_E_PENDING: error-code=10
    DataServices_RDF1A6_Data
      operation ReadData: possible-error=[DataServices_RDF1A6_Data/E_OK, DataServices_RDF1A6_Data/E_NOT_OK, DataServices_RDF1A6_Data/DCM_E_PENDING]
        arg OpStatus: type=Dcm_OpStatusType, direction=IN
        arg Data: type=Dcm_DataArrayTypeUint8_RDF1A6_DataType, direction=OUT
      error E_OK: error-code=0
      error E_NOT_OK: error-code=1
      error DCM_E_PENDING: error-code=10
    DataServices_RDF1A4_Data
      operation ReadData: possible-error=[DataServices_RDF1A4_Data/E_OK, DataServices_RDF1A4_Data/E_NOT_OK, DataServices_RDF1A4_Data/DCM_E_PENDING]
        arg OpStatus: type=Dcm_OpStatusType, direction=IN
        arg Data: type=Dcm_DataArrayTypeUint8_RDF1A4_DataType, direction=OUT
      error E_OK: error-code=0
      error E_NOT_OK: error-code=1
      error DCM_E_PENDING: error-code=10
    DataServices_RDF1A3_Data
      operation ReadData: possible-error=[DataServices_RDF1A3_Data/E_OK, DataServices_RDF1A3_Data/E_NOT_OK, DataServices_RDF1A3_Data/DCM_E_PENDING]
        arg OpStatus: type=Dcm_OpStatusType, direction=IN
        arg Data: type=Dcm_DataArrayTypeUint8_RDF1A3_DataType, direction=OUT
      error E_OK: error-code=0
      error E_NOT_OK: error-code=1
      error DCM_E_PENDING: error-code=10
    DataServices_RDF1A1_Data
      operation ReadData: possible-error=[DataServices_RDF1A1_Data/E_OK, DataServices_RDF1A1_Data/E_NOT_OK, DataServices_RDF1A1_Data/DCM_E_PENDING]
        arg OpStatus: type=Dcm_OpStatusType, direction=IN
        arg Data: type=Dcm_DataArrayTypeUint8_RDF1A1_DataType, direction=OUT
      error E_OK: error-code=0
      error E_NOT_OK: error-code=1
      error DCM_E_PENDING: error-code=10
    DataServices_RDF1A0_Data
      operation ReadData: possible-error=[DataServices_RDF1A0_Data/E_OK, DataServices_RDF1A0_Data/E_NOT_OK, DataServices_RDF1A0_Data/DCM_E_PENDING]
        arg OpStatus: type=Dcm_OpStatusType, direction=IN
        arg Data: type=Dcm_DataArrayTypeUint8_RDF1A0_DataType, direction=OUT
      error E_OK: error-code=0
      error E_NOT_OK: error-code=1
      error DCM_E_PENDING: error-code=10
    DataServices_RDF196_Data
      operation ReadData: possible-error=[DataServices_RDF196_Data/E_OK, DataServices_RDF196_Data/E_NOT_OK, DataServices_RDF196_Data/DCM_E_PENDING]
        arg OpStatus: type=Dcm_OpStatusType, direction=IN
        arg Data: type=Dcm_DataArrayTypeUint8_RDF196_DataType, direction=OUT
      error E_OK: error-code=0
      error E_NOT_OK: error-code=1
      error DCM_E_PENDING: error-code=10
    DataServices_RDF195_Data
      operation ReadData: possible-error=[DataServices_RDF195_Data/E_OK, DataServices_RDF195_Data/E_NOT_OK, DataServices_RDF195_Data/DCM_E_PENDING]
        arg OpStatus: type=Dcm_OpStatusType, direction=IN
        arg Data: type=Dcm_DataArrayTypeUint8_RDF195_DataType, direction=OUT
      error E_OK: error-code=0
      error E_NOT_OK: error-code=1
      error DCM_E_PENDING: error-code=10
    DataServices_RDF194_Data
      operation ReadData: possible-error=[DataServices_RDF194_Data/E_OK, DataServices_RDF194_Data/E_NOT_OK, DataServices_RDF194_Data/DCM_E_PENDING]
        arg OpStatus: type=Dcm_OpStatusType, direction=IN
        arg Data: type=Dcm_DataArrayTypeUint8_RDF194_DataType, direction=OUT
      error E_OK: error-code=0
      error E_NOT_OK: error-code=1
      error DCM_E_PENDING: error-code=10
    DataServices_RDF193_Data
      operation ReadData: possible-error=[DataServices_RDF193_Data/E_OK, DataServices_RDF193_Data/E_NOT_OK, DataServices_RDF193_Data/DCM_E_PENDING]
        arg OpStatus: type=Dcm_OpStatusType, direction=IN
        arg Data: type=Dcm_DataArrayTypeUint8_RDF193_DataType, direction=OUT
      error E_OK: error-code=0
      error E_NOT_OK: error-code=1
      error DCM_E_PENDING: error-code=10
    DataServices_RDF192_Data
      operation ReadData: possible-error=[DataServices_RDF192_Data/E_OK, DataServices_RDF192_Data/E_NOT_OK, DataServices_RDF192_Data/DCM_E_PENDING]
        arg OpStatus: type=Dcm_OpStatusType, direction=IN
        arg Data: type=Dcm_DataArrayTypeUint8_RDF192_DataType, direction=OUT
      error E_OK: error-code=0
      error E_NOT_OK: error-code=1
      error DCM_E_PENDING: error-code=10
    DataServices_RDF191_Data
      operation ReadData: possible-error=[DataServices_RDF191_Data/E_OK, DataServices_RDF191_Data/E_NOT_OK, DataServices_RDF191_Data/DCM_E_PENDING]
        arg OpStatus: type=Dcm_OpStatusType, direction=IN
        arg Data: type=Dcm_DataArrayTypeUint8_RDF191_DataType, direction=OUT
      error E_OK: error-code=0
      error E_NOT_OK: error-code=1
      error DCM_E_PENDING: error-code=10
    DataServices_RDF190_Data
      operation ReadData: possible-error=[DataServices_RDF190_Data/E_OK, DataServices_RDF190_Data/E_NOT_OK, DataServices_RDF190_Data/DCM_E_PENDING]
        arg OpStatus: type=Dcm_OpStatusType, direction=IN
        arg Data: type=Dcm_DataArrayTypeUint8_RDF190_DataType, direction=OUT
      error E_OK: error-code=0
      error E_NOT_OK: error-code=1
      error DCM_E_PENDING: error-code=10
    DataServices_RDF18C_Data
      operation ReadData: possible-error=[DataServices_RDF18C_Data/E_OK, DataServices_RDF18C_Data/E_NOT_OK, DataServices_RDF18C_Data/DCM_E_PENDING]
        arg OpStatus: type=Dcm_OpStatusType, direction=IN
        arg Data: type=Dcm_DataArrayTypeUint8_RDF18C_DataType, direction=OUT
      error E_OK: error-code=0
      error E_NOT_OK: error-code=1
      error DCM_E_PENDING: error-code=10
    DataServices_RDF18B_Data
      operation ReadData: possible-error=[DataServices_RDF18B_Data/E_OK, DataServices_RDF18B_Data/E_NOT_OK, DataServices_RDF18B_Data/DCM_E_PENDING]
        arg OpStatus: type=Dcm_OpStatusType, direction=IN
        arg Data: type=Dcm_DataArrayTypeUint8_RDF18B_DataType, direction=OUT
      error E_OK: error-code=0
      error E_NOT_OK: error-code=1
      error DCM_E_PENDING: error-code=10
    DataServices_RDF18A_Data
      operation ReadData: possible-error=[DataServices_RDF18A_Data/E_OK, DataServices_RDF18A_Data/E_NOT_OK, DataServices_RDF18A_Data/DCM_E_PENDING]
        arg OpStatus: type=Dcm_OpStatusType, direction=IN
        arg Data: type=Dcm_DataArrayTypeUint8_RDF18A_DataType, direction=OUT
      error E_OK: error-code=0
      error E_NOT_OK: error-code=1
      error DCM_E_PENDING: error-code=10
    DataServices_RDF188_Data
      operation ReadData: possible-error=[DataServices_RDF188_Data/E_OK, DataServices_RDF188_Data/E_NOT_OK, DataServices_RDF188_Data/DCM_E_PENDING]
        arg OpStatus: type=Dcm_OpStatusType, direction=IN
        arg Data: type=Dcm_DataArrayTypeUint8_RDF188_DataType, direction=OUT
      error E_OK: error-code=0
      error E_NOT_OK: error-code=1
      error DCM_E_PENDING: error-code=10
    DataServices_RDF187_Data
      operation ReadData: possible-error=[DataServices_RDF187_Data/E_OK, DataServices_RDF187_Data/E_NOT_OK, DataServices_RDF187_Data/DCM_E_PENDING]
        arg OpStatus: type=Dcm_OpStatusType, direction=IN
        arg Data: type=Dcm_DataArrayTypeUint8_RDF187_DataType, direction=OUT
      error E_OK: error-code=0
      error E_NOT_OK: error-code=1
      error DCM_E_PENDING: error-code=10
